VERSION ""

NS_ :

BS_:

BU_: WCM4 WCM3 WCM2 WCM VPM VLM VKM VICM VECM VDM VCU_RTOS_ETH VCU_ENTRY_ETH VCU_AGVM_ETH VCU UVM UPM TIM TEST_TOOL_1 TCP_ETH TCP TCM TCCM SRR_SRR_ETH SRR_SRR SRR_SLR_ETH SRR_SLR SRR_RR SRR_RF_ETH SRR_RF SRR_LR_CR SRR_LF_ETH SRR_LF SIB SDM SCL SBZA_R SBZA_L SBM SAM_RR SAM_RF SAM_LR SAM_LF SAM_BH SADS RadioLow_ETH RadioLow RSI_RTOS_ETH RSI RDCM PTM PLCM PFCM PDR_ETH PDR PCM PA ODS2 ODS NVM MTCM_R MTCM_L MSM_RR MSM_P MSM_LR MSM_D MSB2 MSB1 MRCM_R MRCM_L MFC LRR_RR_ETH LRR_LR_ETH LRR_CF_ETH LRR LRL_CF_ETH LIB_48V LIB1 IPC_INT IPC_GP IPC ICS_Info ICCM HVAC_FP_R HVAC_FP_F HUD_CAN HDLM FPI_RTOS_ETH FPI FOPM FCM_LC FCM EPSb EPS_1 EPSRAb EPSRAa EPS EOCM_HC_Superset EOCM_HCP2 EOCM ELM ECP_X1 ECP_S2 ECP_S ECP_MC ECP_H3 ECP_H2 ECP_H1 ECP_E ECM EBCM DMS DEFC DCM CSM_ETH CSM_AV CSM CGM_OTA_ETH CGM BSM_MH BSM_HEV BSM BCM ARS ARB APA AOS AMP ALC AHS AHL_AFL ADIMb ADIMa ACP2_MCU

BO_ 1485 PDU_5035: 8 CGM
 SG_ PAVehPathCrv : 7|12@0- (0.001,0) [-2.048|2.047] "" IPC,IPC_INT,VCU
 SG_ FourWhlDrvWrnIndReq : 9|4@0+ (1,0) [0|15] "" IPC,IPC_INT,VCU
 SG_ PAVisObjIndStatReq : 11|2@0+ (1,0) [0|3] "" IPC,IPC_INT,VCU
 SG_ XferCaseRngShfSpdLim : 21|8@0+ (1,0) [0|255] "km/h" IPC,IPC_INT,VCU
 SG_ SAP_SecAxl4WDAWDEstTrqAuth : 28|10@0+ (10,0) [0|10230] "Nm" CSM,CSM_AV,VCU
 SG_ SAP_SecAxl4WDAWDEstTrqAuth_Inv : 29|1@0+ (1,0) [0|1] "" CSM,CSM_AV,VCU
 SG_ EDADS_CrntFwdMsdGr : 34|4@0+ (1,0) [0|15] "" CSM,CSM_AV,IPC,IPC_INT,VCU
 SG_ EDADS_ShftIndSt : 41|2@0+ (1,0) [0|2] "" CSM,CSM_AV,IPC,IPC_INT,VCU
 SG_ EDADS_RcmndtFwdGr : 45|4@0+ (1,0) [0|15] "" CSM,CSM_AV,IPC,IPC_INT,VCU
 SG_ EDADS_EcoDrvShftIO : 46|1@0+ (1,0) [0|1] "" CSM,CSM_AV,IPC,IPC_INT,VCU
 SG_ PAIM_SnsrDstbdIndOn : 48|1@0+ (1,0) [0|1] "" CSM,CSM_AV,IPC,IPC_INT,VCU
 SG_ PAIM_SnsrClnIndOn : 49|1@0+ (1,0) [0|1] "" CSM,CSM_AV,IPC,IPC_INT,VCU
 SG_ PAIM_SnsrBlckdIndOn : 50|1@0+ (1,0) [0|1] "" CSM,CSM_AV,IPC,IPC_INT,VCU
 SG_ PAIM_RrOffIndOn : 51|1@0+ (1,0) [0|1] "" TCP,IPC,IPC_INT,VCU
 SG_ PAIM_OffIndOn : 52|1@0+ (1,0) [0|1] "" TCP,IPC,IPC_INT,VCU
 SG_ PAIM_FrtOffIndOn : 53|1@0+ (1,0) [0|1] "" IPC,IPC_INT,VCU
 SG_ PAIM_FaildIndOn : 54|1@0+ (1,0) [0|1] "" TCP,CSM,CSM_AV,IPC,IPC_INT,VCU
 SG_ PAIM_DsbldIndOn : 55|1@0+ (1,0) [0|1] "" CSM,CSM_AV,IPC,IPC_INT,VCU
 SG_ EngAirFiltLifeRmn : 62|7@0+ (1,0) [0|127] "%" TCP,CSM,CSM_AV,IPC,IPC_INT,VCU
 SG_ PAIM_TeenDrvrPAOffUnvIndOn : 63|1@0+ (1,0) [0|1] "" IPC,IPC_INT,VCU

BO_ 1486 PDU_5036: 8 CGM
 SG_ DrvEffInd : 7|8@0- (0.78125,0) [-100|99.2188] "%" CSM,CSM_AV,IPC,IPC_INT,VCU
 SG_ OATP_OtsAirTmpAuth : 15|8@0+ (0.5,-40) [-40|87.5] "Deg C" RadioLow,CSM,CSM_AV,VCU
 SG_ VwgVwprtReq : 18|5@0+ (1,0) [0|24] "" CSM,CSM_AV,VCU
 SG_ SAP_SecAxlOpMdAuth : 22|4@0+ (1,0) [0|9] "" TCP,CSM,CSM_AV,IPC,IPC_INT,VCU
 SG_ SAP_SecAxlOpMdAuth_Inv : 23|1@0+ (1,0) [0|1] "" CSM,CSM_AV,VCU
 SG_ EnrgMgtLdShdRq : 24|4@0+ (1,0) [0|4] "" TCP,CSM,CSM_AV,VCU,WCM,WCM2,WCM3,WCM4
 SG_ VwgVwprtSts : 29|5@0+ (1,0) [0|24] "" CSM,CSM_AV,VCU
 SG_ MemCmd : 32|4@0+ (1,0) [0|15] "" CSM,CSM_AV,IPC,IPC_INT,VCU
 SG_ FrntPsStbltRmIndReq : 36|4@0+ (1,0) [0|7] "" TCP,CSM,CSM_AV,IPC,IPC_INT,VCU
 SG_ TireLFLoTracIndOn : 40|1@0+ (1,0) [0|1] "" VKM,CSM,CSM_AV,IPC,IPC_INT,VCU
 SG_ MemIdfrIgnOnIndReq : 44|4@0+ (1,0) [0|8] "" IPC,IPC_INT,VCU
 SG_ AutMemRclCstCurSetVal : 49|3@0+ (1,0) [0|6] "" RadioLow,CSM,CSM_AV,VCU
 SG_ AdpLghtRspTypCstCurSetVal : 52|3@0+ (1,0) [0|7] "" RadioLow,CSM,CSM_AV,VCU
 SG_ TireRRLoTracIndOn : 53|1@0+ (1,0) [0|1] "" VKM,CSM,CSM_AV,IPC,IPC_INT,VCU
 SG_ TireRFLoTracIndOn : 54|1@0+ (1,0) [0|1] "" VKM,CSM,CSM_AV,IPC,IPC_INT,VCU
 SG_ TireLRLoTracIndOn : 55|1@0+ (1,0) [0|1] "" VKM,CSM,CSM_AV,IPC,IPC_INT,VCU
 SG_ AutMemRclCstStAvl : 56|1@0+ (1,0) [0|1] "" RadioLow,CSM,CSM_AV,VCU
 SG_ CTDStat : 59|3@0+ (1,0) [0|5] "" TCP,VKM,VCU
 SG_ BrkSysHillStrtAsstStat : 62|3@0+ (1,0) [0|7] "" CSM,CSM_AV,VCU

BO_ 1487 PDU_5037: 8 CGM
 SG_ CnvtblTpWndMtnReq : 1|3@0+ (1,0) [0|4] "" CSM,CSM_AV,VCU
 SG_ CnvtBkWndPstnSts : 4|3@0+ (1,0) [0|7] "" CSM,CSM_AV,VCU
 SG_ CTGI2P_CnvtTopStsAuth : 7|3@0+ (1,0) [0|5] "" AMP,RadioLow,VKM,CSM,CSM_AV,IPC,IPC_INT,VCU
 SG_ FrntPsStBltRmOccStat_Inv : 8|1@0+ (1,0) [0|1] "" RadioLow,TCP,CSM,CSM_AV,VCU
 SG_ EsyExtCstCurSetVal : 11|3@0+ (1,0) [0|7] "" RadioLow,CSM,CSM_AV,VCU
 SG_ CrgBedVwAutoLgtCstCurrSetVal : 14|3@0+ (1,0) [0|7] "" RadioLow,CSM,CSM_AV,VCU
 SG_ FrwdVhImAlrtIndRqst : 18|3@0+ (1,0) [0|7] "" RadioLow,TCP,CSM,CSM_AV,IPC,IPC_INT,VCU
 SG_ FrtRdHgtGPSCstCurrSetVal : 21|3@0+ (1,0) [0|7] "" RadioLow,CSM,CSM_AV,VCU
 SG_ FrntPsStBltRmOccStat : 23|2@0+ (1,0) [0|2] "" FPI,RSI,RadioLow,TCP,CSM,CSM_AV,VCU
 SG_ HybStatElecVehModeOvrrd : 25|3@0+ (1,0) [0|7] "" IPC,IPC_INT,VCU
 SG_ HSP_DrvAlrtTypCstCurrSetValAuth : 28|3@0+ (1,0) [0|2] "" RadioLow,TCP,CSM,CSM_AV,VCU
 SG_ GoNotfrCstCrStVal : 31|3@0+ (1,0) [0|7] "" RadioLow,CSM,CSM_AV,VCU
 SG_ LtRtHnTrCstCurSetVal : 32|3@0+ (1,0) [0|7] "" RadioLow,CSM,CSM_AV,VCU
 SG_ LnDtWrnCntrlFtrSt : 35|3@0+ (1,0) [0|4] "" TCP,CSM,CSM_AV,VCU
 SG_ JckKnfDtnCstCurrSetVal : 38|3@0+ (1,0) [0|7] "" RadioLow,CSM,CSM_AV,VCU
 SG_ LvlgSysEntEgrsMdCstCurrSetVal : 42|3@0+ (1,0) [0|7] "" RadioLow,CSM,CSM_AV,VCU
 SG_ LvlgSysAlgnMdCstCurrSetVal : 45|3@0+ (1,0) [0|7] "" RadioLow,CSM,CSM_AV,VCU
 SG_ PrkAsstONOFFCstCrStVal : 49|3@0+ (1,0) [0|7] "" RadioLow,CSM,CSM_AV,VCU
 SG_ NghtVsnSysStat : 52|3@0+ (1,0) [0|7] "" IPC,IPC_INT,VCU
 SG_ LvlgSysServMdCstCurrSetVal : 55|3@0+ (1,0) [0|7] "" RadioLow,CSM,CSM_AV,VCU
 SG_ AutoHldEnbld : 56|1@0+ (1,0) [0|1] "" IPC,IPC_INT,VCU
 SG_ PrkAsstTrHtchPsntCstCrStVal : 59|3@0+ (1,0) [0|7] "" RadioLow,CSM,CSM_AV,VCU
 SG_ PrkAsstStat : 62|3@0+ (1,0) [0|7] "" RadioLow,CSM,CSM_AV,VCU

BO_ 1488 PDU_5038: 8 CGM
 SG_ PrsnlMdStrCstmCurSetVal : 1|3@0+ (1,0) [0|7] "" RadioLow,TCP,CSM,CSM_AV,VCU
 SG_ PrsnlMdSpnCstmCurSetVal : 4|3@0+ (1,0) [0|7] "" RadioLow,TCP,CSM,CSM_AV,VCU
 SG_ PrsnlMdSndCstmCurSetVal : 7|3@0+ (1,0) [0|7] "" RadioLow,CSM,CSM_AV,VCU
 SG_ RideHghtSeltn3Name : 8|3@0+ (1,0) [0|7] "" IPC,IPC_INT,VCU
 SG_ RideHghtSeltn2Name : 11|3@0+ (1,0) [0|7] "" IPC,IPC_INT,VCU
 SG_ RideHghtSeltn1Name : 14|3@0+ (1,0) [0|7] "" IPC,IPC_INT,VCU
 SG_ RideHghtSeltn5Name : 18|3@0+ (1,0) [0|7] "" IPC,IPC_INT,VCU
 SG_ RideHghtSeltn4Name : 21|3@0+ (1,0) [0|7] "" IPC,IPC_INT,VCU
 SG_ RideHghtSeltn8Name : 25|3@0+ (1,0) [0|7] "" IPC,IPC_INT,VCU
 SG_ RideHghtSeltn7Name : 28|3@0+ (1,0) [0|7] "" IPC,IPC_INT,VCU
 SG_ RideHghtSeltn6Name : 31|3@0+ (1,0) [0|7] "" IPC,IPC_INT,VCU
 SG_ RrVwPrkAstSymCsCrStVal : 32|3@0+ (1,0) [0|7] "" RadioLow,CSM,CSM_AV,VCU
 SG_ RnngBrdManDplyCstCurrSetVal : 35|3@0+ (1,0) [0|7] "" RadioLow,CSM,CSM_AV,VCU
 SG_ RnngBrdAutoDplyCstCurrSetVal : 38|3@0+ (1,0) [0|6] "" RadioLow,CSM,CSM_AV,VCU
 SG_ StBltShfIntlkCstCurrSetVal : 42|3@0+ (1,0) [0|7] "" RadioLow,CSM,CSM_AV,VCU
 SG_ SrrndVwLghtCsCrStVal : 45|3@0+ (1,0) [0|7] "" RadioLow,CSM,CSM_AV,VCU
 SG_ TrlrMirVidGdlnsCstCurrSetVal : 49|3@0+ (1,0) [0|7] "" RadioLow,CSM,CSM_AV,VCU
 SG_ TnDrvStBltShfIntlkCstCurrSetVal : 52|3@0+ (1,0) [0|7] "" RadioLow,TCP,CSM,CSM_AV,VCU
 SG_ StBltTghtngCstCrStVal : 55|3@0+ (1,0) [0|7] "" RadioLow,CSM,CSM_AV,VCU
 SG_ BrkLtsAtv : 56|1@0+ (1,0) [0|1] "" TCP,CSM,CSM_AV,VCU
 SG_ APAExtPrkSftBtnRqst : 58|2@0+ (1,0) [0|3] "" RadioLow,CSM,CSM_AV,VCU
 SG_ APACrssFrntInSftBtnRqst : 60|2@0+ (1,0) [0|3] "" RadioLow,CSM,CSM_AV,VCU
 SG_ APACrssBckInSftBtnRqst : 62|2@0+ (1,0) [0|3] "" RadioLow,CSM,CSM_AV,VCU

BO_ 1489 PDU_5039: 8 CGM
 SG_ APASrchSftBtnRqst : 1|2@0+ (1,0) [0|3] "" RadioLow,CSM,CSM_AV,VCU
 SG_ APARghtSftBtnRqst : 3|2@0+ (1,0) [0|3] "" RadioLow,CSM,CSM_AV,IPC,IPC_INT,VCU
 SG_ APAPrllPrkSftBtnRqst : 5|2@0+ (1,0) [0|3] "" RadioLow,CSM,CSM_AV,VCU
 SG_ APALftSftBtnRqst : 7|2@0+ (1,0) [0|3] "" RadioLow,CSM,CSM_AV,IPC,IPC_INT,VCU
 SG_ EngCmptAjr : 8|1@0+ (1,0) [0|1] "" TCP,VKM,CSM,CSM_AV,IPC,IPC_INT,VCU
 SG_ EngCmptAjr_Inv : 9|1@0+ (1,0) [0|1] "" VKM,IPC,IPC_INT,VCU
 SG_ ElvtdIdlCstCrStVal : 11|2@0+ (1,0) [0|2] "" RadioLow,CSM,CSM_AV,IPC,IPC_INT,VCU
 SG_ DrvDrAjrStat : 12|1@0+ (1,0) [0|1] "" AMP,RadioLow,TCP,VKM,CSM,CSM_AV,IPC,IPC_INT,VCU
 SG_ DrvDrAjrStat_Inv : 13|1@0+ (1,0) [0|1] "" TCP,VKM,CSM,CSM_AV,IPC,IPC_INT,VCU
 SG_ CoDrvDrAjrStat : 14|1@0+ (1,0) [0|1] "" AMP,RadioLow,TCP,VKM,CSM,CSM_AV,IPC,IPC_INT,VCU
 SG_ CoDrvDrAjrStat_Inv : 15|1@0+ (1,0) [0|1] "" TCP,VKM,CSM,CSM_AV,VCU
 SG_ LftglsAjrStat : 16|1@0+ (1,0) [0|1] "" AMP,VKM,IPC,IPC_INT,VCU
 SG_ LftglsAjrStat_Inv : 17|1@0+ (1,0) [0|1] "" AMP,VKM,IPC,IPC_INT,VCU
 SG_ LRDrAjrStat : 18|1@0+ (1,0) [0|1] "" AMP,RadioLow,TCP,VKM,CSM,CSM_AV,IPC,IPC_INT,VCU
 SG_ LRDrAjrStat_Inv : 19|1@0+ (1,0) [0|1] "" TCP,VKM,CSM,CSM_AV,VCU
 SG_ InvsblTrlrOprtlSts : 21|2@0+ (1,0) [0|3] "" CSM,CSM_AV,VCU
 SG_ HSP_HptcStOprtlStsAuth : 23|2@0+ (1,0) [0|2] "" TCP,VCU
 SG_ SAP_SecAxl4WDAWDStatAuth : 25|2@0+ (1,0) [0|3] "" CSM,CSM_AV,VCU
 SG_ RRDrAjrStat : 26|1@0+ (1,0) [0|1] "" AMP,RadioLow,TCP,VKM,CSM,CSM_AV,IPC,IPC_INT,VCU
 SG_ RRDrAjrStat_Inv : 27|1@0+ (1,0) [0|1] "" TCP,VKM,CSM,CSM_AV,IPC,IPC_INT,VCU
 SG_ LogisticModeStatus : 29|2@0+ (1,0) [0|3] "" HVAC_FP_F,HVAC_FP_R,PDR,RadioLow,VKM,CSM,CSM_AV,VCU
 SG_ LnCntrEsclnSts : 31|2@0+ (1,0) [0|3] "" TCP
 SG_ CIBAutoBrkReqActv : 32|1@0+ (1,0) [0|1] "" TCP
 SG_ CIBAutoBrkRelIndOn : 33|1@0+ (1,0) [0|1] "" IPC,IPC_INT,VCU
 SG_ APAVMR_SloDnIndOn : 34|1@0+ (1,0) [0|1] "" IPC,IPC_INT,VCU
 SG_ APAVMR_NAvalIndOn : 35|1@0+ (1,0) [0|1] "" TCP,IPC,IPC_INT,VCU
 SG_ TrnSwAct : 37|2@0+ (1,0) [0|2] "" VKM,CSM,CSM_AV,IPC,IPC_INT,VCU
 SG_ TrlrTirePresProfXferSts : 39|2@0+ (1,0) [0|3] "" CSM,CSM_AV,VCU
 SG_ CkSoftTpIO : 40|1@0+ (1,0) [0|1] "" CSM,CSM_AV,IPC,IPC_INT,VCU
 SG_ CkRrPrkLmpIndOn : 41|1@0+ (1,0) [0|1] "" TCP,VKM,IPC,IPC_INT,VCU
 SG_ CkLoBmsIndOn : 42|1@0+ (1,0) [0|1] "" RadioLow,TCP,CSM,CSM_AV,IPC,IPC_INT,VCU
 SG_ CkFrtPrkLmpsIndOn : 43|1@0+ (1,0) [0|1] "" TCP,CSM,CSM_AV,IPC,IPC_INT,VCU
 SG_ CkFgLmpsIndOn : 44|1@0+ (1,0) [0|1] "" VKM,IPC,IPC_INT,VCU
 SG_ CkDyTmRnngLmpsIndOn : 45|1@0+ (1,0) [0|1] "" TCP,CSM,CSM_AV,IPC,IPC_INT,VCU
 SG_ CkCrnrLmpsIndOn : 46|1@0+ (1,0) [0|1] "" IPC,IPC_INT,VCU
 SG_ CkBrkLmpsIndOn : 47|1@0+ (1,0) [0|1] "" VKM,CSM,CSM_AV,IPC,IPC_INT,VCU
 SG_ DrMtzdStBltUnIndOn : 48|1@0+ (1,0) [0|1] "" CSM,CSM_AV,IPC,IPC_INT,VCU
 SG_ DrMtzdStBltFldIndOn : 49|1@0+ (1,0) [0|1] "" CSM,CSM_AV,IPC,IPC_INT,VCU
 SG_ DispSmrtTowVidOn : 50|1@0+ (1,0) [0|1] "" CSM,CSM_AV,VCU
 SG_ Deg360VidFtrPrsnt : 51|1@0+ (1,0) [0|1] "" CSM,CSM_AV,VCU
 SG_ DRLAct : 52|1@0+ (1,0) [0|1] "" TCP,VKM,CSM,CSM_AV,IPC,IPC_INT,VCU
 SG_ CrgBedVwAutoLgtCstSetAval : 53|1@0+ (1,0) [0|1] "" RadioLow,CSM,CSM_AV,VCU
 SG_ CnvtblTopTneuAjrStat : 54|1@0+ (1,0) [0|1] "" AMP,VKM
 SG_ ClsTrnkLidIO : 55|1@0+ (1,0) [0|1] "" CSM,CSM_AV,IPC,IPC_INT,VCU
 SG_ FrntPsStbltRmIndOn : 56|1@0+ (1,0) [0|1] "" TCP,IPC,IPC_INT,VCU
 SG_ FrntPsMtzdStBltUnIndOn : 57|1@0+ (1,0) [0|1] "" CSM,CSM_AV,IPC,IPC_INT,VCU
 SG_ FrntPsMtzdStBltFldIndOn : 58|1@0+ (1,0) [0|1] "" CSM,CSM_AV,IPC,IPC_INT,VCU
 SG_ EsyExtCstStAvl : 59|1@0+ (1,0) [0|1] "" RadioLow,CSM,CSM_AV,VCU
 SG_ ESCLTrntheStrWheelWhlStrtgIO : 60|1@0+ (1,0) [0|1] "" IPC,IPC_INT,VCU
 SG_ DsplyTrgVdOn : 61|1@0+ (1,0) [0|1] "" RadioLow,CSM,CSM_AV,VCU
 SG_ DspFrnt360CmrON : 62|1@0+ (1,0) [0|1] "" RadioLow,CSM,CSM_AV,VCU
 SG_ DrvStBltRmIndOn : 63|1@0+ (1,0) [0|1] "" TCP,IPC,IPC_INT,VCU

BO_ 1490 PDU_5040: 8 CGM
 SG_ JckKnfDtnCstSetAval : 0|1@0+ (1,0) [0|1] "" RadioLow,CSM,CSM_AV,VCU
 SG_ HiBmOtgIndOn : 1|1@0+ (1,0) [0|1] "" CSM,CSM_AV,IPC,IPC_INT,VCU
 SG_ HSP_HptcStPrsntAuth : 2|1@0+ (1,0) [0|1] "" TCP,CSM,CSM_AV,VCU
 SG_ GrdBrkgAct : 3|1@0+ (1,0) [0|1] "" CSM,CSM_AV,IPC,IPC_INT,VCU
 SG_ GoNotfrCstStAvl : 4|1@0+ (1,0) [0|1] "" RadioLow,CSM,CSM_AV,VCU
 SG_ FrwdVhHdwyAlrtIndOn : 5|1@0+ (1,0) [0|1] "" TCP,CSM,CSM_AV,IPC,IPC_INT,VCU
 SG_ FrtStrgeCmptAjr : 6|1@0+ (1,0) [0|1] "" TCP,VKM
 SG_ FrtRdHgtGPSCstSetAval : 7|1@0+ (1,0) [0|1] "" RadioLow,CSM,CSM_AV,VCU
 SG_ LvlgSysEntEgrsMdCstSetAval : 8|1@0+ (1,0) [0|1] "" RadioLow,CSM,CSM_AV,VCU
 SG_ LvlgSysAlgnMdCstSetSelable : 9|1@0+ (1,0) [0|1] "" RadioLow,CSM,CSM_AV,VCU
 SG_ LvlgSysAlgnMdCstSetAval : 10|1@0+ (1,0) [0|1] "" RadioLow,CSM,CSM_AV,VCU
 SG_ LtRtHnTrCstStAvl : 11|1@0+ (1,0) [0|1] "" RadioLow,CSM,CSM_AV,VCU
 SG_ LnCntrMisuseCond : 12|1@0+ (1,0) [0|1] "" TCP
 SG_ LnCntrDrvAwrIndOn : 13|1@0+ (1,0) [0|1] "" TCP
 SG_ LicLpOtIO : 14|1@0+ (1,0) [0|1] "" RadioLow,TCP,VKM,CSM,CSM_AV,IPC,IPC_INT,VCU
 SG_ LSCMBAutoBrkRlsIndOn : 15|1@0+ (1,0) [0|1] "" IPC,IPC_INT,VCU
 SG_ PrkAsstTrHtchPsntCstStAvl : 16|1@0+ (1,0) [0|1] "" RadioLow,CSM,CSM_AV,VCU
 SG_ PrkAsstONOFFCstStAvl : 17|1@0+ (1,0) [0|1] "" RadioLow,CSM,CSM_AV,VCU
 SG_ PedtrnProtSysDpl : 18|1@0+ (1,0) [0|1] "" IPC,IPC_INT,VCU
 SG_ NoSDCrdPrIndOn : 19|1@0+ (1,0) [0|1] "" RadioLow,CSM,CSM_AV,VCU
 SG_ MovblTpServRqrdIO : 20|1@0+ (1,0) [0|1] "" IPC,IPC_INT,VCU
 SG_ MovblTpNormzRqrdIO : 21|1@0+ (1,0) [0|1] "" IPC,IPC_INT,VCU
 SG_ LvlgSysServMdCstSetSelable : 22|1@0+ (1,0) [0|1] "" RadioLow,CSM,CSM_AV,VCU
 SG_ LvlgSysServMdCstSetAval : 23|1@0+ (1,0) [0|1] "" RadioLow,CSM,CSM_AV,VCU
 SG_ RnngBrdAutoDplyCstSetAval : 24|1@0+ (1,0) [0|1] "" RadioLow,CSM,CSM_AV,VCU
 SG_ RegVltgCtlEngyRcvryActv : 25|1@0+ (1,0) [0|1] "" IPC,IPC_INT,VCU
 SG_ RearPsStbltVisIndMd : 26|1@0+ (1,0) [0|1] "" CSM,CSM_AV,IPC,IPC_INT,VCU
 SG_ RIMUnIndOn : 27|1@0+ (1,0) [0|1] "" CSM,CSM_AV,IPC,IPC_INT,VCU
 SG_ RIMONIndOn : 28|1@0+ (1,0) [0|1] "" IPC,IPC_INT,VCU
 SG_ RIMOFFIndOn : 29|1@0+ (1,0) [0|1] "" CSM,CSM_AV,IPC,IPC_INT,VCU
 SG_ PrsnlMdStrCstmSetAv : 30|1@0+ (1,0) [0|1] "" RadioLow,TCP,CSM,CSM_AV,VCU
 SG_ PrkBrkSwAtv : 31|1@0+ (1,0) [0|1] "" RadioLow,TCP,VKM,CSM,CSM_AV,IPC,IPC_INT,VCU
 SG_ RvLpOtIO : 32|1@0+ (1,0) [0|1] "" RadioLow,TCP,VKM,CSM,CSM_AV,IPC,IPC_INT,VCU
 SG_ RstrntDplyIndOn : 33|1@0+ (1,0) [0|1] "" IPC,IPC_INT,VCU
 SG_ RrVwPrkAstSymCsStAvl : 34|1@0+ (1,0) [0|1] "" RadioLow,CSM,CSM_AV,VCU
 SG_ RrFgLpOtIO : 35|1@0+ (1,0) [0|1] "" TCP,VKM,CSM,CSM_AV,IPC,IPC_INT,VCU
 SG_ RrAxlTmpInhIO : 36|1@0+ (1,0) [0|1] "" CSM,CSM_AV,IPC,IPC_INT,VCU
 SG_ RrAxlMlfIO : 37|1@0+ (1,0) [0|1] "" CSM,CSM_AV,IPC,IPC_INT,VCU
 SG_ RnngBrdManDplyCstSetSelbl : 38|1@0+ (1,0) [0|1] "" RadioLow,CSM,CSM_AV,VCU
 SG_ RnngBrdManDplyCstSetAval : 39|1@0+ (1,0) [0|1] "" RadioLow,CSM,CSM_AV,VCU
 SG_ SftTpMchnOvhtIO : 42|1@0+ (1,0) [0|1] "" CSM,CSM_AV,IPC,IPC_INT,VCU
 SG_ SftTpLtcIO : 43|1@0+ (1,0) [0|1] "" CSM,CSM_AV,IPC,IPC_INT,VCU
 SG_ ServPedtrnFrndlyAlrtIndOn : 44|1@0+ (1,0) [0|1] "" IPC,IPC_INT,VCU
 SG_ SerRideSysIO : 45|1@0+ (1,0) [0|1] "" TCP,CSM,CSM_AV,IPC,IPC_INT,VCU
 SG_ SDCrdFllIndOn : 46|1@0+ (1,0) [0|1] "" RadioLow,CSM,CSM_AV,VCU
 SG_ SDCrdErrIndOn : 47|1@0+ (1,0) [0|1] "" RadioLow,CSM,CSM_AV,VCU
 SG_ TrlrMirVidEnblCstSetAval : 48|1@0+ (1,0) [0|1] "" RadioLow,CSM,CSM_AV,VCU
 SG_ TrlrBrkDtd : 49|1@0+ (1,0) [0|1] "" CSM,CSM_AV,IPC,IPC_INT,VCU
 SG_ TrgrdVidRcrdrFtrPrsnt : 50|1@0+ (1,0) [0|1] "" CSM,CSM_AV,VCU
 SG_ TnDrvStBltShfIntlkCstSetAval : 51|1@0+ (1,0) [0|1] "" RadioLow,CSM,CSM_AV,VCU
 SG_ TargaTopAjrStat : 52|1@0+ (1,0) [0|1] "" AMP,RadioLow,CSM,CSM_AV,VCU
 SG_ StBltTghtngCstStAv : 53|1@0+ (1,0) [0|1] "" RadioLow,CSM,CSM_AV,VCU
 SG_ StBltShfIntlkCstSetAval : 54|1@0+ (1,0) [0|1] "" RadioLow,CSM,CSM_AV,VCU
 SG_ SrrndVwLghtCsStAvl : 55|1@0+ (1,0) [0|1] "" RadioLow,CSM,CSM_AV,VCU
 SG_ FrtStrgeCmptAjr_Inv : 59|1@0+ (1,0) [0|1] "" TCP,VKM
 SG_ WprFrActFltdStat : 60|1@0+ (1,0) [0|1] "" TCP,CSM,CSM_AV,VCU
 SG_ TrnSigSwRtActv : 61|1@0+ (1,0) [0|1] "" TCP,CSM,CSM_AV,VCU
 SG_ TrnSigSwLtActv : 62|1@0+ (1,0) [0|1] "" TCP,CSM,CSM_AV,VCU
 SG_ TrlrMirVidGdlnsCstSetAval : 63|1@0+ (1,0) [0|1] "" RadioLow,CSM,CSM_AV,VCU

BO_ 1526 PDU_5041: 8 CGM
 SG_ TirePrsLF : 6|8@0+ (4,0) [0|1020] "kPaG" FPI,PDR,RSI,RadioLow,TCP,VKM,CSM,CSM_AV,IPC,IPC_INT,VCU
 SG_ TireLocatnWarnEn : 7|1@0+ (1,0) [0|1] "" RadioLow,CSM,CSM_AV,IPC,IPC_INT,VCU
 SG_ TirePrsLR : 13|8@0+ (4,0) [0|1020] "kPaG" FPI,PDR,RSI,RadioLow,TCP,VKM,CSM,CSM_AV,IPC,IPC_INT,VCU
 SG_ TirePrsLF_Inv : 14|1@0+ (1,0) [0|1] "" FPI,PDR,RSI,RadioLow,TCP,VKM,CSM,CSM_AV,IPC,IPC_INT,VCU
 SG_ TirePrsRF : 20|8@0+ (4,0) [0|1020] "kPaG" FPI,PDR,RSI,RadioLow,TCP,VKM,CSM,CSM_AV,IPC,IPC_INT,VCU
 SG_ TirePrsLR_Inv : 21|1@0+ (1,0) [0|1] "" FPI,PDR,RSI,RadioLow,TCP,VKM,CSM,CSM_AV,IPC,IPC_INT,VCU
 SG_ TirePrsRR : 27|8@0+ (4,0) [0|1020] "kPaG" FPI,PDR,RSI,RadioLow,TCP,VKM,CSM,CSM_AV,IPC,IPC_INT,VCU
 SG_ TirePrsRF_Inv : 28|1@0+ (1,0) [0|1] "" FPI,PDR,RSI,RadioLow,TCP,VKM,CSM,CSM_AV,IPC,IPC_INT,VCU
 SG_ TirePrsStatLF : 34|3@0+ (1,0) [0|5] "" AMP,FPI,PDR,RSI,RadioLow,TCP,VKM,CSM,CSM_AV,IPC,IPC_INT,VCU
 SG_ TirePrsRR_Inv : 35|1@0+ (1,0) [0|1] "" FPI,PDR,RSI,RadioLow,TCP,VKM,CSM,CSM_AV,IPC,IPC_INT,VCU
 SG_ TirePrsStatRF : 42|3@0+ (1,0) [0|5] "" AMP,FPI,PDR,RSI,RadioLow,TCP,VKM,CSM,CSM_AV,IPC,IPC_INT,VCU
 SG_ TirePrsStatLR_Inv : 43|1@0+ (1,0) [0|1] "" FPI,RSI,RadioLow,VKM,CSM,CSM_AV,IPC,IPC_INT,VCU
 SG_ TirePrsStatLR : 46|3@0+ (1,0) [0|5] "" AMP,FPI,PDR,RSI,RadioLow,TCP,VKM,CSM,CSM_AV,IPC,IPC_INT,VCU
 SG_ TirePrsStatLF_Inv : 47|1@0+ (1,0) [0|1] "" FPI,RSI,RadioLow,VKM,CSM,CSM_AV,IPC,IPC_INT,VCU
 SG_ RrBlwCmd : 50|10@0+ (0.09765,0) [0|99.8959] "%" HVAC_FP_R,VCU
 SG_ TirePrsStatRR_Inv : 51|1@0+ (1,0) [0|1] "" FPI,RSI,RadioLow,VKM,CSM,CSM_AV,IPC,IPC_INT,VCU
 SG_ TirePrsStatRR : 54|3@0+ (1,0) [0|5] "" AMP,FPI,PDR,RSI,RadioLow,TCP,VKM,CSM,CSM_AV,IPC,IPC_INT,VCU
 SG_ TirePrsStatRF_Inv : 55|1@0+ (1,0) [0|1] "" FPI,RSI,RadioLow,VKM,CSM,CSM_AV,IPC,IPC_INT,VCU
 SG_ ACCDsngIndOn : 56|1@0+ (1,0) [0|1] "" TCP,CSM,CSM_AV,IPC,IPC_INT,VCU

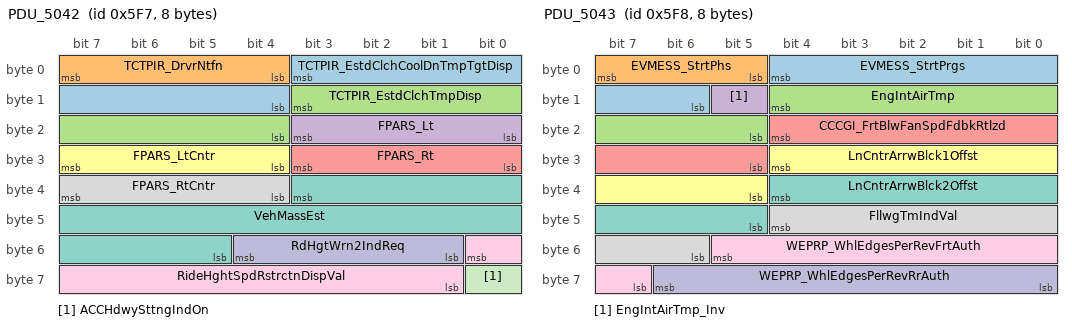
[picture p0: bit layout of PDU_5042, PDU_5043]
BO_ 1527 PDU_5042: 8 CGM
 SG_ TCTPIR_EstdClchCoolDnTmpTgtDisp : 3|8@0+ (0.392157,0) [0|100] "%" IPC,IPC_INT,VCU
 SG_ TCTPIR_DrvrNtfn : 7|4@0+ (1,0) [0|8] "" IPC,IPC_INT,VCU
 SG_ TCTPIR_EstdClchTmpDisp : 11|8@0+ (0.392157,0) [0|100] "%" IPC,IPC_INT,VCU
 SG_ FPARS_Lt : 19|4@0+ (1,0) [0|14] "" CSM,CSM_AV,IPC,IPC_INT,VCU
 SG_ FPARS_Rt : 27|4@0+ (1,0) [0|14] "" CSM,CSM_AV,IPC,IPC_INT,VCU
 SG_ FPARS_LtCntr : 31|4@0+ (1,0) [0|14] "" CSM,CSM_AV,IPC,IPC_INT,VCU
 SG_ VehMassEst : 35|15@0+ (1,0) [0|32767] "kg" CSM,CSM_AV,VCU
 SG_ FPARS_RtCntr : 39|4@0+ (1,0) [0|14] "" CSM,CSM_AV,IPC,IPC_INT,VCU
 SG_ RideHghtSpdRstrctnDispVal : 48|8@0+ (1,0) [0|255] "km/h" IPC,IPC_INT,VCU
 SG_ RdHgtWrn2IndReq : 52|4@0+ (1,0) [0|15] "" IPC,IPC_INT,VCU
 SG_ ACCHdwySttngIndOn : 56|1@0+ (1,0) [0|1] "" TCP

BO_ 1528 PDU_5043: 8 CGM
 SG_ EVMESS_StrtPrgs : 4|7@0+ (1,0) [0|127] "%" IPC,IPC_INT,VCU
 SG_ EVMESS_StrtPhs : 7|3@0+ (1,0) [0|5] "" IPC,IPC_INT,VCU
 SG_ EngIntAirTmp : 12|8@0+ (1,-40) [-40|215] "deg C" PDR,TCP,CSM,CSM_AV,VCU
 SG_ EngIntAirTmp_Inv : 13|1@0+ (1,0) [0|1] "" PDR,TCP,CSM,CSM_AV,VCU
 SG_ CCCGI_FrtBlwFanSpdFdbkRtlzd : 20|8@0+ (0.392157,0) [0|100] "%" CSM,CSM_AV,IPC,IPC_INT,VCU
 SG_ LnCntrArrwBlck1Offst : 28|8@0- (1,0) [-128|127] "" TCP
 SG_ LnCntrArrwBlck2Offst : 36|8@0- (1,0) [-128|127] "" TCP
 SG_ FllwgTmIndVal : 44|7@0+ (0.1,0) [0|12.7] "s" TCP,CSM,CSM_AV,IPC,IPC_INT,VCU
 SG_ WEPRP_WhlEdgesPerRevFrtAuth : 53|7@0+ (1,30) [30|157] "edges" TCP,CSM,CSM_AV,VCU
 SG_ WEPRP_WhlEdgesPerRevRrAuth : 62|7@0+ (1,30) [30|157] "edges" TCP,CSM,CSM_AV,VCU

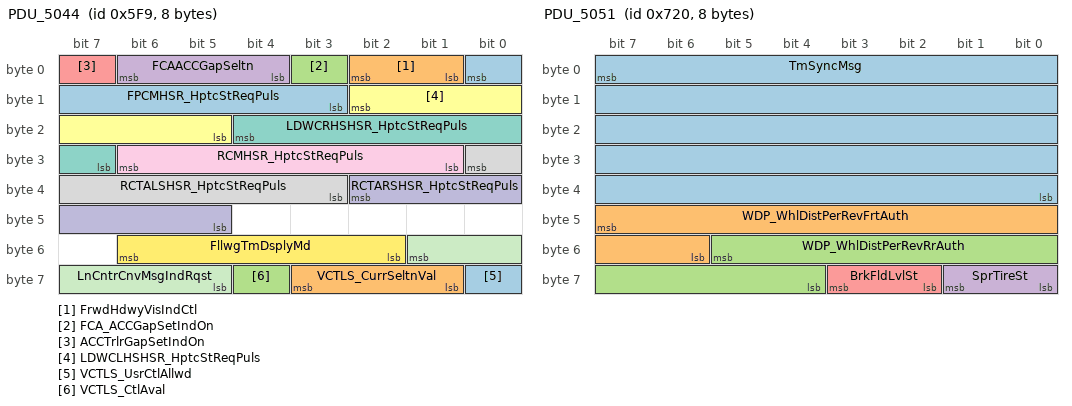
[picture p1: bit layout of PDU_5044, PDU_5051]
BO_ 1529 PDU_5044: 8 CGM
 SG_ FPCMHSR_HptcStReqPuls : 0|6@0+ (1,0) [0|63] "pulses" CSM,CSM_AV,VCU
 SG_ FrwdHdwyVisIndCtl : 2|2@0+ (1,0) [0|2] "" IPC,IPC_INT,VCU
 SG_ FCA_ACCGapSetIndOn : 3|1@0+ (1,0) [0|1] "" IPC,IPC_INT,VCU
 SG_ FCAACCGapSeltn : 6|3@0+ (1,0) [0|4] "" CSM,CSM_AV,IPC,IPC_INT,VCU
 SG_ ACCTrlrGapSetIndOn : 7|1@0+ (1,0) [0|1] "" IPC,IPC_INT,VCU
 SG_ LDWCLHSHSR_HptcStReqPuls : 10|6@0+ (1,0) [0|63] "pulses" CSM,CSM_AV,VCU
 SG_ LDWCRHSHSR_HptcStReqPuls : 20|6@0+ (1,0) [0|63] "pulses" CSM,CSM_AV,VCU
 SG_ RCTALSHSR_HptcStReqPuls : 24|6@0+ (1,0) [0|63] "pulses" CSM,CSM_AV,VCU
 SG_ RCMHSR_HptcStReqPuls : 30|6@0+ (1,0) [0|63] "pulses" CSM,CSM_AV,VCU
 SG_ RCTARSHSR_HptcStReqPuls : 34|6@0+ (1,0) [0|63] "pulses" CSM,CSM_AV,VCU
 SG_ LnCntrCnvMsgIndRqst : 49|5@0+ (1,0) [0|21] "" TCP,CSM,CSM_AV,VCU
 SG_ FllwgTmDsplyMd : 54|5@0+ (1,0) [0|4] "" CSM,CSM_AV,IPC,IPC_INT,VCU
 SG_ VCTLS_UsrCtlAllwd : 56|1@0+ (1,0) [0|1] "" VCU
 SG_ VCTLS_CurrSeltnVal : 59|3@0+ (1,0) [0|4] "" VCU
 SG_ VCTLS_CtlAval : 60|1@0+ (1,0) [0|1] "" VCU

BO_ 1530 PDU_5045: 8 CGM
 SG_ AirbgStsIndReq : 3|4@0+ (1,0) [0|7] "" CSM,CSM_AV,IPC,IPC_INT,VCU
 SG_ AdpAndCnvntlCruzCtlIndReq : 7|4@0+ (1,0) [0|9] "" CSM,CSM_AV,IPC,IPC_INT,VCU
 SG_ DrvStBltRmIndReq : 11|4@0+ (1,0) [0|7] "" CSM,CSM_AV,IPC,IPC_INT,VCU
 SG_ BSSIP_BrkAsstBrkBstStsAuth : 15|4@0+ (1,0) [0|9] "" TCP
 SG_ SGI2P_AirSpnsnRdHghtActlStsAuth : 19|4@0+ (1,0) [0|13] "" CSM,CSM_AV,VCU
 SG_ RdHgtStatIndReq : 23|4@0+ (1,0) [0|13] "" CSM,CSM_AV,IPC,IPC_INT,VCU
 SG_ AutoLnChgCstCurrSetVal : 24|3@0+ (1,0) [0|4] "" CSM,CSM_AV,VCU
 SG_ ArtcldRnngBrdSt : 27|3@0+ (1,0) [0|6] "" IPC,IPC_INT,VCU
 SG_ LAOA_LatAsstOffOptAval : 28|1@0+ (1,0) [0|1] "" IPC,IPC_INT,VCU
 SG_ LAOA_LatAsstLKAOptAval : 29|1@0+ (1,0) [0|1] "" IPC,IPC_INT,VCU
 SG_ LAOA_LatAsstLDWOptAval : 30|1@0+ (1,0) [0|1] "" IPC,IPC_INT,VCU
 SG_ LAOA_LatAsstHoLFOptAval : 31|1@0+ (1,0) [0|1] "" IPC,IPC_INT,VCU
 SG_ AxlLckUnavailIndReq : 34|3@0+ (1,0) [0|7] "" IPC,IPC_INT,VCU
 SG_ AutoTrnspHdActvnCstCurrSetVal : 37|3@0+ (1,0) [0|2] "" CSM,CSM_AV,VCU
 SG_ DslExhFldDiagWrnIdRq : 41|3@0+ (1,0) [0|7] "" IPC,IPC_INT,VCU
 SG_ DrvrSeltdSpdLmtrIndReq : 44|3@0+ (1,0) [0|4] "" IPC,IPC_INT,VCU
 SG_ BSSIP_LnchCtlModeStsAuth : 47|3@0+ (1,0) [0|7] "" IPC,IPC_INT,VCU
 SG_ FPLTLI_AuxPrkLmpLtCmd : 48|3@0+ (1,0) [0|4] "" CSM,CSM_AV,VCU
 SG_ FCAGpSet : 51|3@0+ (1,0) [0|5] "" TCP
 SG_ FPLTLI_PrkLmpLtCmd : 58|3@0+ (1,0) [0|4] "" CSM,CSM_AV,VCU
 SG_ FPLTLI_AuxPrkLmpRtCmd : 61|3@0+ (1,0) [0|4] "" CSM,CSM_AV,VCU

BO_ 1531 PDU_5046: 8 CGM
 SG_ LtAstStsIndRq : 1|3@0+ (1,0) [0|4] "" IPC,IPC_INT,VCU
 SG_ HybStatShtlModeOvrrd : 4|3@0+ (1,0) [0|7] "" IPC,IPC_INT,VCU
 SG_ FPLTLI_PrkLmpRtCmd : 7|3@0+ (1,0) [0|4] "" CSM,CSM_AV,VCU
 SG_ MemStorCmpltdIndReq : 8|3@0+ (1,0) [0|4] "" IPC,IPC_INT,VCU
 SG_ MemRclHldUntilCmpltIndReq : 11|3@0+ (1,0) [0|4] "" IPC,IPC_INT,VCU
 SG_ MemRclCmpltIndReq : 14|3@0+ (1,0) [0|4] "" IPC,IPC_INT,VCU
 SG_ NtVsnVidCntrstSts : 18|3@0+ (1,0) [0|7] "" IPC,IPC_INT,VCU
 SG_ NtVsnVidBrghtnsSts : 21|3@0+ (1,0) [0|7] "" IPC,IPC_INT,VCU
 SG_ RdHgtAtLocIndReq : 25|3@0+ (1,0) [0|5] "" IPC,IPC_INT,VCU
 SG_ RdHgtActvnIndReq : 28|3@0+ (1,0) [0|5] "" IPC,IPC_INT,VCU
 SG_ PARgn : 31|3@0+ (1,0) [0|1] "" IPC,IPC_INT,VCU
 SG_ SecAxlTransStatAchvd_Inv : 32|1@0+ (1,0) [0|1] "" AMP,VCU
 SG_ RdHgtWrn1IndReq : 35|3@0+ (1,0) [0|6] "" IPC,IPC_INT,VCU
 SG_ RdHgtMvmtIndReq : 38|3@0+ (1,0) [0|4] "" CSM,CSM_AV,IPC,IPC_INT,VCU
 SG_ TrnsSftMdSt : 42|3@0+ (1,0) [0|3] "" CSM,CSM_AV,IPC,IPC_INT,VCU
 SG_ TrlrMirVidEnblCstCurrSetVal : 45|3@0+ (1,0) [0|7] "" RadioLow,CSM,CSM_AV,VCU
 SG_ SecAxlTransStatAchvd : 47|2@0+ (1,0) [0|2] "" AMP,VCU
 SG_ WndPstnStsLR : 49|3@0+ (1,0) [0|7] "" AMP,RadioLow,TCP,VKM,VCU
 SG_ WndPstnStsLF : 52|3@0+ (1,0) [0|7] "" AMP,RadioLow,TCP,VKM,VCU
 SG_ VhSpdCntlSystmTyp : 55|3@0+ (1,0) [0|2] "" IPC,IPC_INT,VCU
 SG_ ACCRtSpdAdVsIndOn : 56|1@0+ (1,0) [0|1] "" TCP,IPC,IPC_INT,VCU
 SG_ WndPstnStsRR : 59|3@0+ (1,0) [0|7] "" AMP,RadioLow,TCP,VKM,VCU
 SG_ WndPstnStsRF : 62|3@0+ (1,0) [0|7] "" AMP,RadioLow,TCP,VKM,VCU

BO_ 1532 PDU_5047: 8 CGM
 SG_ WthrSnwModeDrvlineVisDispVal : 1|3@0+ (1,0) [0|7] "" RadioLow,CSM,CSM_AV,VCU
 SG_ WthrSnwModeBrkPedVisDispVal : 4|3@0+ (1,0) [0|7] "" RadioLow,CSM,CSM_AV,VCU
 SG_ WthrSnwModeActvAeroVisDispVal : 7|3@0+ (1,0) [0|7] "" RadioLow,CSM,CSM_AV,VCU
 SG_ WthrSnwModeRideHghtVisDispVal : 8|3@0+ (1,0) [0|7] "" RadioLow,CSM,CSM_AV,VCU
 SG_ WthrSnwModePwrtrnVisDispVal : 11|3@0+ (1,0) [0|7] "" RadioLow,CSM,CSM_AV,VCU
 SG_ WthrSnwModeESCVisDispVal : 14|3@0+ (1,0) [0|7] "" RadioLow,CSM,CSM_AV,VCU
 SG_ WthrSnwModeSpnsnVisDispVal : 18|3@0+ (1,0) [0|7] "" RadioLow,CSM,CSM_AV,VCU
 SG_ WthrSnwModeSndVisDispVal : 21|3@0+ (1,0) [0|7] "" RadioLow,CSM,CSM_AV,VCU
 SG_ CmdSndRwCtStbtVisInd : 25|2@0+ (1,0) [0|3] "" CSM,CSM_AV,IPC,IPC_INT,VCU
 SG_ CltTpTrvAchv : 26|1@0+ (1,0) [0|1] "" CSM,CSM_AV,VCU
 SG_ CltTpTrvAchv_Inv : 27|1@0+ (1,0) [0|1] "" CSM,CSM_AV,VCU
 SG_ AdvdFrtLgtSysIndReq : 29|2@0+ (1,0) [0|3] "" CSM,CSM_AV,IPC,IPC_INT,VCU
 SG_ ACCHdwySttng : 31|2@0+ (1,0) [0|2] "" TCP,CSM,CSM_AV,IPC,IPC_INT,VCU
 SG_ CmdThrdRwLtStbtVisInd : 33|2@0+ (1,0) [0|3] "" CSM,CSM_AV,IPC,IPC_INT,VCU
 SG_ CmdThrdRwCtStbtVisInd : 35|2@0+ (1,0) [0|3] "" CSM,CSM_AV,IPC,IPC_INT,VCU
 SG_ CmdSndRwRtStbtVisInd : 37|2@0+ (1,0) [0|3] "" CSM,CSM_AV,IPC,IPC_INT,VCU
 SG_ CmdSndRwLtStbtVisInd : 39|2@0+ (1,0) [0|3] "" CSM,CSM_AV,IPC,IPC_INT,VCU
 SG_ ElecShftrLckdHldBrkToOvrrdIndOn : 45|1@0+ (1,0) [0|1] "" IPC,IPC_INT,VCU
 SG_ CmdThrdRwRtStbtVisInd : 47|2@0+ (1,0) [0|3] "" CSM,CSM_AV,IPC,IPC_INT,VCU
 SG_ ElecAxlUnvIndReq : 49|2@0+ (1,0) [0|2] "" IPC,IPC_INT,VCU
 SG_ ElecAxlBstGageIndReq : 51|2@0+ (1,0) [0|2] "" IPC,IPC_INT,VCU
 SG_ DslEmnsOBDMrkt : 53|2@0+ (1,0) [0|2] "" IPC,IPC_INT,VCU
 SG_ LnCntrSpchPrmtReq : 57|2@0+ (1,0) [0|2] "" TCP,CSM,CSM_AV,VCU
 SG_ GlrFrHiBmSts : 59|2@0+ (1,0) [0|2] "" CSM,CSM_AV,VCU
 SG_ EngCmptHotWrnIndReq : 61|2@0+ (1,0) [0|3] "" IPC,IPC_INT,VCU
 SG_ ElecShftPrTwoGrsSelIndRq : 63|2@0+ (1,0) [0|3] "" IPC,IPC_INT,VCU

BO_ 1533 PDU_5048: 8 CGM
 SG_ ROSP_FrntPsRestOcpStatAuth : 1|2@0+ (1,0) [0|3] "" CSM,CSM_AV,VCU
 SG_ PdWrnIndRqst : 3|2@0+ (1,0) [0|3] "" CSM,CSM_AV,IPC,IPC_INT,VCU
 SG_ PPVehRadioMutReq : 5|2@0+ (1,0) [0|2] "" RadioLow,CSM,CSM_AV,VCU
 SG_ NtVsnFncSts : 7|2@0+ (1,0) [0|3] "" IPC,IPC_INT,VCU
 SG_ ACCSysSlctdMdDspIndOn : 8|1@0+ (1,0) [0|1] "" TCP,IPC,IPC_INT,VCU
 SG_ ACCShftToPrkBfrExIndOn : 9|1@0+ (1,0) [0|1] "" TCP,IPC,IPC_INT,VCU
 SG_ WhlSlpSt : 11|2@0+ (1,0) [0|3] "" CSM,CSM_AV,VCU
 SG_ VehMassEstSts : 13|2@0+ (1,0) [0|2] "" CSM,CSM_AV,VCU
 SG_ TrlrArtclnAngCalSts : 15|2@0+ (1,0) [0|3] "" CSM,CSM_AV,VCU
 SG_ AutoLnChgCstAvlFlg3 : 16|1@0+ (1,0) [0|1] "" CSM,CSM_AV,VCU
 SG_ AutoLnChgCstAvlFlg2 : 17|1@0+ (1,0) [0|1] "" CSM,CSM_AV,VCU
 SG_ AutoLnChgCstAvlFlg1 : 18|1@0+ (1,0) [0|1] "" CSM,CSM_AV,VCU
 SG_ AutoBmSlctAllwd : 19|1@0+ (1,0) [0|1] "" CSM,CSM_AV,VCU
 SG_ AirCndOffIO : 20|1@0+ (1,0) [0|1] "" TCP,CSM,CSM_AV,IPC,IPC_INT,VCU
 SG_ AdptCrsCntrlEngd : 21|1@0+ (1,0) [0|1] "" TCP,CSM,CSM_AV,IPC,IPC_INT,VCU
 SG_ ACCompCmnd : 22|1@0+ (1,0) [0|1] "" TCP,CSM,CSM_AV,VCU
 SG_ ACCTmpUnvIndOn : 23|1@0+ (1,0) [0|1] "" TCP,CSM,CSM_AV,IPC,IPC_INT,VCU
 SG_ AutoTrnspHdActvnCstAvlFlg3 : 24|1@0+ (1,0) [0|1] "" CSM,CSM_AV,VCU
 SG_ AutoTrnspHdActvnCstAvlFlg2 : 25|1@0+ (1,0) [0|1] "" CSM,CSM_AV,VCU
 SG_ AutoTrnspHdActvnCstAvlFlg1 : 26|1@0+ (1,0) [0|1] "" CSM,CSM_AV,VCU
 SG_ AutoLnChgCstSetAval : 27|1@0+ (1,0) [0|1] "" CSM,CSM_AV,VCU
 SG_ AutoLnChgCstAvlFlg7 : 28|1@0+ (1,0) [0|1] "" CSM,CSM_AV,VCU
 SG_ AutoLnChgCstAvlFlg6 : 29|1@0+ (1,0) [0|1] "" CSM,CSM_AV,VCU
 SG_ AutoLnChgCstAvlFlg5 : 30|1@0+ (1,0) [0|1] "" CSM,CSM_AV,VCU
 SG_ AutoLnChgCstAvlFlg4 : 31|1@0+ (1,0) [0|1] "" CSM,CSM_AV,VCU
 SG_ DCCnvStblznErrIndOn : 32|1@0+ (1,0) [0|1] "" IPC,IPC_INT,VCU
 SG_ CustmStbCtlRdctReqIndOn : 33|1@0+ (1,0) [0|1] "" IPC,IPC_INT,VCU
 SG_ AxlLcksServIO : 34|1@0+ (1,0) [0|1] "" IPC,IPC_INT,VCU
 SG_ AutoTrnspHdActvnCstSetAval : 35|1@0+ (1,0) [0|1] "" CSM,CSM_AV,VCU
 SG_ AutoTrnspHdActvnCstAvlFlg7 : 36|1@0+ (1,0) [0|1] "" CSM,CSM_AV,VCU
 SG_ AutoTrnspHdActvnCstAvlFlg6 : 37|1@0+ (1,0) [0|1] "" CSM,CSM_AV,VCU
 SG_ AutoTrnspHdActvnCstAvlFlg5 : 38|1@0+ (1,0) [0|1] "" CSM,CSM_AV,VCU
 SG_ AutoTrnspHdActvnCstAvlFlg4 : 39|1@0+ (1,0) [0|1] "" CSM,CSM_AV,VCU
 SG_ DM8Denied : 40|1@0+ (1,0) [0|1] "" IPC,IPC_INT,VCU
 SG_ DM7Denied : 41|1@0+ (1,0) [0|1] "" IPC,IPC_INT,VCU
 SG_ DM6Denied : 42|1@0+ (1,0) [0|1] "" IPC,IPC_INT,VCU
 SG_ DM5Denied : 43|1@0+ (1,0) [0|1] "" IPC,IPC_INT,VCU
 SG_ DM4Denied : 44|1@0+ (1,0) [0|1] "" IPC,IPC_INT,VCU
 SG_ DM3Denied : 45|1@0+ (1,0) [0|1] "" IPC,IPC_INT,VCU
 SG_ DM2Denied : 46|1@0+ (1,0) [0|1] "" IPC,IPC_INT,VCU
 SG_ DM1Denied : 47|1@0+ (1,0) [0|1] "" IPC,IPC_INT,VCU
 SG_ ElecShfPriTransCtlrMalfIndOn : 48|1@0+ (1,0) [0|1] "" IPC,IPC_INT,VCU
 SG_ ElecShfPriShfToDrvTryAgnIndOn : 49|1@0+ (1,0) [0|1] "" IPC,IPC_INT,VCU
 SG_ ElecShfPriRdcSpdForReqdShfIndOn : 50|1@0+ (1,0) [0|1] "" IPC,IPC_INT,VCU
 SG_ ElecShfLckdBcklPsngrStBltIndOn : 51|1@0+ (1,0) [0|1] "" IPC,IPC_INT,VCU
 SG_ ElecShfLckdBcklDrvrStBltIndOn : 52|1@0+ (1,0) [0|1] "" IPC,IPC_INT,VCU
 SG_ DrSlctdSpdLmtrEnbld : 54|1@0+ (1,0) [0|1] "" TCP,CSM,CSM_AV,IPC,IPC_INT,VCU
 SG_ DrSlctdSpdLmtrActv : 55|1@0+ (1,0) [0|1] "" TCP,CSM,CSM_AV,IPC,IPC_INT,VCU
 SG_ ElecShftPrDrDoorStIndIO : 56|1@0+ (1,0) [0|1] "" IPC,IPC_INT,VCU
 SG_ ElecShftPrAtPrkIO : 57|1@0+ (1,0) [0|1] "" IPC,IPC_INT,VCU
 SG_ ElecShfUnlckdBrkToShfIndOn : 59|1@0+ (1,0) [0|1] "" IPC,IPC_INT,VCU
 SG_ ElecShfPriTrnVehOffForPrkIndOn : 63|1@0+ (1,0) [0|1] "" IPC,IPC_INT,VCU

BO_ 1276 PDU_5049: 8 CGM
 SG_ ElecShftPrTrnMlfIO : 0|1@0+ (1,0) [0|1] "" IPC,IPC_INT,VCU
 SG_ ElecShftPrRngInvRqIO : 1|1@0+ (1,0) [0|1] "" IPC,IPC_INT,VCU
 SG_ ElecShftPrPrkInvRqIO : 2|1@0+ (1,0) [0|1] "" IPC,IPC_INT,VCU
 SG_ ElecShftPrLtdPrfMdIO : 3|1@0+ (1,0) [0|1] "" IPC,IPC_INT,VCU
 SG_ ElecShftPrHldShftLevEngRngIO : 4|1@0+ (1,0) [0|1] "" IPC,IPC_INT,VCU
 SG_ ElecShftPrDrPrkIntShftAtmpIO : 5|1@0+ (1,0) [0|1] "" IPC,IPC_INT,VCU
 SG_ ElecShftPrDrIntShftAtmpIO : 6|1@0+ (1,0) [0|1] "" IPC,IPC_INT,VCU
 SG_ ElecShftPrDrExitIO : 7|1@0+ (1,0) [0|1] "" IPC,IPC_INT,VCU
 SG_ FrwdCllsnSysRdIndOn : 8|1@0+ (1,0) [0|1] "" TCP,CSM,CSM_AV,IPC,IPC_INT,VCU
 SG_ FrwdCllsnSysOffIndOn : 9|1@0+ (1,0) [0|1] "" TCP,CSM,CSM_AV,IPC,IPC_INT,VCU
 SG_ FrwdCllsnAlrtOffIndOn : 10|1@0+ (1,0) [0|1] "" TCP,CSM,CSM_AV,IPC,IPC_INT,VCU
 SG_ FrtPedtrnBrkgWrnIndOn : 11|1@0+ (1,0) [0|1] "" IPC,IPC_INT,VCU
 SG_ FrntAxlLckIO : 12|1@0+ (1,0) [0|1] "" CSM,CSM_AV,IPC,IPC_INT,VCU
 SG_ FrFgLmpIO : 13|1@0+ (1,0) [0|1] "" TCP,VKM,CSM,CSM_AV,IPC,IPC_INT,VCU
 SG_ EngNEmsnsRltMlfnAct : 14|1@0+ (1,0) [0|1] "" CSM,CSM_AV,IPC,IPC_INT,VCU
 SG_ EngCstFlCtOffAct : 15|1@0+ (1,0) [0|1] "" CSM,CSM_AV,IPC,IPC_INT,VCU
 SG_ LnCntrArrwBlck4Act : 16|1@0+ (1,0) [0|1] "" TCP
 SG_ LnCntrArrwBlck3Act : 17|1@0+ (1,0) [0|1] "" TCP
 SG_ LnCntrArrwBlck2Act : 18|1@0+ (1,0) [0|1] "" TCP
 SG_ LnCntrArrwBlck1Act : 19|1@0+ (1,0) [0|1] "" TCP
 SG_ HzrdReqActv : 20|1@0+ (1,0) [0|1] "" TCP
 SG_ GenFld : 21|1@0+ (1,0) [0|1] "" TCP,CSM,CSM_AV,IPC,IPC_INT,VCU
 SG_ FrwdClsnSysIndOn : 22|1@0+ (1,0) [0|1] "" CSM,CSM_AV,IPC,IPC_INT,VCU
 SG_ FrwdCllsnSysUnIndOn : 23|1@0+ (1,0) [0|1] "" TCP,CSM,CSM_AV,IPC,IPC_INT,VCU
 SG_ LvlgSysEntEgrsMdCstAvlFlg3 : 24|1@0+ (1,0) [0|1] "" RadioLow,CSM,CSM_AV,VCU
 SG_ LvlgSysEntEgrsMdCstAvlFlg2 : 25|1@0+ (1,0) [0|1] "" RadioLow,CSM,CSM_AV,VCU
 SG_ LvlgSysEntEgrsMdCstAvlFlg1 : 26|1@0+ (1,0) [0|1] "" RadioLow,CSM,CSM_AV,VCU
 SG_ LvlgSysAlgnMdCstAvlFlg7 : 27|1@0+ (1,0) [0|1] "" RadioLow,CSM,CSM_AV,VCU
 SG_ LvlgSysAlgnMdCstAvlFlg6 : 28|1@0+ (1,0) [0|1] "" RadioLow,CSM,CSM_AV,VCU
 SG_ LnKpAsstUnAvIndOn : 29|1@0+ (1,0) [0|1] "" TCP,CSM,CSM_AV,IPC,IPC_INT,VCU
 SG_ LnDprtrWrngUnAvIndOn : 30|1@0+ (1,0) [0|1] "" TCP,CSM,CSM_AV,IPC,IPC_INT,VCU
 SG_ LnCntrArrwBlck5Act : 31|1@0+ (1,0) [0|1] "" TCP
 SG_ LvlgSysServMdCstAvlFlg4 : 32|1@0+ (1,0) [0|1] "" RadioLow,CSM,CSM_AV,VCU
 SG_ LvlgSysServMdCstAvlFlg3 : 33|1@0+ (1,0) [0|1] "" RadioLow,CSM,CSM_AV,VCU
 SG_ LvlgSysServMdCstAvlFlg2 : 34|1@0+ (1,0) [0|1] "" RadioLow,CSM,CSM_AV,VCU
 SG_ LvlgSysServMdCstAvlFlg1 : 35|1@0+ (1,0) [0|1] "" RadioLow,CSM,CSM_AV,VCU
 SG_ LvlgSysEntEgrsMdCstAvlFlg7 : 36|1@0+ (1,0) [0|1] "" RadioLow,CSM,CSM_AV,VCU
 SG_ LvlgSysEntEgrsMdCstAvlFlg6 : 37|1@0+ (1,0) [0|1] "" RadioLow,CSM,CSM_AV,VCU
 SG_ LvlgSysEntEgrsMdCstAvlFlg5 : 38|1@0+ (1,0) [0|1] "" RadioLow,CSM,CSM_AV,VCU
 SG_ LvlgSysEntEgrsMdCstAvlFlg4 : 39|1@0+ (1,0) [0|1] "" RadioLow,CSM,CSM_AV,VCU
 SG_ PrkAsstActIndCmnd : 40|1@0+ (1,0) [0|1] "" CSM,CSM_AV,VCU
 SG_ NoKeyDtdElecShfDndIndOn : 41|1@0+ (1,0) [0|1] "" IPC,IPC_INT,VCU
 SG_ MemStorTmdOutIndOn : 42|1@0+ (1,0) [0|1] "" IPC,IPC_INT,VCU
 SG_ MemStorPrssSetFrstIndOn : 43|1@0+ (1,0) [0|1] "" IPC,IPC_INT,VCU
 SG_ MemSeeAutoRclSetsIndOn : 44|1@0+ (1,0) [0|1] "" IPC,IPC_INT,VCU
 SG_ LvlgSysServMdCstAvlFlg7 : 45|1@0+ (1,0) [0|1] "" RadioLow,CSM,CSM_AV,VCU
 SG_ LvlgSysServMdCstAvlFlg6 : 46|1@0+ (1,0) [0|1] "" RadioLow,CSM,CSM_AV,VCU
 SG_ LvlgSysServMdCstAvlFlg5 : 47|1@0+ (1,0) [0|1] "" RadioLow,CSM,CSM_AV,VCU
 SG_ SftTpFlrIO : 48|1@0+ (1,0) [0|1] "" IPC,IPC_INT,VCU
 SG_ RrVirtBmpAutoBrkRelIndOn : 49|1@0+ (1,0) [0|1] "" IPC,IPC_INT,VCU
 SG_ RrFgLmpIO : 51|1@0+ (1,0) [0|1] "" TCP,VKM,CSM,CSM_AV,IPC,IPC_INT,VCU
 SG_ RrAxlLckIO : 52|1@0+ (1,0) [0|1] "" CSM,CSM_AV,IPC,IPC_INT,VCU
 SG_ RmtRflshDispActvnReq : 53|1@0+ (1,0) [0|1] "" RadioLow,CSM,CSM_AV,VCU
 SG_ RmtRflshCmpgnAval : 54|1@0+ (1,0) [0|1] "" RadioLow,CSM,CSM_AV,VCU
 SG_ ROSP_FrtPsRestOcpFltIndAuth : 55|1@0+ (1,0) [0|1] "" RadioLow,CSM,CSM_AV,VCU
 SG_ StNtLtchdIO : 56|1@0+ (1,0) [0|1] "" IPC,IPC_INT,VCU
 SG_ SrvPedtrnProtSysIO : 57|1@0+ (1,0) [0|1] "" TCP,CSM,CSM_AV,IPC,IPC_INT,VCU
 SG_ SrvFrwdCllsnSysIndOn : 58|1@0+ (1,0) [0|1] "" TCP,CSM,CSM_AV,IPC,IPC_INT,VCU
 SG_ SrvDvrAsstSystVslMsgRqstOn : 59|1@0+ (1,0) [0|1] "" TCP,IPC,IPC_INT,VCU
 SG_ SftTpVltLwIO : 60|1@0+ (1,0) [0|1] "" IPC,IPC_INT,VCU
 SG_ SftTpVehOvSpdIO : 61|1@0+ (1,0) [0|1] "" CSM,CSM_AV,IPC,IPC_INT,VCU
 SG_ SftTpTmpLwIO : 62|1@0+ (1,0) [0|1] "" CSM,CSM_AV,IPC,IPC_INT,VCU

BO_ 1534 PDU_5050: 6 CGM
 SG_ TrlrFgLtFld : 0|1@0+ (1,0) [0|1] "" RadioLow,CSM,CSM_AV,IPC,IPC_INT,VCU
 SG_ TrlrDisconndIndOn : 1|1@0+ (1,0) [0|1] "" CSM,CSM_AV,VCU
 SG_ TrlrBrkLtFld : 2|1@0+ (1,0) [0|1] "" RadioLow,CSM,CSM_AV,IPC,IPC_INT,VCU
 SG_ TrlLfTrInLtFld : 3|1@0+ (1,0) [0|1] "" RadioLow,CSM,CSM_AV,IPC,IPC_INT,VCU
 SG_ TnDrvRIMOFFUnvIndOn : 4|1@0+ (1,0) [0|1] "" TCP,IPC,IPC_INT,VCU
 SG_ TnDrvGapAdjUnvIndOn : 5|1@0+ (1,0) [0|1] "" IPC,IPC_INT,VCU
 SG_ TeenDrvrLnDprtrWrnOffUnvIndOn : 6|1@0+ (1,0) [0|1] "" IPC,IPC_INT,VCU
 SG_ StlthModeActv : 7|1@0+ (1,0) [0|1] "" IPC,IPC_INT,VCU
 SG_ TrnsEmsRltMlfAtv : 8|1@0+ (1,0) [0|1] "" CSM,CSM_AV,VCU
 SG_ TrnLmpRrRtOtgIndOn : 9|1@0+ (1,0) [0|1] "" TCP,VKM,CSM,CSM_AV,IPC,IPC_INT,VCU
 SG_ TrnLmpRrLtOtgIndOn : 10|1@0+ (1,0) [0|1] "" TCP,VKM,CSM,CSM_AV,IPC,IPC_INT,VCU
 SG_ TrnLmpFrtRtOtgIndOn : 11|1@0+ (1,0) [0|1] "" RadioLow,TCP,VKM,CSM,CSM_AV,IPC,IPC_INT,VCU
 SG_ TrnLmpFrtLtOtgIndOn : 12|1@0+ (1,0) [0|1] "" RadioLow,TCP,VKM,CSM,CSM_AV,IPC,IPC_INT,VCU
 SG_ TrlrTlLtFld : 13|1@0+ (1,0) [0|1] "" RadioLow,CSM,CSM_AV,IPC,IPC_INT,VCU
 SG_ TrlrRvrsLmpOtgIndOn : 14|1@0+ (1,0) [0|1] "" RadioLow,CSM,CSM_AV,IPC,IPC_INT,VCU
 SG_ TrlrRtTrInLtFld : 15|1@0+ (1,0) [0|1] "" RadioLow,CSM,CSM_AV,IPC,IPC_INT,VCU
 SG_ SnrfActlPstn : 16|4@0+ (1,0) [0|13] "" VCU
 SG_ TrnsThrmlMngmntSt : 18|2@0+ (1,0) [0|2] "" TCP,CSM,CSM_AV,IPC,IPC_INT,VCU
 SG_ VltSwAtvIO : 19|1@0+ (1,0) [0|1] "" TCP,CSM,CSM_AV,IPC,IPC_INT,VCU
 SG_ UIDInStatusSD : 20|1@0+ (1,0) [0|1] "" RadioLow,TCP,CSM,CSM_AV,VCU
 SG_ TrnstStrgLogisticsMdActivation : 21|1@0+ (1,0) [0|1] "" FPI,RSI,RadioLow,CSM,CSM_AV,VCU
 SG_ TrnsOilChngIO : 22|1@0+ (1,0) [0|1] "" TCP,VKM,IPC,IPC_INT,VCU
 SG_ TrnsNEmsRltMlfActv : 23|1@0+ (1,0) [0|1] "" TCP,CSM,CSM_AV,IPC,IPC_INT,VCU
 SG_ ADASMsgDispLocNonActvInd : 25|3@0+ (1,0) [0|3] "" IPC,IPC_INT,VCU
 SG_ ADASMsgDispLocLtdPerfStatInd : 28|3@0+ (1,0) [0|3] "" IPC,IPC_INT,VCU
 SG_ ArflBsdOnOccpRrPsCstCurrSetVal : 32|3@0+ (1,0) [0|2] "" VCU
 SG_ ArflBsdOnOccpFrtPsCstCurrSetVal : 35|3@0+ (1,0) [0|2] "" VCU
 SG_ ADASTrmLvlInd : 38|3@0+ (1,0) [0|2] "" IPC,IPC_INT,VCU
 SG_ LnCntrWrn2IndReq : 45|6@0+ (1,0) [0|25] "" VCU

BO_ 1824 PDU_5051: 8 CGM
 SG_ TmSyncMsg : 7|40@0+ (100,0) [0|1.09951e+014] "ms" AMP,FPI,HVAC_FP_F,HVAC_FP_R,ICS_Info,PDR,MFC,PLCM,RSI,RadioLow,TCP,VKM,CSM,CSM_AV,IPC,IPC_INT,VCU,WCM,WCM2,WCM3,WCM4
 SG_ WDP_WhlDistPerRevFrtAuth : 47|10@0+ (3,800) [800|3869] "mm" PDR,TCP,CSM,CSM_AV,VCU
 SG_ WDP_WhlDistPerRevRrAuth : 53|10@0+ (3,800) [800|3869] "mm" PDR,TCP,CSM,CSM_AV,VCU
 SG_ SprTireSt : 57|2@0+ (1,0) [0|2] "" CSM,CSM_AV,VCU
 SG_ BrkFldLvlSt : 59|2@0+ (1,0) [0|2] "" TCP,CSM,CSM_AV,VCU

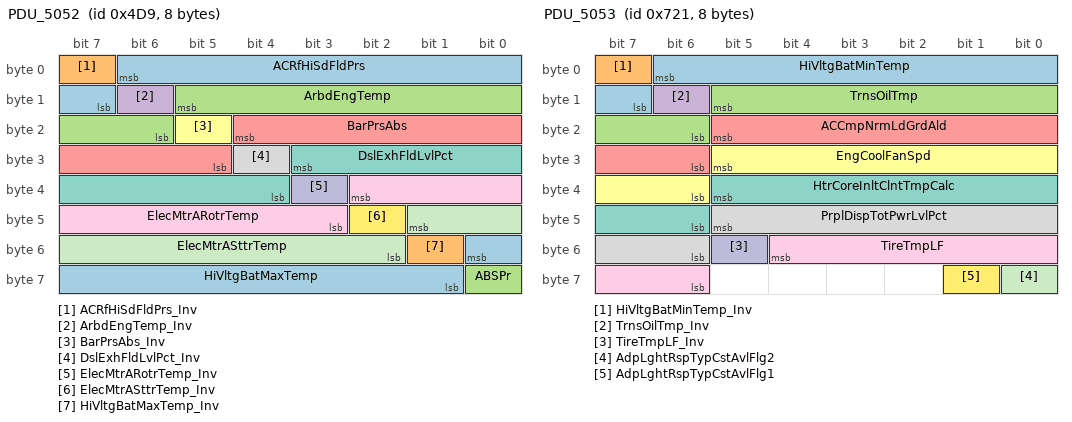
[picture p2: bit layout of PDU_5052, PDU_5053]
BO_ 1241 PDU_5052: 8 CGM
 SG_ ACRfHiSdFldPrs : 6|8@0+ (14,0) [0|3570] "kPaG" TCP,CSM,CSM_AV,VCU
 SG_ ACRfHiSdFldPrs_Inv : 7|1@0+ (1,0) [0|1] "" TCP,CSM,CSM_AV,VCU
 SG_ ArbdEngTemp : 13|8@0+ (1,-40) [-40|215] "deg C" PDR,CSM,CSM_AV,IPC,IPC_INT,VCU
 SG_ ArbdEngTemp_Inv : 14|1@0+ (1,0) [0|1] "" PDR,CSM,CSM_AV,IPC,IPC_INT,VCU
 SG_ BarPrsAbs : 20|8@0+ (0.5,0) [0|127.5] "kPa" CSM,CSM_AV,VCU
 SG_ BarPrsAbs_Inv : 21|1@0+ (1,0) [0|1] "" CSM,CSM_AV,VCU
 SG_ DslExhFldLvlPct : 27|8@0+ (0.392157,0) [0|100] "%" CSM,CSM_AV,IPC,IPC_INT,VCU
 SG_ DslExhFldLvlPct_Inv : 28|1@0+ (1,0) [0|1] "" CSM,CSM_AV,IPC,IPC_INT,VCU
 SG_ ElecMtrARotrTemp : 34|8@0+ (1,-40) [-40|215] "deg C" PDR,CSM,CSM_AV,VCU
 SG_ ElecMtrARotrTemp_Inv : 35|1@0+ (1,0) [0|1] "" PDR,CSM,CSM_AV,VCU
 SG_ ElecMtrASttrTemp : 41|8@0+ (1,-40) [-40|215] "deg C" PDR,CSM,CSM_AV,VCU
 SG_ ElecMtrASttrTemp_Inv : 42|1@0+ (1,0) [0|1] "" PDR,CSM,CSM_AV,VCU
 SG_ HiVltgBatMaxTemp : 48|8@0+ (0.5,-40) [-40|87.5] "Deg C" PDR,VCU
 SG_ HiVltgBatMaxTemp_Inv : 49|1@0+ (1,0) [0|1] "" PDR,VCU
 SG_ ABSPr : 56|1@0+ (1,0) [0|1] "" TCP

BO_ 1825 PDU_5053: 8 CGM
 SG_ HiVltgBatMinTemp : 6|8@0+ (0.5,-40) [-40|87.5] "Deg C" PDR,TCP,VCU
 SG_ HiVltgBatMinTemp_Inv : 7|1@0+ (1,0) [0|1] "" PDR,VCU
 SG_ TrnsOilTmp : 13|8@0+ (1,-40) [-40|215] "deg C" PDR,TCP,CSM,CSM_AV,IPC,IPC_INT,VCU
 SG_ TrnsOilTmp_Inv : 14|1@0+ (1,0) [0|1] "" PDR,CSM,CSM_AV,IPC,IPC_INT,VCU
 SG_ ACCmpNrmLdGrdAld : 21|8@0+ (0.1,0) [0|25.5] "dm3/m/s" CSM,CSM_AV,VCU
 SG_ EngCoolFanSpd : 29|8@0+ (0.392157,0) [0|100] "%" CSM,CSM_AV,VCU
 SG_ HtrCoreInltClntTmpCalc : 37|8@0+ (1,-40) [-40|215] "deg C" TCP,CSM,CSM_AV,VCU
 SG_ PrplDispTotPwrLvlPct : 45|8@0- (1,0) [-128|127] "%" PDR,CSM,CSM_AV,IPC,IPC_INT,VCU
 SG_ TireTmpLF : 52|7@0+ (1,-20) [-20|107] "deg C" PDR,CSM,CSM_AV,VCU
 SG_ TireTmpLF_Inv : 53|1@0+ (1,0) [0|1] "" PDR,CSM,CSM_AV,VCU
 SG_ AdpLghtRspTypCstAvlFlg2 : 56|1@0+ (1,0) [0|1] "" RadioLow,CSM,CSM_AV,VCU
 SG_ AdpLghtRspTypCstAvlFlg1 : 57|1@0+ (1,0) [0|1] "" RadioLow,CSM,CSM_AV,VCU

BO_ 1240 PDU_5054: 8 CGM
 SG_ TireTmpLR : 6|7@0+ (1,-20) [-20|107] "deg C" PDR,CSM,CSM_AV,VCU
 SG_ TireTmpLR_Inv : 7|1@0+ (1,0) [0|1] "" PDR,CSM,CSM_AV,VCU
 SG_ TireTmpRF : 14|7@0+ (1,-20) [-20|107] "deg C" PDR,CSM,CSM_AV,VCU
 SG_ TireTmpRF_Inv : 15|1@0+ (1,0) [0|1] "" PDR,CSM,CSM_AV,VCU
 SG_ TireTmpRR : 22|7@0+ (1,-20) [-20|107] "deg C" PDR,CSM,CSM_AV,VCU
 SG_ TireTmpRR_Inv : 23|1@0+ (1,0) [0|1] "" PDR,CSM,CSM_AV,VCU
 SG_ FrtRdHgtGPSCstAvlbltyFlg7 : 32|1@0+ (1,0) [0|1] "" RadioLow,CSM,CSM_AV,VCU
 SG_ FrtRdHgtGPSCstAvlbltyFlg6 : 33|1@0+ (1,0) [0|1] "" RadioLow,CSM,CSM_AV,VCU
 SG_ FrtRdHgtGPSCstAvlbltyFlg5 : 34|1@0+ (1,0) [0|1] "" RadioLow,CSM,CSM_AV,VCU
 SG_ FrtRdHgtGPSCstAvlbltyFlg4 : 35|1@0+ (1,0) [0|1] "" RadioLow,CSM,CSM_AV,VCU
 SG_ FrtRdHgtGPSCstAvlbltyFlg3 : 36|1@0+ (1,0) [0|1] "" RadioLow,CSM,CSM_AV,VCU
 SG_ FrtRdHgtGPSCstAvlbltyFlg2 : 37|1@0+ (1,0) [0|1] "" RadioLow,CSM,CSM_AV,VCU
 SG_ FrtRdHgtGPSCstAvlbltyFlg1 : 38|1@0+ (1,0) [0|1] "" RadioLow,CSM,CSM_AV,VCU
 SG_ AdpLghtRspTypCstAvlFlg3 : 39|1@0+ (1,0) [0|1] "" RadioLow,CSM,CSM_AV,VCU
 SG_ LvlgSysAlgnMdCstAvlFlg1 : 40|1@0+ (1,0) [0|1] "" RadioLow,CSM,CSM_AV,VCU
 SG_ LtRtHnTrCstAvlFlg7 : 41|1@0+ (1,0) [0|1] "" RadioLow,CSM,CSM_AV,VCU
 SG_ LtRtHnTrCstAvlFlg6 : 42|1@0+ (1,0) [0|1] "" RadioLow,CSM,CSM_AV,VCU
 SG_ LtRtHnTrCstAvlFlg5 : 43|1@0+ (1,0) [0|1] "" RadioLow,CSM,CSM_AV,VCU
 SG_ LtRtHnTrCstAvlFlg4 : 44|1@0+ (1,0) [0|1] "" RadioLow,CSM,CSM_AV,VCU
 SG_ LtRtHnTrCstAvlFlg3 : 45|1@0+ (1,0) [0|1] "" RadioLow,CSM,CSM_AV,VCU
 SG_ LtRtHnTrCstAvlFlg2 : 46|1@0+ (1,0) [0|1] "" RadioLow,CSM,CSM_AV,VCU
 SG_ LtRtHnTrCstAvlFlg1 : 47|1@0+ (1,0) [0|1] "" RadioLow,CSM,CSM_AV,VCU
 SG_ PrkAsstONOFFCstAvlFlg3 : 48|1@0+ (1,0) [0|1] "" RadioLow,CSM,CSM_AV,VCU
 SG_ PrkAsstONOFFCstAvlFlg2 : 49|1@0+ (1,0) [0|1] "" RadioLow,CSM,CSM_AV,VCU
 SG_ PrkAsstONOFFCstAvlFlg1 : 50|1@0+ (1,0) [0|1] "" RadioLow,CSM,CSM_AV,VCU
 SG_ PTHiElecLdReqd : 51|1@0+ (1,0) [0|1] "" CSM,CSM_AV,VCU
 SG_ LvlgSysAlgnMdCstAvlFlg5 : 52|1@0+ (1,0) [0|1] "" RadioLow,CSM,CSM_AV,VCU
 SG_ LvlgSysAlgnMdCstAvlFlg4 : 53|1@0+ (1,0) [0|1] "" RadioLow,CSM,CSM_AV,VCU
 SG_ LvlgSysAlgnMdCstAvlFlg3 : 54|1@0+ (1,0) [0|1] "" RadioLow,CSM,CSM_AV,VCU
 SG_ LvlgSysAlgnMdCstAvlFlg2 : 55|1@0+ (1,0) [0|1] "" RadioLow,CSM,CSM_AV,VCU
 SG_ PrkAsstTrHtchPsntCstAvlFlg4 : 56|1@0+ (1,0) [0|1] "" RadioLow,CSM,CSM_AV,VCU
 SG_ PrkAsstTrHtchPsntCstAvlFlg3 : 57|1@0+ (1,0) [0|1] "" RadioLow,CSM,CSM_AV,VCU
 SG_ PrkAsstTrHtchPsntCstAvlFlg2 : 58|1@0+ (1,0) [0|1] "" RadioLow,CSM,CSM_AV,VCU
 SG_ PrkAsstTrHtchPsntCstAvlFlg1 : 59|1@0+ (1,0) [0|1] "" RadioLow,CSM,CSM_AV,VCU
 SG_ PrkAsstONOFFCstAvlFlg7 : 60|1@0+ (1,0) [0|1] "" RadioLow,CSM,CSM_AV,VCU
 SG_ PrkAsstONOFFCstAvlFlg6 : 61|1@0+ (1,0) [0|1] "" RadioLow,CSM,CSM_AV,VCU
 SG_ PrkAsstONOFFCstAvlFlg5 : 62|1@0+ (1,0) [0|1] "" RadioLow,CSM,CSM_AV,VCU
 SG_ PrkAsstONOFFCstAvlFlg4 : 63|1@0+ (1,0) [0|1] "" RadioLow,CSM,CSM_AV,VCU

BO_ 1826 PDU_5055: 8 CGM
 SG_ RnngBrdAutoDplyCstAvlFlg5 : 0|1@0+ (1,0) [0|1] "" RadioLow,CSM,CSM_AV,VCU
 SG_ RnngBrdAutoDplyCstAvlFlg4 : 1|1@0+ (1,0) [0|1] "" RadioLow,CSM,CSM_AV,VCU
 SG_ RnngBrdAutoDplyCstAvlFlg3 : 2|1@0+ (1,0) [0|1] "" RadioLow,CSM,CSM_AV,VCU
 SG_ RnngBrdAutoDplyCstAvlFlg2 : 3|1@0+ (1,0) [0|1] "" RadioLow,CSM,CSM_AV,VCU
 SG_ RnngBrdAutoDplyCstAvlFlg1 : 4|1@0+ (1,0) [0|1] "" RadioLow,CSM,CSM_AV,VCU
 SG_ PrkAsstTrHtchPsntCstAvlFlg7 : 5|1@0+ (1,0) [0|1] "" RadioLow,CSM,CSM_AV,VCU
 SG_ PrkAsstTrHtchPsntCstAvlFlg6 : 6|1@0+ (1,0) [0|1] "" RadioLow,CSM,CSM_AV,VCU
 SG_ PrkAsstTrHtchPsntCstAvlFlg5 : 7|1@0+ (1,0) [0|1] "" RadioLow,CSM,CSM_AV,VCU
 SG_ RnngBrdManDplyCstAvlFlg6 : 8|1@0+ (1,0) [0|1] "" RadioLow,CSM,CSM_AV,VCU
 SG_ RnngBrdManDplyCstAvlFlg5 : 9|1@0+ (1,0) [0|1] "" RadioLow,CSM,CSM_AV,VCU
 SG_ RnngBrdManDplyCstAvlFlg4 : 10|1@0+ (1,0) [0|1] "" RadioLow,CSM,CSM_AV,VCU
 SG_ RnngBrdManDplyCstAvlFlg3 : 11|1@0+ (1,0) [0|1] "" RadioLow,CSM,CSM_AV,VCU
 SG_ RnngBrdManDplyCstAvlFlg2 : 12|1@0+ (1,0) [0|1] "" RadioLow,CSM,CSM_AV,VCU
 SG_ RnngBrdManDplyCstAvlFlg1 : 13|1@0+ (1,0) [0|1] "" RadioLow,CSM,CSM_AV,VCU
 SG_ RnngBrdAutoDplyCstAvlFlg7 : 14|1@0+ (1,0) [0|1] "" RadioLow,CSM,CSM_AV,VCU
 SG_ RnngBrdAutoDplyCstAvlFlg6 : 15|1@0+ (1,0) [0|1] "" RadioLow,CSM,CSM_AV,VCU
 SG_ RrVwPrkAstSymCsAvlFlg7 : 16|1@0+ (1,0) [0|1] "" RadioLow,CSM,CSM_AV,VCU
 SG_ RrVwPrkAstSymCsAvlFlg6 : 17|1@0+ (1,0) [0|1] "" RadioLow,CSM,CSM_AV,VCU
 SG_ RrVwPrkAstSymCsAvlFlg5 : 18|1@0+ (1,0) [0|1] "" RadioLow,CSM,CSM_AV,VCU
 SG_ RrVwPrkAstSymCsAvlFlg4 : 19|1@0+ (1,0) [0|1] "" RadioLow,CSM,CSM_AV,VCU
 SG_ RrVwPrkAstSymCsAvlFlg3 : 20|1@0+ (1,0) [0|1] "" RadioLow,CSM,CSM_AV,VCU
 SG_ RrVwPrkAstSymCsAvlFlg2 : 21|1@0+ (1,0) [0|1] "" RadioLow,CSM,CSM_AV,VCU
 SG_ RrVwPrkAstSymCsAvlFlg1 : 22|1@0+ (1,0) [0|1] "" RadioLow,CSM,CSM_AV,VCU
 SG_ RnngBrdManDplyCstAvlFlg7 : 23|1@0+ (1,0) [0|1] "" RadioLow,CSM,CSM_AV,VCU
 SG_ StBltTghtngCstAvlFlg1 : 24|1@0+ (1,0) [0|1] "" RadioLow,CSM,CSM_AV,VCU
 SG_ SrrndVwLghtCsAvlFlg7 : 25|1@0+ (1,0) [0|1] "" RadioLow,CSM,CSM_AV,VCU
 SG_ SrrndVwLghtCsAvlFlg6 : 26|1@0+ (1,0) [0|1] "" RadioLow,CSM,CSM_AV,VCU
 SG_ SrrndVwLghtCsAvlFlg5 : 27|1@0+ (1,0) [0|1] "" RadioLow,CSM,CSM_AV,VCU
 SG_ SrrndVwLghtCsAvlFlg4 : 28|1@0+ (1,0) [0|1] "" RadioLow,CSM,CSM_AV,VCU
 SG_ SrrndVwLghtCsAvlFlg3 : 29|1@0+ (1,0) [0|1] "" RadioLow,CSM,CSM_AV,VCU
 SG_ SrrndVwLghtCsAvlFlg2 : 30|1@0+ (1,0) [0|1] "" RadioLow,CSM,CSM_AV,VCU
 SG_ SrrndVwLghtCsAvlFlg1 : 31|1@0+ (1,0) [0|1] "" RadioLow,CSM,CSM_AV,VCU
 SG_ TnDrvStBltShfIntlkCstAvlFlg2 : 32|1@0+ (1,0) [0|1] "" RadioLow,CSM,CSM_AV,VCU
 SG_ TnDrvStBltShfIntlkCstAvlFlg1 : 33|1@0+ (1,0) [0|1] "" RadioLow,CSM,CSM_AV,VCU
 SG_ StBltTghtngCstAvlFlg7 : 34|1@0+ (1,0) [0|1] "" RadioLow,CSM,CSM_AV,VCU
 SG_ StBltTghtngCstAvlFlg6 : 35|1@0+ (1,0) [0|1] "" RadioLow,CSM,CSM_AV,VCU
 SG_ StBltTghtngCstAvlFlg5 : 36|1@0+ (1,0) [0|1] "" RadioLow,CSM,CSM_AV,VCU
 SG_ StBltTghtngCstAvlFlg4 : 37|1@0+ (1,0) [0|1] "" RadioLow,CSM,CSM_AV,VCU
 SG_ StBltTghtngCstAvlFlg3 : 38|1@0+ (1,0) [0|1] "" RadioLow,CSM,CSM_AV,VCU
 SG_ StBltTghtngCstAvlFlg2 : 39|1@0+ (1,0) [0|1] "" RadioLow,CSM,CSM_AV,VCU
 SG_ TrlrMirVidEnblCstAvlFlg3 : 40|1@0+ (1,0) [0|1] "" RadioLow,CSM,CSM_AV,VCU
 SG_ TrlrMirVidEnblCstAvlFlg2 : 41|1@0+ (1,0) [0|1] "" RadioLow,CSM,CSM_AV,VCU
 SG_ TrlrMirVidEnblCstAvlFlg1 : 42|1@0+ (1,0) [0|1] "" RadioLow,CSM,CSM_AV,VCU
 SG_ TnDrvStBltShfIntlkCstAvlFlg7 : 43|1@0+ (1,0) [0|1] "" RadioLow,CSM,CSM_AV,VCU
 SG_ TnDrvStBltShfIntlkCstAvlFlg6 : 44|1@0+ (1,0) [0|1] "" RadioLow,CSM,CSM_AV,VCU
 SG_ TnDrvStBltShfIntlkCstAvlFlg5 : 45|1@0+ (1,0) [0|1] "" RadioLow,CSM,CSM_AV,VCU
 SG_ TnDrvStBltShfIntlkCstAvlFlg4 : 46|1@0+ (1,0) [0|1] "" RadioLow,CSM,CSM_AV,VCU
 SG_ TnDrvStBltShfIntlkCstAvlFlg3 : 47|1@0+ (1,0) [0|1] "" RadioLow,CSM,CSM_AV,VCU
 SG_ TrlrMirVidGdlnsCstAvlFlg4 : 48|1@0+ (1,0) [0|1] "" RadioLow,CSM,CSM_AV,VCU
 SG_ TrlrMirVidGdlnsCstAvlFlg3 : 49|1@0+ (1,0) [0|1] "" RadioLow,CSM,CSM_AV,VCU
 SG_ TrlrMirVidGdlnsCstAvlFlg2 : 50|1@0+ (1,0) [0|1] "" RadioLow,CSM,CSM_AV,VCU
 SG_ TrlrMirVidGdlnsCstAvlFlg1 : 51|1@0+ (1,0) [0|1] "" RadioLow,CSM,CSM_AV,VCU
 SG_ TrlrMirVidEnblCstAvlFlg7 : 52|1@0+ (1,0) [0|1] "" RadioLow,CSM,CSM_AV,VCU
 SG_ TrlrMirVidEnblCstAvlFlg6 : 53|1@0+ (1,0) [0|1] "" RadioLow,CSM,CSM_AV,VCU
 SG_ TrlrMirVidEnblCstAvlFlg5 : 54|1@0+ (1,0) [0|1] "" RadioLow,CSM,CSM_AV,VCU
 SG_ TrlrMirVidEnblCstAvlFlg4 : 55|1@0+ (1,0) [0|1] "" RadioLow,CSM,CSM_AV,VCU
 SG_ CrshEvntEnbld : 58|1@0+ (1,0) [0|1] "" TCP
 SG_ TmngBltChgIndOn : 59|1@0+ (1,0) [0|1] "" IPC,IPC_INT,VCU
 SG_ TrnsOlTmpSnsPrs : 60|1@0+ (1,0) [0|1] "" TCP,CSM,CSM_AV,VCU
 SG_ TrlrMirVidGdlnsCstAvlFlg7 : 61|1@0+ (1,0) [0|1] "" RadioLow,CSM,CSM_AV,VCU
 SG_ TrlrMirVidGdlnsCstAvlFlg6 : 62|1@0+ (1,0) [0|1] "" RadioLow,CSM,CSM_AV,VCU
 SG_ TrlrMirVidGdlnsCstAvlFlg5 : 63|1@0+ (1,0) [0|1] "" RadioLow,CSM,CSM_AV,VCU

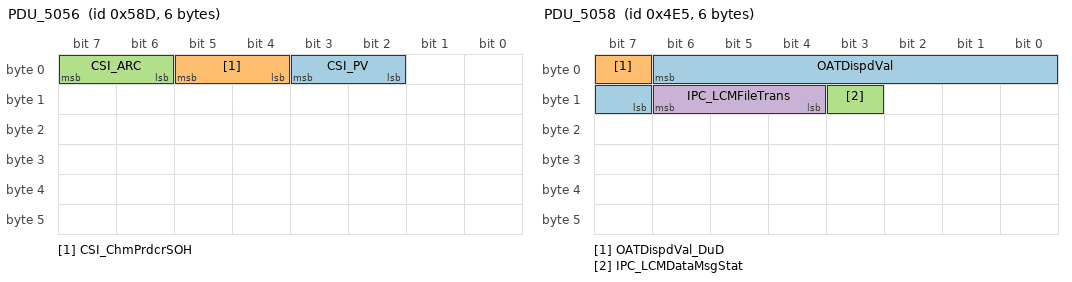
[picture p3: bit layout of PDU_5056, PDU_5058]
BO_ 1421 PDU_5056: 6 RadioLow
 SG_ CSI_PV : 3|2@0+ (1,0) [0|3] "" IPC,IPC_INT
 SG_ CSI_ChmPrdcrSOH : 5|2@0+ (1,0) [0|2] "" CGM,IPC,IPC_INT
 SG_ CSI_ARC : 7|2@0+ (1,0) [0|3] "" IPC,IPC_INT

BO_ 1514 PDU_5057: 6 RadioLow
 SG_ ClstrDspAnmReq : 7|3@0+ (1,0) [0|4] "" IPC,IPC_INT

BO_ 1253 PDU_5058: 6 RadioLow
 SG_ OATDispdVal : 6|8@0+ (1,-40) [-40|215] "" IPC,IPC_INT
 SG_ OATDispdVal_DuD : 7|1@0+ (1,0) [0|1] "" IPC,IPC_INT
 SG_ IPC_LCMDataMsgStat : 11|1@0+ (1,0) [0|1] "" IPC,IPC_INT
 SG_ IPC_LCMFileTrans : 14|3@0+ (1,0) [0|4] "" IPC,IPC_INT

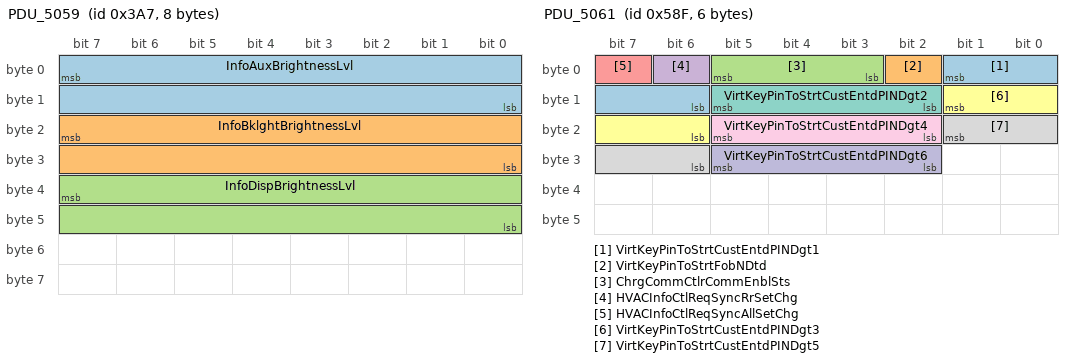
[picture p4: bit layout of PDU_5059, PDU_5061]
BO_ 935 PDU_5059: 8 RadioLow
 SG_ InfoAuxBrightnessLvl : 7|16@0+ (0.001526,0) [0|100.006] "%" ICS_Info,MFC
 SG_ InfoBklghtBrightnessLvl : 23|16@0+ (0.001526,0) [0|100.006] "%" ICS_Info,MFC
 SG_ InfoDispBrightnessLvl : 39|16@0+ (0.001526,0) [0|100.006] "%" FPI,ICS_Info,MFC,RSI

BO_ 1422 PDU_5060: 8 RadioLow
 SG_ HVACICRTLR_LtLvlActv : 0|1@0+ (1,0) [0|1] "" CGM
 SG_ HVACICRTLR_LtLvl : 7|7@0+ (1,-16) [-16|111] "" CGM
 SG_ HVACICRTLR_RtLvlActv : 8|1@0+ (1,0) [0|1] "" CGM
 SG_ HVACICRTLR_RtLvl : 15|7@0+ (1,-16) [-16|111] "" CGM
 SG_ ChmPrdcrStat : 23|12@0+ (1,0) [0|4095] "msec" AMP,IPC,IPC_INT
 SG_ HVACICRADSR_LtSet : 27|4@0+ (1,0) [0|8] "" CGM
 SG_ HVACICRTLCR_RtLvlChg : 32|3@0- (1,0) [-4|3] "" CGM
 SG_ HVACICRTLCR_LtLvlChg : 35|3@0- (1,0) [-4|3] "" CGM
 SG_ HVACICRADSR_RtSet : 39|4@0+ (1,0) [0|8] "" CGM
 SG_ HVACICRBLR_Lvl : 40|4@0+ (1,0) [0|15] "" CGM
 SG_ HVACInfoCtlReqBlwLvlChgRr : 45|5@0- (1,0) [-16|15] "" CGM
 SG_ HVACInfoCtlReqRrDfgSet : 48|2@0+ (1,0) [0|2] "" CGM
 SG_ HVACInfoCtlReqSyncSet : 51|3@0+ (1,0) [0|6] "" CGM
 SG_ HVACICRBLR_LvlActv : 52|1@0+ (1,0) [0|1] "" CGM
 SG_ HVACInfoCtlReqRrPwrSetChg : 56|1@0+ (1,0) [0|1] "" CGM
 SG_ HVACInfoCtlReqRrLckSetChg : 57|1@0+ (1,0) [0|1] "" CGM
 SG_ HVACInfoCtlReqRrDfgSetChg : 58|1@0+ (1,0) [0|1] "" CGM
 SG_ HVACInfoCtlReqRrAutoSetChg : 59|1@0+ (1,0) [0|1] "" CGM
 SG_ HVACInfoCtlReqBlwSpdRdct : 60|1@0+ (1,0) [0|1] "" CGM
 SG_ HVACICRADSCR_RtChgNext : 61|1@0+ (1,0) [0|1] "" CGM
 SG_ HVACICRADSCR_LtChgNext : 62|1@0+ (1,0) [0|1] "" CGM

BO_ 1423 PDU_5061: 6 RadioLow
 SG_ VirtKeyPinToStrtCustEntdPINDgt1 : 1|4@0+ (1,0) [0|15] "" VKM
 SG_ VirtKeyPinToStrtFobNDtd : 2|1@0+ (1,0) [0|1] "" VKM
 SG_ ChrgCommCtlrCommEnblSts : 5|3@0+ (1,0) [0|5] "" PLCM
 SG_ HVACInfoCtlReqSyncRrSetChg : 6|1@0+ (1,0) [0|1] "" CGM
 SG_ HVACInfoCtlReqSyncAllSetChg : 7|1@0+ (1,0) [0|1] "" CGM
 SG_ VirtKeyPinToStrtCustEntdPINDgt3 : 9|4@0+ (1,0) [0|15] "" VKM
 SG_ VirtKeyPinToStrtCustEntdPINDgt2 : 13|4@0+ (1,0) [0|15] "" VKM
 SG_ VirtKeyPinToStrtCustEntdPINDgt5 : 17|4@0+ (1,0) [0|15] "" VKM
 SG_ VirtKeyPinToStrtCustEntdPINDgt4 : 21|4@0+ (1,0) [0|15] "" VKM
 SG_ VirtKeyPinToStrtCustEntdPINDgt6 : 29|4@0+ (1,0) [0|15] "" VKM

BA_DEF_ SG_  "SignalType" STRING ;
BA_DEF_ SG_  "SignalLongName" STRING ;
BA_DEF_ BO_  "GenMsgCycleTime" INT 0 10000;
BA_DEF_ BO_  "GenMsgSendType" ENUM "cyclicX","spontanX","cyclicIfActiveX","spontanWithDelay","cyclicAndSpontanX","cyclicAndSpontanWithDelay","spontanWithRepetition","cyclicIfActiveAndSpontanWD";
BA_DEF_DEF_  "SignalType" "";
BA_DEF_DEF_  "SignalLongName" "";
BA_DEF_DEF_  "GenMsgCycleTime" 0;
BA_DEF_DEF_  "GenMsgSendType" "cyclicX";
BA_ "GenMsgCycleTime" BO_ 1485 1000;
BA_ "GenMsgCycleTime" BO_ 1486 1000;
BA_ "GenMsgCycleTime" BO_ 1487 1000;
BA_ "GenMsgCycleTime" BO_ 1488 1000;
BA_ "GenMsgCycleTime" BO_ 1489 1000;
BA_ "GenMsgCycleTime" BO_ 1490 1000;
BA_ "GenMsgCycleTime" BO_ 1526 1000;
BA_ "GenMsgCycleTime" BO_ 1527 1000;
BA_ "GenMsgCycleTime" BO_ 1528 1000;
BA_ "GenMsgCycleTime" BO_ 1529 1000;
BA_ "GenMsgCycleTime" BO_ 1530 1000;
BA_ "GenMsgCycleTime" BO_ 1531 1000;
BA_ "GenMsgCycleTime" BO_ 1532 1000;
BA_ "GenMsgCycleTime" BO_ 1533 1000;
BA_ "GenMsgCycleTime" BO_ 1276 1000;
BA_ "GenMsgCycleTime" BO_ 1534 1000;
BA_ "GenMsgCycleTime" BO_ 1824 1000;
BA_ "GenMsgCycleTime" BO_ 1241 1000;
BA_ "GenMsgCycleTime" BO_ 1825 1000;
BA_ "GenMsgCycleTime" BO_ 1240 1000;
BA_ "GenMsgCycleTime" BO_ 1826 1000;
BA_ "GenMsgCycleTime" BO_ 1421 1000;
BA_ "GenMsgCycleTime" BO_ 1514 1000;
BA_ "GenMsgCycleTime" BO_ 1253 1000;
BA_ "GenMsgCycleTime" BO_ 935 250;
BA_ "GenMsgCycleTime" BO_ 1422 1000;
BA_ "GenMsgCycleTime" BO_ 1423 1000;
BA_ "SignalLongName" SG_ 1485 PAVehPathCrv "Park Assist HMI Information : Park Assist Vehicle Path Curvature";
BA_ "SignalType" SG_ 1485 FourWhlDrvWrnIndReq "ENM";
BA_ "SignalLongName" SG_ 1485 FourWhlDrvWrnIndReq "Four Wheel Drive Mode Information : Four Wheel Drive Warning Indication Request";
BA_ "SignalType" SG_ 1485 PAVisObjIndStatReq "ENM";
BA_ "SignalLongName" SG_ 1485 PAVisObjIndStatReq "Park Assist HMI Information : Park Assist Visual Object Indication State Request";
BA_ "SignalLongName" SG_ 1485 XferCaseRngShfSpdLim "Four Wheel Drive Mode Information : Transfer Case Range Shift Speed Limit";
BA_ "SignalLongName" SG_ 1485 SAP_SecAxl4WDAWDEstTrqAuth "Secondary Axle Protected : Secondary Axle 4WD AWD Estimated Torque Authenticated";
BA_ "SignalType" SG_ 1485 SAP_SecAxl4WDAWDEstTrqAuth_Inv "ENM";
BA_ "SignalLongName" SG_ 1485 SAP_SecAxl4WDAWDEstTrqAuth_Inv "Secondary Axle Protected : Secondary Axle 4WD AWD Estimated Torque Authenticated Invalid";
BA_ "SignalType" SG_ 1485 EDADS_CrntFwdMsdGr "ENM";
BA_ "SignalLongName" SG_ 1485 EDADS_CrntFwdMsdGr "ECO Drive Assist Display State : Current Forward Measured Gear";
BA_ "SignalType" SG_ 1485 EDADS_ShftIndSt "ENM";
BA_ "SignalLongName" SG_ 1485 EDADS_ShftIndSt "ECO Drive Assist Display State : Shift Indication State";
BA_ "SignalType" SG_ 1485 EDADS_RcmndtFwdGr "ENM";
BA_ "SignalLongName" SG_ 1485 EDADS_RcmndtFwdGr "ECO Drive Assist Display State : Recommended Forward Gear";
BA_ "SignalType" SG_ 1485 EDADS_EcoDrvShftIO "ENM";
BA_ "SignalLongName" SG_ 1485 EDADS_EcoDrvShftIO "ECO Drive Assist Display State : ECO Drive Assist Shift Indication On";
BA_ "SignalType" SG_ 1485 PAIM_SnsrDstbdIndOn "ENM";
BA_ "SignalLongName" SG_ 1485 PAIM_SnsrDstbdIndOn "Park Assist Indication Messages : Sensor Disturbed Indication On";
BA_ "SignalType" SG_ 1485 PAIM_SnsrClnIndOn "ENM";
BA_ "SignalLongName" SG_ 1485 PAIM_SnsrClnIndOn "Park Assist Indication Messages : Sensor Clean Indication On";
BA_ "SignalType" SG_ 1485 PAIM_SnsrBlckdIndOn "ENM";
BA_ "SignalLongName" SG_ 1485 PAIM_SnsrBlckdIndOn "Park Assist Indication Messages : Sensor Blocked Indication On";
BA_ "SignalType" SG_ 1485 PAIM_RrOffIndOn "ENM";
BA_ "SignalLongName" SG_ 1485 PAIM_RrOffIndOn "Park Assist Indication Messages : Rear Off Indication On";
BA_ "SignalType" SG_ 1485 PAIM_OffIndOn "ENM";
BA_ "SignalLongName" SG_ 1485 PAIM_OffIndOn "Park Assist Indication Messages : Off Indication On";
BA_ "SignalType" SG_ 1485 PAIM_FrtOffIndOn "ENM";
BA_ "SignalLongName" SG_ 1485 PAIM_FrtOffIndOn "Park Assist Indication Messages : Front Off Indication On";
BA_ "SignalType" SG_ 1485 PAIM_FaildIndOn "ENM";
BA_ "SignalLongName" SG_ 1485 PAIM_FaildIndOn "Park Assist Indication Messages : Failed Indication O";
BA_ "SignalType" SG_ 1485 PAIM_DsbldIndOn "ENM";
BA_ "SignalLongName" SG_ 1485 PAIM_DsbldIndOn "Park Assist Indication Messages : Disabled Indication On";
BA_ "SignalLongName" SG_ 1485 EngAirFiltLifeRmn "Engine Air Filter Life Remaining";
BA_ "SignalType" SG_ 1485 PAIM_TeenDrvrPAOffUnvIndOn "ENM";
BA_ "SignalLongName" SG_ 1485 PAIM_TeenDrvrPAOffUnvIndOn "Park Assist Indication Messages : Teen Driver Off Unavailable Indication On";
BA_ "SignalLongName" SG_ 1486 DrvEffInd "Drive Efficiency Indication";
BA_ "SignalLongName" SG_ 1486 OATP_OtsAirTmpAuth "Serial Data 25 Protected : Outside Air Temperature Authenticated";
BA_ "SignalType" SG_ 1486 VwgVwprtReq "ENM";
BA_ "SignalLongName" SG_ 1486 VwgVwprtReq "Viewing Viewport Request";
BA_ "SignalType" SG_ 1486 SAP_SecAxlOpMdAuth "ENM";
BA_ "SignalLongName" SG_ 1486 SAP_SecAxlOpMdAuth "Secondary Axle Protected : Secondary Axle Operational Mode Authenticated";
BA_ "SignalType" SG_ 1486 SAP_SecAxlOpMdAuth_Inv "ENM";
BA_ "SignalLongName" SG_ 1486 SAP_SecAxlOpMdAuth_Inv "Secondary Axle Protected : Secondary Axle Operational Mode Authenticated Invalid";
BA_ "SignalType" SG_ 1486 EnrgMgtLdShdRq "ENM";
BA_ "SignalLongName" SG_ 1486 EnrgMgtLdShdRq "Energy Management Load Shedding Request";
BA_ "SignalType" SG_ 1486 VwgVwprtSts "ENM";
BA_ "SignalLongName" SG_ 1486 VwgVwprtSts "Viewing Viewport Status";
BA_ "SignalType" SG_ 1486 MemCmd "ENM";
BA_ "SignalLongName" SG_ 1486 MemCmd "Memory Command";
BA_ "SignalType" SG_ 1486 FrntPsStbltRmIndReq "ENM";
BA_ "SignalLongName" SG_ 1486 FrntPsStbltRmIndReq "Front Passenger Seat Belt Reminder Indication Request";
BA_ "SignalType" SG_ 1486 TireLFLoTracIndOn "ENM";
BA_ "SignalLongName" SG_ 1486 TireLFLoTracIndOn "Tire Low Traction Information : Tire Left Front Low Traction Indication On";
BA_ "SignalType" SG_ 1486 MemIdfrIgnOnIndReq "ENM";
BA_ "SignalLongName" SG_ 1486 MemIdfrIgnOnIndReq "Memory Identifier Ignition On Indication Request";
BA_ "SignalType" SG_ 1486 AutMemRclCstCurSetVal "ENM";
BA_ "SignalLongName" SG_ 1486 AutMemRclCstCurSetVal "AutoMemoryRecallCustomizationCurrentSettingValue";
BA_ "SignalType" SG_ 1486 AdpLghtRspTypCstCurSetVal "ENM";
BA_ "SignalLongName" SG_ 1486 AdpLghtRspTypCstCurSetVal "Adaptive Lighting Response Type Customization Current Setting Value";
BA_ "SignalType" SG_ 1486 TireRRLoTracIndOn "ENM";
BA_ "SignalLongName" SG_ 1486 TireRRLoTracIndOn "Tire Low Traction Information : Tire Right Rear Low Traction Indication On";
BA_ "SignalType" SG_ 1486 TireRFLoTracIndOn "ENM";
BA_ "SignalLongName" SG_ 1486 TireRFLoTracIndOn "Tire Low Traction Information : Tire Right Front Low Traction Indication On";
BA_ "SignalType" SG_ 1486 TireLRLoTracIndOn "ENM";
BA_ "SignalLongName" SG_ 1486 TireLRLoTracIndOn "Tire Low Traction Information : Tire Left Rear Low Traction Indication On";
BA_ "SignalType" SG_ 1486 AutMemRclCstStAvl "ENM";
BA_ "SignalLongName" SG_ 1486 AutMemRclCstStAvl "AutoMemoryRecallCustomizationSettingAvailable";
BA_ "SignalType" SG_ 1486 CTDStat "ENM";
BA_ "SignalLongName" SG_ 1486 CTDStat "Content Theft Deterrent State";
BA_ "SignalType" SG_ 1486 BrkSysHillStrtAsstStat "ENM";
BA_ "SignalLongName" SG_ 1486 BrkSysHillStrtAsstStat "Brake System Hill Start Assist Status";
BA_ "SignalType" SG_ 1487 CnvtblTpWndMtnReq "ENM";
BA_ "SignalLongName" SG_ 1487 CnvtblTpWndMtnReq "Convertible Top Window Motion Request";
BA_ "SignalType" SG_ 1487 CnvtBkWndPstnSts "ENM";
BA_ "SignalLongName" SG_ 1487 CnvtBkWndPstnSts "Convertible Back Window Position Status";
BA_ "SignalType" SG_ 1487 CTGI2P_CnvtTopStsAuth "ENM";
BA_ "SignalLongName" SG_ 1487 CTGI2P_CnvtTopStsAuth "Convertible Top General Information 2 Protected : Convertible Top Status Authenticated";
BA_ "SignalType" SG_ 1487 FrntPsStBltRmOccStat_Inv "ENM";
BA_ "SignalLongName" SG_ 1487 FrntPsStBltRmOccStat_Inv "Front Passenger Seat Belt Reminder Occupancy Status Invalid";
BA_ "SignalType" SG_ 1487 EsyExtCstCurSetVal "ENM";
BA_ "SignalLongName" SG_ 1487 EsyExtCstCurSetVal "EasyExitCustomizationCurrentSettingValue";
BA_ "SignalType" SG_ 1487 CrgBedVwAutoLgtCstCurrSetVal "ENM";
BA_ "SignalLongName" SG_ 1487 CrgBedVwAutoLgtCstCurrSetVal "Cargo Bed View Auto Lighting CustomizationCurrent Setting Value";
BA_ "SignalType" SG_ 1487 FrwdVhImAlrtIndRqst "ENM";
BA_ "SignalLongName" SG_ 1487 FrwdVhImAlrtIndRqst "Forward Vehicle Imminent Alert Indication Request";
BA_ "SignalType" SG_ 1487 FrtRdHgtGPSCstCurrSetVal "ENM";
BA_ "SignalLongName" SG_ 1487 FrtRdHgtGPSCstCurrSetVal "Front Ride Height GPS Customization Current Setting Value";
BA_ "SignalType" SG_ 1487 FrntPsStBltRmOccStat "ENM";
BA_ "SignalLongName" SG_ 1487 FrntPsStBltRmOccStat "Front Passenger Seat Belt Reminder Occupancy Status";
BA_ "SignalType" SG_ 1487 HybStatElecVehModeOvrrd "ENM";
BA_ "SignalLongName" SG_ 1487 HybStatElecVehModeOvrrd "Hybrid State Electric Vehicle Mode Override";
BA_ "SignalType" SG_ 1487 HSP_DrvAlrtTypCstCurrSetValAuth "ENM";
BA_ "SignalLongName" SG_ 1487 HSP_DrvAlrtTypCstCurrSetValAuth "Haptic Seat Protected : Driver Alert Type Customization Current Setting Value Authenticated";
BA_ "SignalType" SG_ 1487 GoNotfrCstCrStVal "ENM";
BA_ "SignalLongName" SG_ 1487 GoNotfrCstCrStVal "Go Notifier Customization Current Setting Value";
BA_ "SignalType" SG_ 1487 LtRtHnTrCstCurSetVal "ENM";
BA_ "SignalLongName" SG_ 1487 LtRtHnTrCstCurSetVal "Left Right Hand Traffic Customization Current Setting Value";
BA_ "SignalType" SG_ 1487 LnDtWrnCntrlFtrSt "ENM";
BA_ "SignalLongName" SG_ 1487 LnDtWrnCntrlFtrSt "Lane Detection Warning and Control Feature State";
BA_ "SignalType" SG_ 1487 JckKnfDtnCstCurrSetVal "ENM";
BA_ "SignalLongName" SG_ 1487 JckKnfDtnCstCurrSetVal "Jack Knife Detection Customization Current Setting Value";
BA_ "SignalType" SG_ 1487 LvlgSysEntEgrsMdCstCurrSetVal "ENM";
BA_ "SignalLongName" SG_ 1487 LvlgSysEntEgrsMdCstCurrSetVal "Leveling System Entry Egress Mode Customization Current Setting Value";
BA_ "SignalType" SG_ 1487 LvlgSysAlgnMdCstCurrSetVal "ENM";
BA_ "SignalLongName" SG_ 1487 LvlgSysAlgnMdCstCurrSetVal "Leveling System Alignment Mode Customization Current Setting Value";
BA_ "SignalType" SG_ 1487 PrkAsstONOFFCstCrStVal "ENM";
BA_ "SignalLongName" SG_ 1487 PrkAsstONOFFCstCrStVal "Park Assist On Off Customization Current Setting Value";
BA_ "SignalType" SG_ 1487 NghtVsnSysStat "ENM";
BA_ "SignalLongName" SG_ 1487 NghtVsnSysStat "Night Vision System Status";
BA_ "SignalType" SG_ 1487 LvlgSysServMdCstCurrSetVal "ENM";
BA_ "SignalLongName" SG_ 1487 LvlgSysServMdCstCurrSetVal "Leveling System Service Mode Customization Current Setting Value";
BA_ "SignalType" SG_ 1487 AutoHldEnbld "ENM";
BA_ "SignalLongName" SG_ 1487 AutoHldEnbld "Auto Hold Enabled";
BA_ "SignalType" SG_ 1487 PrkAsstTrHtchPsntCstCrStVal "ENM";
BA_ "SignalLongName" SG_ 1487 PrkAsstTrHtchPsntCstCrStVal "Park Assist Trailer Hitch Present Customization Current Setting Value";
BA_ "SignalType" SG_ 1487 PrkAsstStat "ENM";
BA_ "SignalLongName" SG_ 1487 PrkAsstStat "Park Assist Status";
BA_ "SignalType" SG_ 1488 PrsnlMdStrCstmCurSetVal "ENM";
BA_ "SignalLongName" SG_ 1488 PrsnlMdStrCstmCurSetVal "Personal Mode Steering Customization Current Setting Value";
BA_ "SignalType" SG_ 1488 PrsnlMdSpnCstmCurSetVal "ENM";
BA_ "SignalLongName" SG_ 1488 PrsnlMdSpnCstmCurSetVal "Personal Mode Suspension Customization Current Setting Value";
BA_ "SignalType" SG_ 1488 PrsnlMdSndCstmCurSetVal "ENM";
BA_ "SignalLongName" SG_ 1488 PrsnlMdSndCstmCurSetVal "Personal Mode Sound Customization Current Setting Value";
BA_ "SignalType" SG_ 1488 RideHghtSeltn3Name "ENM";
BA_ "SignalLongName" SG_ 1488 RideHghtSeltn3Name "Ride Height Selection 3 Name";
BA_ "SignalType" SG_ 1488 RideHghtSeltn2Name "ENM";
BA_ "SignalLongName" SG_ 1488 RideHghtSeltn2Name "Ride Height Selection 2 Name";
BA_ "SignalType" SG_ 1488 RideHghtSeltn1Name "ENM";
BA_ "SignalLongName" SG_ 1488 RideHghtSeltn1Name "Ride Height Selection 1 Name";
BA_ "SignalType" SG_ 1488 RideHghtSeltn5Name "ENM";
BA_ "SignalLongName" SG_ 1488 RideHghtSeltn5Name "Ride Height Selection 5 Name";
BA_ "SignalType" SG_ 1488 RideHghtSeltn4Name "ENM";
BA_ "SignalLongName" SG_ 1488 RideHghtSeltn4Name "Ride Height Selection 4 Name";
BA_ "SignalType" SG_ 1488 RideHghtSeltn8Name "ENM";
BA_ "SignalLongName" SG_ 1488 RideHghtSeltn8Name "Ride Height Selection 8 Name";
BA_ "SignalType" SG_ 1488 RideHghtSeltn7Name "ENM";
BA_ "SignalLongName" SG_ 1488 RideHghtSeltn7Name "Ride Height Selection 7 Name";
BA_ "SignalType" SG_ 1488 RideHghtSeltn6Name "ENM";
BA_ "SignalLongName" SG_ 1488 RideHghtSeltn6Name "Ride Height Selection 6 Name";
BA_ "SignalType" SG_ 1488 RrVwPrkAstSymCsCrStVal "ENM";
BA_ "SignalLongName" SG_ 1488 RrVwPrkAstSymCsCrStVal "Rear View Park Assist Symbol Customization Current Setting Value";
BA_ "SignalType" SG_ 1488 RnngBrdManDplyCstCurrSetVal "ENM";
BA_ "SignalLongName" SG_ 1488 RnngBrdManDplyCstCurrSetVal "Running Boards Manual Deployment Customization Current Setting Value";
BA_ "SignalType" SG_ 1488 RnngBrdAutoDplyCstCurrSetVal "ENM";
BA_ "SignalLongName" SG_ 1488 RnngBrdAutoDplyCstCurrSetVal "Running Boards Automatic Deployment Customization Current Setting Value";
BA_ "SignalType" SG_ 1488 StBltShfIntlkCstCurrSetVal "ENM";
BA_ "SignalLongName" SG_ 1488 StBltShfIntlkCstCurrSetVal "Seat Belt Shift Interlock Customization Current Setting Value";
BA_ "SignalType" SG_ 1488 SrrndVwLghtCsCrStVal "ENM";
BA_ "SignalLongName" SG_ 1488 SrrndVwLghtCsCrStVal "Surround View Lighting Customization Current Setting Value";
BA_ "SignalType" SG_ 1488 TrlrMirVidGdlnsCstCurrSetVal "ENM";
BA_ "SignalLongName" SG_ 1488 TrlrMirVidGdlnsCstCurrSetVal "Trailering Mirror Video Guidelines Customization Current Setting Value";
BA_ "SignalType" SG_ 1488 TnDrvStBltShfIntlkCstCurrSetVal "ENM";
BA_ "SignalLongName" SG_ 1488 TnDrvStBltShfIntlkCstCurrSetVal "Teen Driver Seat Belt Shift Interlock Customization Current Setting Value";
BA_ "SignalType" SG_ 1488 StBltTghtngCstCrStVal "ENM";
BA_ "SignalLongName" SG_ 1488 StBltTghtngCstCrStVal "Seat Belt Tightening Customization Current Setting Value";
BA_ "SignalType" SG_ 1488 BrkLtsAtv "ENM";
BA_ "SignalLongName" SG_ 1488 BrkLtsAtv "Brake Lights Active";
BA_ "SignalType" SG_ 1488 APAExtPrkSftBtnRqst "ENM";
BA_ "SignalLongName" SG_ 1488 APAExtPrkSftBtnRqst "Advanced Park Assist Exit Park Soft Button Request";
BA_ "SignalType" SG_ 1488 APACrssFrntInSftBtnRqst "ENM";
BA_ "SignalLongName" SG_ 1488 APACrssFrntInSftBtnRqst "Advanced Park Assist Cross Front-In Soft Button Reques";
BA_ "SignalType" SG_ 1488 APACrssBckInSftBtnRqst "ENM";
BA_ "SignalLongName" SG_ 1488 APACrssBckInSftBtnRqst "Advanced Park Assist Cross Back-In Soft Button Request";
BA_ "SignalType" SG_ 1489 APASrchSftBtnRqst "ENM";
BA_ "SignalLongName" SG_ 1489 APASrchSftBtnRqst "Advanced Park Assist Searching Soft Button Request";
BA_ "SignalType" SG_ 1489 APARghtSftBtnRqst "ENM";
BA_ "SignalLongName" SG_ 1489 APARghtSftBtnRqst "Advanced Park Assist Right Soft Button Request";
BA_ "SignalType" SG_ 1489 APAPrllPrkSftBtnRqst "ENM";
BA_ "SignalLongName" SG_ 1489 APAPrllPrkSftBtnRqst "Advanced Park Assist Parallel Parking Soft Button Request";
BA_ "SignalType" SG_ 1489 APALftSftBtnRqst "ENM";
BA_ "SignalLongName" SG_ 1489 APALftSftBtnRqst "Advanced Park Assist Left Soft Button Request";
BA_ "SignalType" SG_ 1489 EngCmptAjr "ENM";
BA_ "SignalLongName" SG_ 1489 EngCmptAjr "Engine Compartment Ajar";
BA_ "SignalType" SG_ 1489 EngCmptAjr_Inv "ENM";
BA_ "SignalLongName" SG_ 1489 EngCmptAjr_Inv "Engine Compartment Ajar Invalid";
BA_ "SignalType" SG_ 1489 ElvtdIdlCstCrStVal "ENM";
BA_ "SignalLongName" SG_ 1489 ElvtdIdlCstCrStVal "Elevated Idle Customization Current Setting Value";
BA_ "SignalType" SG_ 1489 DrvDrAjrStat "ENM";
BA_ "SignalLongName" SG_ 1489 DrvDrAjrStat "Driver Door Ajar Status";
BA_ "SignalType" SG_ 1489 DrvDrAjrStat_Inv "ENM";
BA_ "SignalLongName" SG_ 1489 DrvDrAjrStat_Inv "Driver Door Ajar Status Invalid";
BA_ "SignalType" SG_ 1489 CoDrvDrAjrStat "ENM";
BA_ "SignalLongName" SG_ 1489 CoDrvDrAjrStat "Co-Driver Door Ajar Status";
BA_ "SignalType" SG_ 1489 CoDrvDrAjrStat_Inv "ENM";
BA_ "SignalLongName" SG_ 1489 CoDrvDrAjrStat_Inv "Co-Driver Door Ajar Status Invalid";
BA_ "SignalType" SG_ 1489 LftglsAjrStat "ENM";
BA_ "SignalLongName" SG_ 1489 LftglsAjrStat "Liftglass Ajar Status";
BA_ "SignalType" SG_ 1489 LftglsAjrStat_Inv "ENM";
BA_ "SignalLongName" SG_ 1489 LftglsAjrStat_Inv "Liftglass Ajar Status Invalid";
BA_ "SignalType" SG_ 1489 LRDrAjrStat "ENM";
BA_ "SignalLongName" SG_ 1489 LRDrAjrStat "Left Rear Door Ajar Status";
BA_ "SignalType" SG_ 1489 LRDrAjrStat_Inv "ENM";
BA_ "SignalLongName" SG_ 1489 LRDrAjrStat_Inv "Left Rear Door Ajar Status Invalid";
BA_ "SignalType" SG_ 1489 InvsblTrlrOprtlSts "ENM";
BA_ "SignalLongName" SG_ 1489 InvsblTrlrOprtlSts "Invisible Trailer Operational Status";
BA_ "SignalType" SG_ 1489 HSP_HptcStOprtlStsAuth "ENM";
BA_ "SignalLongName" SG_ 1489 HSP_HptcStOprtlStsAuth "Haptic Seat Protected : Haptic Seat Operational Status Authenticated";
BA_ "SignalType" SG_ 1489 SAP_SecAxl4WDAWDStatAuth "ENM";
BA_ "SignalLongName" SG_ 1489 SAP_SecAxl4WDAWDStatAuth "Secondary Axle Protected : Secondary Axle 4WD AWD Status Authenticated";
BA_ "SignalType" SG_ 1489 RRDrAjrStat "ENM";
BA_ "SignalLongName" SG_ 1489 RRDrAjrStat "Right Rear Door Ajar Status";
BA_ "SignalType" SG_ 1489 RRDrAjrStat_Inv "ENM";
BA_ "SignalLongName" SG_ 1489 RRDrAjrStat_Inv "Right Rear Door Ajar Status Invalid";
BA_ "SignalType" SG_ 1489 LogisticModeStatus "ENM";
BA_ "SignalLongName" SG_ 1489 LogisticModeStatus "Logistic Mode Status";
BA_ "SignalType" SG_ 1489 LnCntrEsclnSts "ENM";
BA_ "SignalLongName" SG_ 1489 LnCntrEsclnSts "Lane Centering Escalation Status";
BA_ "SignalType" SG_ 1489 CIBAutoBrkReqActv "ENM";
BA_ "SignalLongName" SG_ 1489 CIBAutoBrkReqActv "Collision Imminent Braking Autonomous Brake Request Active";
BA_ "SignalType" SG_ 1489 CIBAutoBrkRelIndOn "ENM";
BA_ "SignalLongName" SG_ 1489 CIBAutoBrkRelIndOn "Collision Imminent Braking Autonomous Brake Release Indication On";
BA_ "SignalType" SG_ 1489 APAVMR_SloDnIndOn "ENM";
BA_ "SignalLongName" SG_ 1489 APAVMR_SloDnIndOn "Advanced Park Assist Visual Message Requests : Advanced Park Assist Slow Down Indication On";
BA_ "SignalType" SG_ 1489 APAVMR_NAvalIndOn "ENM";
BA_ "SignalLongName" SG_ 1489 APAVMR_NAvalIndOn "Advanced Park Assist Visual Message Requests : Advanced Park Assist Not Available Indication On";
BA_ "SignalType" SG_ 1489 TrnSwAct "ENM";
BA_ "SignalLongName" SG_ 1489 TrnSwAct "Turn Switch Activation";
BA_ "SignalType" SG_ 1489 TrlrTirePresProfXferSts "ENM";
BA_ "SignalLongName" SG_ 1489 TrlrTirePresProfXferSts "Trailer Tire Pressure Profile Transfer Status";
BA_ "SignalType" SG_ 1489 CkSoftTpIO "ENM";
BA_ "SignalLongName" SG_ 1489 CkSoftTpIO "Check Soft Top Indication On";
BA_ "SignalType" SG_ 1489 CkRrPrkLmpIndOn "ENM";
BA_ "SignalLongName" SG_ 1489 CkRrPrkLmpIndOn "Check Rear Park Lamp Indication On";
BA_ "SignalType" SG_ 1489 CkLoBmsIndOn "ENM";
BA_ "SignalLongName" SG_ 1489 CkLoBmsIndOn "Check Low Beams Indication On";
BA_ "SignalType" SG_ 1489 CkFrtPrkLmpsIndOn "ENM";
BA_ "SignalLongName" SG_ 1489 CkFrtPrkLmpsIndOn "Check Front Park Lamps Indication On";
BA_ "SignalType" SG_ 1489 CkFgLmpsIndOn "ENM";
BA_ "SignalLongName" SG_ 1489 CkFgLmpsIndOn "Check Fog Lamps Indication On";
BA_ "SignalType" SG_ 1489 CkDyTmRnngLmpsIndOn "ENM";
BA_ "SignalLongName" SG_ 1489 CkDyTmRnngLmpsIndOn "Check Daytime Running Lamps Indication On";
BA_ "SignalType" SG_ 1489 CkCrnrLmpsIndOn "ENM";
BA_ "SignalLongName" SG_ 1489 CkCrnrLmpsIndOn "Check Cornering Lamps Indication On";
BA_ "SignalType" SG_ 1489 CkBrkLmpsIndOn "ENM";
BA_ "SignalLongName" SG_ 1489 CkBrkLmpsIndOn "Check Brake Lamps Indication On";
BA_ "SignalType" SG_ 1489 DrMtzdStBltUnIndOn "ENM";
BA_ "SignalLongName" SG_ 1489 DrMtzdStBltUnIndOn "Driver Motorized Seat Belt Unavailable Indication On";
BA_ "SignalType" SG_ 1489 DrMtzdStBltFldIndOn "ENM";
BA_ "SignalLongName" SG_ 1489 DrMtzdStBltFldIndOn "Driver Motorized Seat Belt Failed Indication On";
BA_ "SignalType" SG_ 1489 DispSmrtTowVidOn "ENM";
BA_ "SignalLongName" SG_ 1489 DispSmrtTowVidOn "Display Smart Tow Video On";
BA_ "SignalType" SG_ 1489 Deg360VidFtrPrsnt "ENM";
BA_ "SignalLongName" SG_ 1489 Deg360VidFtrPrsnt "Degree 360 Video Feature Present";
BA_ "SignalType" SG_ 1489 DRLAct "ENM";
BA_ "SignalLongName" SG_ 1489 DRLAct "DRL Active";
BA_ "SignalType" SG_ 1489 CrgBedVwAutoLgtCstSetAval "ENM";
BA_ "SignalLongName" SG_ 1489 CrgBedVwAutoLgtCstSetAval "Cargo Bed View Auto Lighting Customization Setting Available";
BA_ "SignalType" SG_ 1489 CnvtblTopTneuAjrStat "ENM";
BA_ "SignalLongName" SG_ 1489 CnvtblTopTneuAjrStat "Convertible Top Tonneau Ajar Status";
BA_ "SignalType" SG_ 1489 ClsTrnkLidIO "ENM";
BA_ "SignalLongName" SG_ 1489 ClsTrnkLidIO "Close Trunk Lid Indication On";
BA_ "SignalType" SG_ 1489 FrntPsStbltRmIndOn "ENM";
BA_ "SignalLongName" SG_ 1489 FrntPsStbltRmIndOn "Front Passenger Seat Belt Reminder Indication On";
BA_ "SignalType" SG_ 1489 FrntPsMtzdStBltUnIndOn "ENM";
BA_ "SignalLongName" SG_ 1489 FrntPsMtzdStBltUnIndOn "Front Passenger Motorized Seat Belt Unavailable Indication On";
BA_ "SignalType" SG_ 1489 FrntPsMtzdStBltFldIndOn "ENM";
BA_ "SignalLongName" SG_ 1489 FrntPsMtzdStBltFldIndOn "Front Passenger Motorized Seat Belt Failed Indication On";
BA_ "SignalType" SG_ 1489 EsyExtCstStAvl "ENM";
BA_ "SignalLongName" SG_ 1489 EsyExtCstStAvl "EasyExitCustomizationSettingAvailable";
BA_ "SignalType" SG_ 1489 ESCLTrntheStrWheelWhlStrtgIO "ENM";
BA_ "SignalLongName" SG_ 1489 ESCLTrntheStrWheelWhlStrtgIO "Electric Steering Column Lock Turn the Steering Wheel While Starting Indication On";
BA_ "SignalType" SG_ 1489 DsplyTrgVdOn "ENM";
BA_ "SignalLongName" SG_ 1489 DsplyTrgVdOn "Display Triggered Video On";
BA_ "SignalType" SG_ 1489 DspFrnt360CmrON "ENM";
BA_ "SignalLongName" SG_ 1489 DspFrnt360CmrON "Display Front 360 Camera ON";
BA_ "SignalType" SG_ 1489 DrvStBltRmIndOn "ENM";
BA_ "SignalLongName" SG_ 1489 DrvStBltRmIndOn "Driver Seat Belt Reminder Indication On";
BA_ "SignalType" SG_ 1490 JckKnfDtnCstSetAval "ENM";
BA_ "SignalLongName" SG_ 1490 JckKnfDtnCstSetAval "Jack Knife Detection Customization Setting Available";
BA_ "SignalType" SG_ 1490 HiBmOtgIndOn "ENM";
BA_ "SignalLongName" SG_ 1490 HiBmOtgIndOn "High Beam Outage Indication On";
BA_ "SignalType" SG_ 1490 HSP_HptcStPrsntAuth "ENM";
BA_ "SignalLongName" SG_ 1490 HSP_HptcStPrsntAuth "Haptic Seat Protected : Haptic Seat Present Authenticated";
BA_ "SignalType" SG_ 1490 GrdBrkgAct "ENM";
BA_ "SignalLongName" SG_ 1490 GrdBrkgAct "Grade Braking Active";
BA_ "SignalType" SG_ 1490 GoNotfrCstStAvl "ENM";
BA_ "SignalLongName" SG_ 1490 GoNotfrCstStAvl "Go Notifier Customization Setting Available";
BA_ "SignalType" SG_ 1490 FrwdVhHdwyAlrtIndOn "ENM";
BA_ "SignalLongName" SG_ 1490 FrwdVhHdwyAlrtIndOn "Forward Vehicle Headway Alert Indication On";
BA_ "SignalType" SG_ 1490 FrtStrgeCmptAjr "ENM";
BA_ "SignalLongName" SG_ 1490 FrtStrgeCmptAjr "Front Storage Compartment Ajar";
BA_ "SignalType" SG_ 1490 FrtRdHgtGPSCstSetAval "ENM";
BA_ "SignalLongName" SG_ 1490 FrtRdHgtGPSCstSetAval "Front Ride Height GPS Customization Setting Available";
BA_ "SignalType" SG_ 1490 LvlgSysEntEgrsMdCstSetAval "ENM";
BA_ "SignalLongName" SG_ 1490 LvlgSysEntEgrsMdCstSetAval "Leveling System Entry Egress Mode Customization Setting Available";
BA_ "SignalType" SG_ 1490 LvlgSysAlgnMdCstSetSelable "ENM";
BA_ "SignalLongName" SG_ 1490 LvlgSysAlgnMdCstSetSelable "Leveling System Alignment Mode Customization Setting Selectable";
BA_ "SignalType" SG_ 1490 LvlgSysAlgnMdCstSetAval "ENM";
BA_ "SignalLongName" SG_ 1490 LvlgSysAlgnMdCstSetAval "Leveling System Alignment Mode Customization Setting Available";
BA_ "SignalType" SG_ 1490 LtRtHnTrCstStAvl "ENM";
BA_ "SignalLongName" SG_ 1490 LtRtHnTrCstStAvl "Left Right Hand Traffic Customization Setting Available";
BA_ "SignalType" SG_ 1490 LnCntrMisuseCond "ENM";
BA_ "SignalLongName" SG_ 1490 LnCntrMisuseCond "Lane Centering Misuse Condition";
BA_ "SignalType" SG_ 1490 LnCntrDrvAwrIndOn "ENM";
BA_ "SignalLongName" SG_ 1490 LnCntrDrvAwrIndOn "Lane Centering Driver Awareness Indication On";
BA_ "SignalType" SG_ 1490 LicLpOtIO "ENM";
BA_ "SignalLongName" SG_ 1490 LicLpOtIO "License Lamp Outage Indication On";
BA_ "SignalType" SG_ 1490 LSCMBAutoBrkRlsIndOn "ENM";
BA_ "SignalLongName" SG_ 1490 LSCMBAutoBrkRlsIndOn "LSCMB Autonomous Brake Release Indication On";
BA_ "SignalType" SG_ 1490 PrkAsstTrHtchPsntCstStAvl "ENM";
BA_ "SignalLongName" SG_ 1490 PrkAsstTrHtchPsntCstStAvl "Park Assist Trailer Hitch Present Customization Setting Available";
BA_ "SignalType" SG_ 1490 PrkAsstONOFFCstStAvl "ENM";
BA_ "SignalLongName" SG_ 1490 PrkAsstONOFFCstStAvl "Park Assist On Off Customization Setting Available";
BA_ "SignalType" SG_ 1490 PedtrnProtSysDpl "ENM";
BA_ "SignalLongName" SG_ 1490 PedtrnProtSysDpl "Pedestrian Protection System Deployed";
BA_ "SignalType" SG_ 1490 NoSDCrdPrIndOn "ENM";
BA_ "SignalLongName" SG_ 1490 NoSDCrdPrIndOn "No SD Card Present Indication On";
BA_ "SignalType" SG_ 1490 MovblTpServRqrdIO "ENM";
BA_ "SignalLongName" SG_ 1490 MovblTpServRqrdIO "Moveable Top Service Required Indication On";
BA_ "SignalType" SG_ 1490 MovblTpNormzRqrdIO "ENM";
BA_ "SignalLongName" SG_ 1490 MovblTpNormzRqrdIO "Moveable Top Normalization Required Indication On";
BA_ "SignalType" SG_ 1490 LvlgSysServMdCstSetSelable "ENM";
BA_ "SignalLongName" SG_ 1490 LvlgSysServMdCstSetSelable "Leveling System Service Mode Customization Setting Selectable";
BA_ "SignalType" SG_ 1490 LvlgSysServMdCstSetAval "ENM";
BA_ "SignalLongName" SG_ 1490 LvlgSysServMdCstSetAval "Leveling System Service Mode Customization Setting Available";
BA_ "SignalType" SG_ 1490 RnngBrdAutoDplyCstSetAval "ENM";
BA_ "SignalLongName" SG_ 1490 RnngBrdAutoDplyCstSetAval "Running Boards Automatic Deployment Customization Setting Available";
BA_ "SignalType" SG_ 1490 RegVltgCtlEngyRcvryActv "ENM";
BA_ "SignalLongName" SG_ 1490 RegVltgCtlEngyRcvryActv "Regulated Voltage Control Energy Recovery Active";
BA_ "SignalType" SG_ 1490 RearPsStbltVisIndMd "ENM";
BA_ "SignalLongName" SG_ 1490 RearPsStbltVisIndMd "Rear Passenger Seatbelt Reminder Visual Indication Mode";
BA_ "SignalType" SG_ 1490 RIMUnIndOn "ENM";
BA_ "SignalLongName" SG_ 1490 RIMUnIndOn "Rearward Impact Mitigation Unavailable Indication On";
BA_ "SignalType" SG_ 1490 RIMONIndOn "ENM";
BA_ "SignalLongName" SG_ 1490 RIMONIndOn "Rearward Impact Mitigation ON Indication On";
BA_ "SignalType" SG_ 1490 RIMOFFIndOn "ENM";
BA_ "SignalLongName" SG_ 1490 RIMOFFIndOn "Rearward Impact Mitigation OFF Indication On";
BA_ "SignalType" SG_ 1490 PrsnlMdStrCstmSetAv "ENM";
BA_ "SignalLongName" SG_ 1490 PrsnlMdStrCstmSetAv "Personal Mode Steering Customization Setting Available";
BA_ "SignalType" SG_ 1490 PrkBrkSwAtv "ENM";
BA_ "SignalLongName" SG_ 1490 PrkBrkSwAtv "Park Brake Switch Active";
BA_ "SignalType" SG_ 1490 RvLpOtIO "ENM";
BA_ "SignalLongName" SG_ 1490 RvLpOtIO "Reverse Lamp Outage Indication On";
BA_ "SignalType" SG_ 1490 RstrntDplyIndOn "ENM";
BA_ "SignalLongName" SG_ 1490 RstrntDplyIndOn "Restraint Deployment Indication On";
BA_ "SignalType" SG_ 1490 RrVwPrkAstSymCsStAvl "ENM";
BA_ "SignalLongName" SG_ 1490 RrVwPrkAstSymCsStAvl "Rear View Park Assist Symbol Customization Setting Available";
BA_ "SignalType" SG_ 1490 RrFgLpOtIO "ENM";
BA_ "SignalLongName" SG_ 1490 RrFgLpOtIO "Rear Fog Lamp Outage Indication On";
BA_ "SignalType" SG_ 1490 RrAxlTmpInhIO "ENM";
BA_ "SignalLongName" SG_ 1490 RrAxlTmpInhIO "Rear Axle Temporary Inhibit Indication On";
BA_ "SignalType" SG_ 1490 RrAxlMlfIO "ENM";
BA_ "SignalLongName" SG_ 1490 RrAxlMlfIO "Rear Axle Malfunction Indication On";
BA_ "SignalType" SG_ 1490 RnngBrdManDplyCstSetSelbl "ENM";
BA_ "SignalLongName" SG_ 1490 RnngBrdManDplyCstSetSelbl "Running Boards Manual Deployment Customization Setting Selectable";
BA_ "SignalType" SG_ 1490 RnngBrdManDplyCstSetAval "ENM";
BA_ "SignalLongName" SG_ 1490 RnngBrdManDplyCstSetAval "Running Boards Manual Deployment Customization Setting Available";
BA_ "SignalType" SG_ 1490 SftTpMchnOvhtIO "ENM";
BA_ "SignalLongName" SG_ 1490 SftTpMchnOvhtIO "Soft Top Mechanism Overheated Indication On";
BA_ "SignalType" SG_ 1490 SftTpLtcIO "ENM";
BA_ "SignalLongName" SG_ 1490 SftTpLtcIO "Soft Top Latch Indication On";
BA_ "SignalType" SG_ 1490 ServPedtrnFrndlyAlrtIndOn "ENM";
BA_ "SignalLongName" SG_ 1490 ServPedtrnFrndlyAlrtIndOn "Service Pedestrian Friendly Alert Indication On";
BA_ "SignalType" SG_ 1490 SerRideSysIO "ENM";
BA_ "SignalLongName" SG_ 1490 SerRideSysIO "Service Ride System Indication On";
BA_ "SignalType" SG_ 1490 SDCrdFllIndOn "ENM";
BA_ "SignalLongName" SG_ 1490 SDCrdFllIndOn "SD Card Full Indication On";
BA_ "SignalType" SG_ 1490 SDCrdErrIndOn "ENM";
BA_ "SignalLongName" SG_ 1490 SDCrdErrIndOn "SD Card Error Indication On";
BA_ "SignalType" SG_ 1490 TrlrMirVidEnblCstSetAval "ENM";
BA_ "SignalLongName" SG_ 1490 TrlrMirVidEnblCstSetAval "Trailering Mirror Video Enable Customization Setting Available";
BA_ "SignalType" SG_ 1490 TrlrBrkDtd "ENM";
BA_ "SignalLongName" SG_ 1490 TrlrBrkDtd "Trailer Brakes Detected";
BA_ "SignalType" SG_ 1490 TrgrdVidRcrdrFtrPrsnt "ENM";
BA_ "SignalLongName" SG_ 1490 TrgrdVidRcrdrFtrPrsnt "Triggered Video Recorder Feature Present";
BA_ "SignalType" SG_ 1490 TnDrvStBltShfIntlkCstSetAval "ENM";
BA_ "SignalLongName" SG_ 1490 TnDrvStBltShfIntlkCstSetAval "Teen Driver Seat Belt Shift Interlock Customization Setting Available";
BA_ "SignalType" SG_ 1490 TargaTopAjrStat "ENM";
BA_ "SignalLongName" SG_ 1490 TargaTopAjrStat "Targa Top Ajar Status";
BA_ "SignalType" SG_ 1490 StBltTghtngCstStAv "ENM";
BA_ "SignalLongName" SG_ 1490 StBltTghtngCstStAv "Seat Belt Tightening Customization Setting Available";
BA_ "SignalType" SG_ 1490 StBltShfIntlkCstSetAval "ENM";
BA_ "SignalLongName" SG_ 1490 StBltShfIntlkCstSetAval "Seat Belt Shift Interlock Customization Setting Available";
BA_ "SignalType" SG_ 1490 SrrndVwLghtCsStAvl "ENM";
BA_ "SignalLongName" SG_ 1490 SrrndVwLghtCsStAvl "Surround View Lighting Customization Setting Available";
BA_ "SignalType" SG_ 1490 FrtStrgeCmptAjr_Inv "ENM";
BA_ "SignalLongName" SG_ 1490 FrtStrgeCmptAjr_Inv "Front Storage Compartment Ajar Invalid";
BA_ "SignalType" SG_ 1490 WprFrActFltdStat "ENM";
BA_ "SignalLongName" SG_ 1490 WprFrActFltdStat "Wiper Front Active Filtered Status";
BA_ "SignalType" SG_ 1490 TrnSigSwRtActv "ENM";
BA_ "SignalLongName" SG_ 1490 TrnSigSwRtActv "Turn Signal Switch Right Active";
BA_ "SignalType" SG_ 1490 TrnSigSwLtActv "ENM";
BA_ "SignalLongName" SG_ 1490 TrnSigSwLtActv "Turn Signal Switch Left Active";
BA_ "SignalType" SG_ 1490 TrlrMirVidGdlnsCstSetAval "ENM";
BA_ "SignalLongName" SG_ 1490 TrlrMirVidGdlnsCstSetAval "Trailering Mirror Video Guidelines Customization Setting Available";
BA_ "SignalLongName" SG_ 1526 TirePrsLF "Tire Pressure Information : Tire Pressure Left Front";
BA_ "SignalType" SG_ 1526 TireLocatnWarnEn "ENM";
BA_ "SignalLongName" SG_ 1526 TireLocatnWarnEn "Tire Pressure Information : TPMS Tire Location Warnings Enabled";
BA_ "SignalLongName" SG_ 1526 TirePrsLR "Tire Pressure Information : Tire Pressure Left Rear";
BA_ "SignalType" SG_ 1526 TirePrsLF_Inv "ENM";
BA_ "SignalLongName" SG_ 1526 TirePrsLF_Inv "Tire Pressure Information : Tire Pressure Left Front Invalid";
BA_ "SignalLongName" SG_ 1526 TirePrsRF "Tire Pressure Information : Tire Pressure Right Front";
BA_ "SignalType" SG_ 1526 TirePrsLR_Inv "ENM";
BA_ "SignalLongName" SG_ 1526 TirePrsLR_Inv "Tire Pressure Information : Tire Pressure Left Rear Invalid";
BA_ "SignalLongName" SG_ 1526 TirePrsRR "Tire Pressure Information : Tire Pressure Right Rear";
BA_ "SignalType" SG_ 1526 TirePrsRF_Inv "ENM";
BA_ "SignalLongName" SG_ 1526 TirePrsRF_Inv "Tire Pressure Information : Tire Pressure Right Front Invalid";
BA_ "SignalType" SG_ 1526 TirePrsStatLF "ENM";
BA_ "SignalLongName" SG_ 1526 TirePrsStatLF "Tire Pressure Information : TPMS Status (LF)";
BA_ "SignalType" SG_ 1526 TirePrsRR_Inv "ENM";
BA_ "SignalLongName" SG_ 1526 TirePrsRR_Inv "Tire Pressure Information : Tire Pressure Right Rear Invalid";
BA_ "SignalType" SG_ 1526 TirePrsStatRF "ENM";
BA_ "SignalLongName" SG_ 1526 TirePrsStatRF "Tire Pressure Information : TPMS Status (RF)";
BA_ "SignalType" SG_ 1526 TirePrsStatLR_Inv "ENM";
BA_ "SignalLongName" SG_ 1526 TirePrsStatLR_Inv "Tire Pressure Information : TPMS Status (LR) Invalid";
BA_ "SignalType" SG_ 1526 TirePrsStatLR "ENM";
BA_ "SignalLongName" SG_ 1526 TirePrsStatLR "Tire Pressure Information : TPMS Status (LR)";
BA_ "SignalType" SG_ 1526 TirePrsStatLF_Inv "ENM";
BA_ "SignalLongName" SG_ 1526 TirePrsStatLF_Inv "Tire Pressure Information : TPMS Status (LF) Invalid";
BA_ "SignalLongName" SG_ 1526 RrBlwCmd "Rear Blower Command";
BA_ "SignalType" SG_ 1526 TirePrsStatRR_Inv "ENM";
BA_ "SignalLongName" SG_ 1526 TirePrsStatRR_Inv "Tire Pressure Information : TPMS Status (RR) Invalid";
BA_ "SignalType" SG_ 1526 TirePrsStatRR "ENM";
BA_ "SignalLongName" SG_ 1526 TirePrsStatRR "Tire Pressure Information : TPMS Status (RR)";
BA_ "SignalType" SG_ 1526 TirePrsStatRF_Inv "ENM";
BA_ "SignalLongName" SG_ 1526 TirePrsStatRF_Inv "Tire Pressure Information : TPMS Status (RF) Invalid";
BA_ "SignalType" SG_ 1526 ACCDsngIndOn "ENM";
BA_ "SignalLongName" SG_ 1526 ACCDsngIndOn "Adaptive Cruise Control Disengaging Indication On";
BA_ "SignalLongName" SG_ 1527 TCTPIR_EstdClchCoolDnTmpTgtDisp "Transmission Clutch Thermal Protection Indication Request : Estimated Clutch Cool Down Temperature Target Display";
BA_ "SignalType" SG_ 1527 TCTPIR_DrvrNtfn "ENM";
BA_ "SignalLongName" SG_ 1527 TCTPIR_DrvrNtfn "Transmission Clutch Thermal Protection Indication Request : Driver Notification";
BA_ "SignalLongName" SG_ 1527 TCTPIR_EstdClchTmpDisp "Transmission Clutch Thermal Protection Indication Request : Estimated Clutch Temperature Display";
BA_ "SignalType" SG_ 1527 FPARS_Lt "ENM";
BA_ "SignalLongName" SG_ 1527 FPARS_Lt "Front Park Assist Region Status : Left Region";
BA_ "SignalType" SG_ 1527 FPARS_Rt "ENM";
BA_ "SignalLongName" SG_ 1527 FPARS_Rt "Front Park Assist Region Status : Right Region";
BA_ "SignalType" SG_ 1527 FPARS_LtCntr "ENM";
BA_ "SignalLongName" SG_ 1527 FPARS_LtCntr "Front Park Assist Region Status : Left Center Region";
BA_ "SignalLongName" SG_ 1527 VehMassEst "Vehicle Mass Estimate";
BA_ "SignalType" SG_ 1527 FPARS_RtCntr "ENM";
BA_ "SignalLongName" SG_ 1527 FPARS_RtCntr "Front Park Assist Region Status : Right Center Region";
BA_ "SignalLongName" SG_ 1527 RideHghtSpdRstrctnDispVal "Ride Height Information : Ride Height Speed Restriction Display Value";
BA_ "SignalType" SG_ 1527 RdHgtWrn2IndReq "ENM";
BA_ "SignalLongName" SG_ 1527 RdHgtWrn2IndReq "Ride Height Information : Ride Height Warning 2 Indication Request";
BA_ "SignalType" SG_ 1527 ACCHdwySttngIndOn "ENM";
BA_ "SignalLongName" SG_ 1527 ACCHdwySttngIndOn "Adaptive Cruise Control Headway Setting Indication On";
BA_ "SignalLongName" SG_ 1528 EVMESS_StrtPrgs "Electric Vehicle Mode Engine Start Status : Start Progress";
BA_ "SignalType" SG_ 1528 EVMESS_StrtPhs "ENM";
BA_ "SignalLongName" SG_ 1528 EVMESS_StrtPhs "Electric Vehicle Mode Engine Start Status : Start Phase";
BA_ "SignalLongName" SG_ 1528 EngIntAirTmp "Serial Data 119 : Engine Intake Air Temperature";
BA_ "SignalType" SG_ 1528 EngIntAirTmp_Inv "ENM";
BA_ "SignalLongName" SG_ 1528 EngIntAirTmp_Inv "Serial Data 119 : Engine Intake Air Temperature Invalid";
BA_ "SignalLongName" SG_ 1528 CCCGI_FrtBlwFanSpdFdbkRtlzd "Serial Data 8 : Climate Control Cabin Front Blower Fan Speed Feedback Rationalized";
BA_ "SignalLongName" SG_ 1528 LnCntrArrwBlck1Offst "Lane Centering Arrow Block 1 Offset";
BA_ "SignalLongName" SG_ 1528 LnCntrArrwBlck2Offst "Lane Centering Arrow Block 2 Offset";
BA_ "SignalLongName" SG_ 1528 FllwgTmIndVal "Following Time Indicator Value";
BA_ "SignalLongName" SG_ 1528 WEPRP_WhlEdgesPerRevFrtAuth "Serial Data 17 Protected : Wheel Edges Per Revolution Front Authenticated";
BA_ "SignalLongName" SG_ 1528 WEPRP_WhlEdgesPerRevRrAuth "Serial Data 17 Protected : Wheel Edges Per Revolution Rear Authenticated";
BA_ "SignalLongName" SG_ 1529 FPCMHSR_HptcStReqPuls "Front Pedestrian Collision Mitigation Haptic Seat Request : Haptic Seat Request Pulses";
BA_ "SignalType" SG_ 1529 FrwdHdwyVisIndCtl "ENM";
BA_ "SignalLongName" SG_ 1529 FrwdHdwyVisIndCtl "Adaptive Cruise Control Information 2 : Forward Headway Visual Indicator Control";
BA_ "SignalType" SG_ 1529 FCA_ACCGapSetIndOn "ENM";
BA_ "SignalLongName" SG_ 1529 FCA_ACCGapSetIndOn "Adaptive Cruise Control Information 2 : Forward Collision Alert Adaptive Cruise Control Gap Setting Indication On";
BA_ "SignalType" SG_ 1529 FCAACCGapSeltn "ENM";
BA_ "SignalLongName" SG_ 1529 FCAACCGapSeltn "Adaptive Cruise Control Information 2 : Forward Collision Alert - Adaptive Cruise Control Gap Selection";
BA_ "SignalType" SG_ 1529 ACCTrlrGapSetIndOn "ENM";
BA_ "SignalLongName" SG_ 1529 ACCTrlrGapSetIndOn "Adaptive Cruise Control Information 2 : Adaptive Cruise Control Trailer Gap Setting Indication On";
BA_ "SignalLongName" SG_ 1529 LDWCLHSHSR_HptcStReqPuls "Lane Detection Warning and Control Left Hand Side Haptic Seat Request : Haptic Seat Request Pulses";
BA_ "SignalLongName" SG_ 1529 LDWCRHSHSR_HptcStReqPuls "Lane Detection Warning and Control Right Hand Side Haptic Seat Request : Haptic Seat Request Pulses";
BA_ "SignalLongName" SG_ 1529 RCTALSHSR_HptcStReqPuls "Rear Cross Traffic Alert Left Side Haptic Seat Request : Haptic Seat Request Pulses";
BA_ "SignalLongName" SG_ 1529 RCMHSR_HptcStReqPuls "Rear Collision Mitigation Haptic Seat Request : Haptic Seat Request Pulses";
BA_ "SignalLongName" SG_ 1529 RCTARSHSR_HptcStReqPuls "Rear Cross Traffic Alert Right Side Haptic Seat Request : Rear Cross Traffic Alert Right Side Haptic Seat Request Pulses";
BA_ "SignalType" SG_ 1529 LnCntrCnvMsgIndRqst "ENM";
BA_ "SignalLongName" SG_ 1529 LnCntrCnvMsgIndRqst "Lane Centering Convenience Message Indication Request";
BA_ "SignalType" SG_ 1529 FllwgTmDsplyMd "ENM";
BA_ "SignalLongName" SG_ 1529 FllwgTmDsplyMd "Following Time Display Mode";
BA_ "SignalType" SG_ 1529 VCTLS_UsrCtlAllwd "ENM";
BA_ "SignalLongName" SG_ 1529 VCTLS_UsrCtlAllwd "Virtual Control Task Lamp Status : User Control Allowed";
BA_ "SignalType" SG_ 1529 VCTLS_CurrSeltnVal "ENM";
BA_ "SignalLongName" SG_ 1529 VCTLS_CurrSeltnVal "Virtual Control Task Lamp Status : Current Selection Value";
BA_ "SignalType" SG_ 1529 VCTLS_CtlAval "ENM";
BA_ "SignalLongName" SG_ 1529 VCTLS_CtlAval "Virtual Control Task Lamp Status : Control Available";
BA_ "SignalType" SG_ 1530 AirbgStsIndReq "ENM";
BA_ "SignalLongName" SG_ 1530 AirbgStsIndReq "Airbag Status Indication Request";
BA_ "SignalType" SG_ 1530 AdpAndCnvntlCruzCtlIndReq "ENM";
BA_ "SignalLongName" SG_ 1530 AdpAndCnvntlCruzCtlIndReq "Adaptive and Conventional Cruise Control Indication Request";
BA_ "SignalType" SG_ 1530 DrvStBltRmIndReq "ENM";
BA_ "SignalLongName" SG_ 1530 DrvStBltRmIndReq "Driver Seat Belt Reminder Indication Request";
BA_ "SignalType" SG_ 1530 BSSIP_BrkAsstBrkBstStsAuth "ENM";
BA_ "SignalLongName" SG_ 1530 BSSIP_BrkAsstBrkBstStsAuth "Serial Data 17 Protected : Brake Assist Brake Boost Status Authenticated";
BA_ "SignalType" SG_ 1530 SGI2P_AirSpnsnRdHghtActlStsAuth "ENM";
BA_ "SignalLongName" SG_ 1530 SGI2P_AirSpnsnRdHghtActlStsAuth "Suspension General Information 2 Protected : Air Suspension Ride Height Actual Status Authenticated";
BA_ "SignalType" SG_ 1530 RdHgtStatIndReq "ENM";
BA_ "SignalLongName" SG_ 1530 RdHgtStatIndReq "Ride Height State Indication Request";
BA_ "SignalType" SG_ 1530 AutoLnChgCstCurrSetVal "ENM";
BA_ "SignalLongName" SG_ 1530 AutoLnChgCstCurrSetVal "Automatic Lane Change Customization Current Setting Value";
BA_ "SignalType" SG_ 1530 ArtcldRnngBrdSt "ENM";
BA_ "SignalLongName" SG_ 1530 ArtcldRnngBrdSt "Articulated Running Board State";
BA_ "SignalType" SG_ 1530 LAOA_LatAsstOffOptAval "ENM";
BA_ "SignalLongName" SG_ 1530 LAOA_LatAsstOffOptAval "Lateral Assist Options Available : Off";
BA_ "SignalType" SG_ 1530 LAOA_LatAsstLKAOptAval "ENM";
BA_ "SignalLongName" SG_ 1530 LAOA_LatAsstLKAOptAval "Lateral Assist Options Available : LKA";
BA_ "SignalType" SG_ 1530 LAOA_LatAsstLDWOptAval "ENM";
BA_ "SignalLongName" SG_ 1530 LAOA_LatAsstLDWOptAval "Lateral Assist Options Available : LDW";
BA_ "SignalType" SG_ 1530 LAOA_LatAsstHoLFOptAval "ENM";
BA_ "SignalLongName" SG_ 1530 LAOA_LatAsstHoLFOptAval "Lateral Assist Options Available : HoLF";
BA_ "SignalType" SG_ 1530 AxlLckUnavailIndReq "ENM";
BA_ "SignalLongName" SG_ 1530 AxlLckUnavailIndReq "Axle Locks Unavailable Indication Request";
BA_ "SignalType" SG_ 1530 AutoTrnspHdActvnCstCurrSetVal "ENM";
BA_ "SignalLongName" SG_ 1530 AutoTrnspHdActvnCstCurrSetVal "Automatic Transparent Hood Activation Customization Current Setting Value";
BA_ "SignalType" SG_ 1530 DslExhFldDiagWrnIdRq "ENM";
BA_ "SignalLongName" SG_ 1530 DslExhFldDiagWrnIdRq "Diesel Exhaust Fluid System Diagnostic Warning Indication Request";
BA_ "SignalType" SG_ 1530 DrvrSeltdSpdLmtrIndReq "ENM";
BA_ "SignalLongName" SG_ 1530 DrvrSeltdSpdLmtrIndReq "Driver Selected Speed Limiter Indication Request";
BA_ "SignalType" SG_ 1530 BSSIP_LnchCtlModeStsAuth "ENM";
BA_ "SignalLongName" SG_ 1530 BSSIP_LnchCtlModeStsAuth "Serial Data 17 Protected : Launch Control Mode Status Authenticated";
BA_ "SignalType" SG_ 1530 FPLTLI_AuxPrkLmpLtCmd "ENM";
BA_ "SignalLongName" SG_ 1530 FPLTLI_AuxPrkLmpLtCmd "Front Park Lamps and Tail Lamps Information : Aux Park Lamp Left Command";
BA_ "SignalType" SG_ 1530 FCAGpSet "ENM";
BA_ "SignalLongName" SG_ 1530 FCAGpSet "Forward Collision Alert Gap Setting";
BA_ "SignalType" SG_ 1530 FPLTLI_PrkLmpLtCmd "ENM";
BA_ "SignalLongName" SG_ 1530 FPLTLI_PrkLmpLtCmd "Front Park Lamps and Tail Lamps Information : Park Lamp Left Command";
BA_ "SignalType" SG_ 1530 FPLTLI_AuxPrkLmpRtCmd "ENM";
BA_ "SignalLongName" SG_ 1530 FPLTLI_AuxPrkLmpRtCmd "Front Park Lamps and Tail Lamps Information : Aux Park Lamp Right Command";
BA_ "SignalType" SG_ 1531 LtAstStsIndRq "ENM";
BA_ "SignalLongName" SG_ 1531 LtAstStsIndRq "Lateral Assist Status Indication Request";
BA_ "SignalType" SG_ 1531 HybStatShtlModeOvrrd "ENM";
BA_ "SignalLongName" SG_ 1531 HybStatShtlModeOvrrd "Hybrid State Shuttle Mode Override";
BA_ "SignalType" SG_ 1531 FPLTLI_PrkLmpRtCmd "ENM";
BA_ "SignalLongName" SG_ 1531 FPLTLI_PrkLmpRtCmd "Front Park Lamps and Tail Lamps Information : Park Lamp Right Command";
BA_ "SignalType" SG_ 1531 MemStorCmpltdIndReq "ENM";
BA_ "SignalLongName" SG_ 1531 MemStorCmpltdIndReq "Memory Store Completed Indication Request";
BA_ "SignalType" SG_ 1531 MemRclHldUntilCmpltIndReq "ENM";
BA_ "SignalLongName" SG_ 1531 MemRclHldUntilCmpltIndReq "Memory Recall Hold Until Complete Indication Request";
BA_ "SignalType" SG_ 1531 MemRclCmpltIndReq "ENM";
BA_ "SignalLongName" SG_ 1531 MemRclCmpltIndReq "Memory Recall Complete Indication Request";
BA_ "SignalType" SG_ 1531 NtVsnVidCntrstSts "ENM";
BA_ "SignalLongName" SG_ 1531 NtVsnVidCntrstSts "Night Vision Video Contrast Status";
BA_ "SignalType" SG_ 1531 NtVsnVidBrghtnsSts "ENM";
BA_ "SignalLongName" SG_ 1531 NtVsnVidBrghtnsSts "Night Vision Video Brightness Status";
BA_ "SignalType" SG_ 1531 RdHgtAtLocIndReq "ENM";
BA_ "SignalLongName" SG_ 1531 RdHgtAtLocIndReq "Ride Height Auto Location Indication Request";
BA_ "SignalType" SG_ 1531 RdHgtActvnIndReq "ENM";
BA_ "SignalLongName" SG_ 1531 RdHgtActvnIndReq "Ride Height Activation Indication Request";
BA_ "SignalType" SG_ 1531 PARgn "ENM";
BA_ "SignalLongName" SG_ 1531 PARgn "Park Assist Region";
BA_ "SignalType" SG_ 1531 SecAxlTransStatAchvd_Inv "ENM";
BA_ "SignalLongName" SG_ 1531 SecAxlTransStatAchvd_Inv "Secondary Axle Transmission State Achieved Invalid";
BA_ "SignalType" SG_ 1531 RdHgtWrn1IndReq "ENM";
BA_ "SignalLongName" SG_ 1531 RdHgtWrn1IndReq "Ride Height Warning 1 Indication Request";
BA_ "SignalType" SG_ 1531 RdHgtMvmtIndReq "ENM";
BA_ "SignalLongName" SG_ 1531 RdHgtMvmtIndReq "Ride Height Movement Indication Request";
BA_ "SignalType" SG_ 1531 TrnsSftMdSt "ENM";
BA_ "SignalLongName" SG_ 1531 TrnsSftMdSt "Transmission Shift Mode State";
BA_ "SignalType" SG_ 1531 TrlrMirVidEnblCstCurrSetVal "ENM";
BA_ "SignalLongName" SG_ 1531 TrlrMirVidEnblCstCurrSetVal "Trailering Mirror Video Enable CustomizationCurrent Setting Value";
BA_ "SignalType" SG_ 1531 SecAxlTransStatAchvd "ENM";
BA_ "SignalLongName" SG_ 1531 SecAxlTransStatAchvd "Secondary Axle Transmission State Achieved";
BA_ "SignalType" SG_ 1531 WndPstnStsLR "ENM";
BA_ "SignalLongName" SG_ 1531 WndPstnStsLR "Window Position Status Left Rear";
BA_ "SignalType" SG_ 1531 WndPstnStsLF "ENM";
BA_ "SignalLongName" SG_ 1531 WndPstnStsLF "Window Position Status Left Front";
BA_ "SignalType" SG_ 1531 VhSpdCntlSystmTyp "ENM";
BA_ "SignalLongName" SG_ 1531 VhSpdCntlSystmTyp "Vehicle Speed Control System Type";
BA_ "SignalType" SG_ 1531 ACCRtSpdAdVsIndOn "ENM";
BA_ "SignalLongName" SG_ 1531 ACCRtSpdAdVsIndOn "Adaptive Cruise Control Route Speed Adaptation Visual Indication On";
BA_ "SignalType" SG_ 1531 WndPstnStsRR "ENM";
BA_ "SignalLongName" SG_ 1531 WndPstnStsRR "Window Position Status Right Rear";
BA_ "SignalType" SG_ 1531 WndPstnStsRF "ENM";
BA_ "SignalLongName" SG_ 1531 WndPstnStsRF "Window Position Status Right Front";
BA_ "SignalType" SG_ 1532 WthrSnwModeDrvlineVisDispVal "ENM";
BA_ "SignalLongName" SG_ 1532 WthrSnwModeDrvlineVisDispVal "Weather Snow Mode Driveline Visualization Display Value";
BA_ "SignalType" SG_ 1532 WthrSnwModeBrkPedVisDispVal "ENM";
BA_ "SignalLongName" SG_ 1532 WthrSnwModeBrkPedVisDispVal "Weather Snow Mode Brake Pedal Visualization Display Value";
BA_ "SignalType" SG_ 1532 WthrSnwModeActvAeroVisDispVal "ENM";
BA_ "SignalLongName" SG_ 1532 WthrSnwModeActvAeroVisDispVal "Weather Snow Mode Active Aerodynamics Visualization Display Value";
BA_ "SignalType" SG_ 1532 WthrSnwModeRideHghtVisDispVal "ENM";
BA_ "SignalLongName" SG_ 1532 WthrSnwModeRideHghtVisDispVal "Weather Snow Mode Ride Height Visualization Display Value";
BA_ "SignalType" SG_ 1532 WthrSnwModePwrtrnVisDispVal "ENM";
BA_ "SignalLongName" SG_ 1532 WthrSnwModePwrtrnVisDispVal "Weather Snow Mode Powertrain Visualization Display Value";
BA_ "SignalType" SG_ 1532 WthrSnwModeESCVisDispVal "ENM";
BA_ "SignalLongName" SG_ 1532 WthrSnwModeESCVisDispVal "Weather Snow Mode ESC Visualization Display Value";
BA_ "SignalType" SG_ 1532 WthrSnwModeSpnsnVisDispVal "ENM";
BA_ "SignalLongName" SG_ 1532 WthrSnwModeSpnsnVisDispVal "Weather Snow Mode Suspension Visualization Display Value";
BA_ "SignalType" SG_ 1532 WthrSnwModeSndVisDispVal "ENM";
BA_ "SignalLongName" SG_ 1532 WthrSnwModeSndVisDispVal "Weather Snow Mode Sound Visualization Display Value";
BA_ "SignalType" SG_ 1532 CmdSndRwCtStbtVisInd "ENM";
BA_ "SignalLongName" SG_ 1532 CmdSndRwCtStbtVisInd "Command Rear Passenger Second Row Center Seat Belt Visual Indication";
BA_ "SignalType" SG_ 1532 CltTpTrvAchv "ENM";
BA_ "SignalLongName" SG_ 1532 CltTpTrvAchv "Clutch Top of Travel Achieved";
BA_ "SignalType" SG_ 1532 CltTpTrvAchv_Inv "ENM";
BA_ "SignalLongName" SG_ 1532 CltTpTrvAchv_Inv "Clutch Top of Travel Achieved Invalid";
BA_ "SignalType" SG_ 1532 AdvdFrtLgtSysIndReq "ENM";
BA_ "SignalLongName" SG_ 1532 AdvdFrtLgtSysIndReq "Advanced Front Lighting System Indication Request";
BA_ "SignalType" SG_ 1532 ACCHdwySttng "ENM";
BA_ "SignalLongName" SG_ 1532 ACCHdwySttng "Adaptive Cruise Control Headway Setting";
BA_ "SignalType" SG_ 1532 CmdThrdRwLtStbtVisInd "ENM";
BA_ "SignalLongName" SG_ 1532 CmdThrdRwLtStbtVisInd "Command Rear Passenger Thrd Row Left Seat Belt Visual Indication";
BA_ "SignalType" SG_ 1532 CmdThrdRwCtStbtVisInd "ENM";
BA_ "SignalLongName" SG_ 1532 CmdThrdRwCtStbtVisInd "Command Rear Passenger Third Row Center Seat Belt Visual Indication";
BA_ "SignalType" SG_ 1532 CmdSndRwRtStbtVisInd "ENM";
BA_ "SignalLongName" SG_ 1532 CmdSndRwRtStbtVisInd "Command Rear Passenger Second Row Right Seat Belt Visual Indication";
BA_ "SignalType" SG_ 1532 CmdSndRwLtStbtVisInd "ENM";
BA_ "SignalLongName" SG_ 1532 CmdSndRwLtStbtVisInd "Command Rear Passenger Second Row Left Seat Belt Visual Indication";
BA_ "SignalType" SG_ 1532 ElecShftrLckdHldBrkToOvrrdIndOn "ENM";
BA_ "SignalLongName" SG_ 1532 ElecShftrLckdHldBrkToOvrrdIndOn "Electronic Shifter Locked Hold Brake To Override Indication On";
BA_ "SignalType" SG_ 1532 CmdThrdRwRtStbtVisInd "ENM";
BA_ "SignalLongName" SG_ 1532 CmdThrdRwRtStbtVisInd "Command Rear Passenger Third Row Right Seat Belt Visual Indication";
BA_ "SignalType" SG_ 1532 ElecAxlUnvIndReq "ENM";
BA_ "SignalLongName" SG_ 1532 ElecAxlUnvIndReq "Electric Axle Unavailable Indication Request";
BA_ "SignalType" SG_ 1532 ElecAxlBstGageIndReq "ENM";
BA_ "SignalLongName" SG_ 1532 ElecAxlBstGageIndReq "Electric Axle Boost Gage Indication Request";
BA_ "SignalType" SG_ 1532 DslEmnsOBDMrkt "ENM";
BA_ "SignalLongName" SG_ 1532 DslEmnsOBDMrkt "Diesel Emissions OBD Market";
BA_ "SignalType" SG_ 1532 LnCntrSpchPrmtReq "ENM";
BA_ "SignalLongName" SG_ 1532 LnCntrSpchPrmtReq "Lane Centering Speech Prompt Request";
BA_ "SignalType" SG_ 1532 GlrFrHiBmSts "ENM";
BA_ "SignalLongName" SG_ 1532 GlrFrHiBmSts "Glare Free High Beam Status";
BA_ "SignalType" SG_ 1532 EngCmptHotWrnIndReq "ENM";
BA_ "SignalLongName" SG_ 1532 EngCmptHotWrnIndReq "Engine Compartment Hot Warning Indication Request";
BA_ "SignalType" SG_ 1532 ElecShftPrTwoGrsSelIndRq "ENM";
BA_ "SignalLongName" SG_ 1532 ElecShftPrTwoGrsSelIndRq "Electronic Shift Primary Two Gears Selected Indication Request";
BA_ "SignalType" SG_ 1533 ROSP_FrntPsRestOcpStatAuth "ENM";
BA_ "SignalLongName" SG_ 1533 ROSP_FrntPsRestOcpStatAuth "Restraint Occupancy Status Protected : Front Passenger Restraint Occupancy Status Authenticated";
BA_ "SignalType" SG_ 1533 PdWrnIndRqst "ENM";
BA_ "SignalLongName" SG_ 1533 PdWrnIndRqst "Pedestrian Warning Indication Request";
BA_ "SignalType" SG_ 1533 PPVehRadioMutReq "ENM";
BA_ "SignalLongName" SG_ 1533 PPVehRadioMutReq "Police Pursuit Vehicle Radio Mute Request";
BA_ "SignalType" SG_ 1533 NtVsnFncSts "ENM";
BA_ "SignalLongName" SG_ 1533 NtVsnFncSts "Night Vision Function Status";
BA_ "SignalType" SG_ 1533 ACCSysSlctdMdDspIndOn "ENM";
BA_ "SignalLongName" SG_ 1533 ACCSysSlctdMdDspIndOn "Adaptive Cruise Control System Selected Mode Display Indication On";
BA_ "SignalType" SG_ 1533 ACCShftToPrkBfrExIndOn "ENM";
BA_ "SignalLongName" SG_ 1533 ACCShftToPrkBfrExIndOn "Adaptive Cruise Control Shift To Park Before Exiting Vehicle Indication On";
BA_ "SignalType" SG_ 1533 WhlSlpSt "ENM";
BA_ "SignalLongName" SG_ 1533 WhlSlpSt "Wheel Slip Status";
BA_ "SignalType" SG_ 1533 VehMassEstSts "ENM";
BA_ "SignalLongName" SG_ 1533 VehMassEstSts "Vehicle Mass Estimate Status";
BA_ "SignalType" SG_ 1533 TrlrArtclnAngCalSts "ENM";
BA_ "SignalLongName" SG_ 1533 TrlrArtclnAngCalSts "Trailer Articulation Angle Calibration Status";
BA_ "SignalType" SG_ 1533 AutoLnChgCstAvlFlg3 "ENM";
BA_ "SignalLongName" SG_ 1533 AutoLnChgCstAvlFlg3 "Automatic Lane Change Customization Availability Flag 3";
BA_ "SignalType" SG_ 1533 AutoLnChgCstAvlFlg2 "ENM";
BA_ "SignalLongName" SG_ 1533 AutoLnChgCstAvlFlg2 "Automatic Lane Change Customization Availability Flag 2";
BA_ "SignalType" SG_ 1533 AutoLnChgCstAvlFlg1 "ENM";
BA_ "SignalLongName" SG_ 1533 AutoLnChgCstAvlFlg1 "Automatic Lane Change Customization Availability Flag 1";
BA_ "SignalType" SG_ 1533 AutoBmSlctAllwd "ENM";
BA_ "SignalLongName" SG_ 1533 AutoBmSlctAllwd "Automatic Beam Select Allowed";
BA_ "SignalType" SG_ 1533 AirCndOffIO "ENM";
BA_ "SignalLongName" SG_ 1533 AirCndOffIO "Air Conditioning Off Indication On";
BA_ "SignalType" SG_ 1533 AdptCrsCntrlEngd "ENM";
BA_ "SignalLongName" SG_ 1533 AdptCrsCntrlEngd "Adaptive Cruise Control Engaged";
BA_ "SignalType" SG_ 1533 ACCompCmnd "ENM";
BA_ "SignalLongName" SG_ 1533 ACCompCmnd "Serial Data 110 : Air Conditioning Compressor Command";
BA_ "SignalType" SG_ 1533 ACCTmpUnvIndOn "ENM";
BA_ "SignalLongName" SG_ 1533 ACCTmpUnvIndOn "Adaptive Cruise Control Temporary Unavailable Indication On";
BA_ "SignalType" SG_ 1533 AutoTrnspHdActvnCstAvlFlg3 "ENM";
BA_ "SignalLongName" SG_ 1533 AutoTrnspHdActvnCstAvlFlg3 "Automatic Transparent Hood Activation Customization Availability Flag3";
BA_ "SignalType" SG_ 1533 AutoTrnspHdActvnCstAvlFlg2 "ENM";
BA_ "SignalLongName" SG_ 1533 AutoTrnspHdActvnCstAvlFlg2 "Automatic Transparent Hood Activation Customization Availability Flag2";
BA_ "SignalType" SG_ 1533 AutoTrnspHdActvnCstAvlFlg1 "ENM";
BA_ "SignalLongName" SG_ 1533 AutoTrnspHdActvnCstAvlFlg1 "Automatic Transparent Hood Activation Customization Availability Flag1";
BA_ "SignalType" SG_ 1533 AutoLnChgCstSetAval "ENM";
BA_ "SignalLongName" SG_ 1533 AutoLnChgCstSetAval "Automatic Lane Change Customization Setting Available";
BA_ "SignalType" SG_ 1533 AutoLnChgCstAvlFlg7 "ENM";
BA_ "SignalLongName" SG_ 1533 AutoLnChgCstAvlFlg7 "Automatic Lane Change Customization Availability Flag 7";
BA_ "SignalType" SG_ 1533 AutoLnChgCstAvlFlg6 "ENM";
BA_ "SignalLongName" SG_ 1533 AutoLnChgCstAvlFlg6 "Automatic Lane Change Customization Availability Flag 6";
BA_ "SignalType" SG_ 1533 AutoLnChgCstAvlFlg5 "ENM";
BA_ "SignalLongName" SG_ 1533 AutoLnChgCstAvlFlg5 "Automatic Lane Change Customization Availability Flag 5";
BA_ "SignalType" SG_ 1533 AutoLnChgCstAvlFlg4 "ENM";
BA_ "SignalLongName" SG_ 1533 AutoLnChgCstAvlFlg4 "Automatic Lane Change Customization Availability Flag 4";
BA_ "SignalType" SG_ 1533 DCCnvStblznErrIndOn "ENM";
BA_ "SignalLongName" SG_ 1533 DCCnvStblznErrIndOn "DCDC Converter Stabilization Error Indication On";
BA_ "SignalType" SG_ 1533 CustmStbCtlRdctReqIndOn "ENM";
BA_ "SignalLongName" SG_ 1533 CustmStbCtlRdctReqIndOn "Custom Stability Control Reduction Request Indication On";
BA_ "SignalType" SG_ 1533 AxlLcksServIO "ENM";
BA_ "SignalLongName" SG_ 1533 AxlLcksServIO "Axle Locks Service Indication On";
BA_ "SignalType" SG_ 1533 AutoTrnspHdActvnCstSetAval "ENM";
BA_ "SignalLongName" SG_ 1533 AutoTrnspHdActvnCstSetAval "Automatic Transparent Hood Activation Customization Setting Available";
BA_ "SignalType" SG_ 1533 AutoTrnspHdActvnCstAvlFlg7 "ENM";
BA_ "SignalLongName" SG_ 1533 AutoTrnspHdActvnCstAvlFlg7 "Automatic Transparent Hood Activation Customization Availability Flag7";
BA_ "SignalType" SG_ 1533 AutoTrnspHdActvnCstAvlFlg6 "ENM";
BA_ "SignalLongName" SG_ 1533 AutoTrnspHdActvnCstAvlFlg6 "Automatic Transparent Hood Activation Customization Availability Flag6";
BA_ "SignalType" SG_ 1533 AutoTrnspHdActvnCstAvlFlg5 "ENM";
BA_ "SignalLongName" SG_ 1533 AutoTrnspHdActvnCstAvlFlg5 "Automatic Transparent Hood Activation Customization Availability Flag5";
BA_ "SignalType" SG_ 1533 AutoTrnspHdActvnCstAvlFlg4 "ENM";
BA_ "SignalLongName" SG_ 1533 AutoTrnspHdActvnCstAvlFlg4 "Automatic Transparent Hood Activation Customization Availability Flag4";
BA_ "SignalType" SG_ 1533 DM8Denied "ENM";
BA_ "SignalLongName" SG_ 1533 DM8Denied "Drive Mode 8 Denied";
BA_ "SignalType" SG_ 1533 DM7Denied "ENM";
BA_ "SignalLongName" SG_ 1533 DM7Denied "Drive Mode 7 Denied";
BA_ "SignalType" SG_ 1533 DM6Denied "ENM";
BA_ "SignalLongName" SG_ 1533 DM6Denied "Drive Mode 6 Denied";
BA_ "SignalType" SG_ 1533 DM5Denied "ENM";
BA_ "SignalLongName" SG_ 1533 DM5Denied "Drive Mode 5 Denied";
BA_ "SignalType" SG_ 1533 DM4Denied "ENM";
BA_ "SignalLongName" SG_ 1533 DM4Denied "Drive Mode 4 Denied";
BA_ "SignalType" SG_ 1533 DM3Denied "ENM";
BA_ "SignalLongName" SG_ 1533 DM3Denied "Drive Mode 3 Denied";
BA_ "SignalType" SG_ 1533 DM2Denied "ENM";
BA_ "SignalLongName" SG_ 1533 DM2Denied "Drive Mode 2 Denied";
BA_ "SignalType" SG_ 1533 DM1Denied "ENM";
BA_ "SignalLongName" SG_ 1533 DM1Denied "Drive Mode 1 Denied";
BA_ "SignalType" SG_ 1533 ElecShfPriTransCtlrMalfIndOn "ENM";
BA_ "SignalLongName" SG_ 1533 ElecShfPriTransCtlrMalfIndOn "Electronic Shift Primary Transmission Controller Malfunction Indication On";
BA_ "SignalType" SG_ 1533 ElecShfPriShfToDrvTryAgnIndOn "ENM";
BA_ "SignalLongName" SG_ 1533 ElecShfPriShfToDrvTryAgnIndOn "Electronic Shift Primary Shift To Drive Try Again Indication On";
BA_ "SignalType" SG_ 1533 ElecShfPriRdcSpdForReqdShfIndOn "ENM";
BA_ "SignalLongName" SG_ 1533 ElecShfPriRdcSpdForReqdShfIndOn "Electronic Shift Primary Reduce Speed For Requested Shift Indication On";
BA_ "SignalType" SG_ 1533 ElecShfLckdBcklPsngrStBltIndOn "ENM";
BA_ "SignalLongName" SG_ 1533 ElecShfLckdBcklPsngrStBltIndOn "Electronic Shift Locked Buckle Passenger Seatbelt Indication On";
BA_ "SignalType" SG_ 1533 ElecShfLckdBcklDrvrStBltIndOn "ENM";
BA_ "SignalLongName" SG_ 1533 ElecShfLckdBcklDrvrStBltIndOn "Electronic Shift Locked Buckle Driver Seatbelt Indication On";
BA_ "SignalType" SG_ 1533 DrSlctdSpdLmtrEnbld "ENM";
BA_ "SignalLongName" SG_ 1533 DrSlctdSpdLmtrEnbld "Driver Selected Speed Limiter Enabled";
BA_ "SignalType" SG_ 1533 DrSlctdSpdLmtrActv "ENM";
BA_ "SignalLongName" SG_ 1533 DrSlctdSpdLmtrActv "Driver Selected Speed Limiter Active";
BA_ "SignalType" SG_ 1533 ElecShftPrDrDoorStIndIO "ENM";
BA_ "SignalLongName" SG_ 1533 ElecShftPrDrDoorStIndIO "ETRS Driver Door State Indeterminate Indication On";
BA_ "SignalType" SG_ 1533 ElecShftPrAtPrkIO "ENM";
BA_ "SignalLongName" SG_ 1533 ElecShftPrAtPrkIO "Electronic Shift Primary Auto Park Indication On";
BA_ "SignalType" SG_ 1533 ElecShfUnlckdBrkToShfIndOn "ENM";
BA_ "SignalLongName" SG_ 1533 ElecShfUnlckdBrkToShfIndOn "Electronic Shift Unlocked Brake To Shift Indication On";
BA_ "SignalType" SG_ 1533 ElecShfPriTrnVehOffForPrkIndOn "ENM";
BA_ "SignalLongName" SG_ 1533 ElecShfPriTrnVehOffForPrkIndOn "Electronic Shift Primary Turn Vehicle Off For Park Indication On";
BA_ "SignalType" SG_ 1276 ElecShftPrTrnMlfIO "ENM";
BA_ "SignalLongName" SG_ 1276 ElecShftPrTrnMlfIO "Electronic Shift Primary Transmission Malfunction Indication On";
BA_ "SignalType" SG_ 1276 ElecShftPrRngInvRqIO "ENM";
BA_ "SignalLongName" SG_ 1276 ElecShftPrRngInvRqIO "Electronic Shift Primary Range Invalid Request Indication On";
BA_ "SignalType" SG_ 1276 ElecShftPrPrkInvRqIO "ENM";
BA_ "SignalLongName" SG_ 1276 ElecShftPrPrkInvRqIO "Electronic Shift Primary Park Invalid Request Indication On";
BA_ "SignalType" SG_ 1276 ElecShftPrLtdPrfMdIO "ENM";
BA_ "SignalLongName" SG_ 1276 ElecShftPrLtdPrfMdIO "Electronic Shift Primary Limited Performance Mode Indication On";
BA_ "SignalType" SG_ 1276 ElecShftPrHldShftLevEngRngIO "ENM";
BA_ "SignalLongName" SG_ 1276 ElecShftPrHldShftLevEngRngIO "Electronic Shift Primary Hold Shift Lever to Engage Range Indication On";
BA_ "SignalType" SG_ 1276 ElecShftPrDrPrkIntShftAtmpIO "ENM";
BA_ "SignalLongName" SG_ 1276 ElecShftPrDrPrkIntShftAtmpIO "Electronic Shift Primary Driver Park Interlock Shift Attempted Indication On";
BA_ "SignalType" SG_ 1276 ElecShftPrDrIntShftAtmpIO "ENM";
BA_ "SignalLongName" SG_ 1276 ElecShftPrDrIntShftAtmpIO "Electronic Shift Primary Driver Interlock Shift Attempted Indication On";
BA_ "SignalType" SG_ 1276 ElecShftPrDrExitIO "ENM";
BA_ "SignalLongName" SG_ 1276 ElecShftPrDrExitIO "Electronic Shift Primary Driver Exit Indication On";
BA_ "SignalType" SG_ 1276 FrwdCllsnSysRdIndOn "ENM";
BA_ "SignalLongName" SG_ 1276 FrwdCllsnSysRdIndOn "Forward Collision System Reduced Indication On";
BA_ "SignalType" SG_ 1276 FrwdCllsnSysOffIndOn "ENM";
BA_ "SignalLongName" SG_ 1276 FrwdCllsnSysOffIndOn "Forward Collision System Off Indication On";
BA_ "SignalType" SG_ 1276 FrwdCllsnAlrtOffIndOn "ENM";
BA_ "SignalLongName" SG_ 1276 FrwdCllsnAlrtOffIndOn "Forward Collision Alert Off Indication On";
BA_ "SignalType" SG_ 1276 FrtPedtrnBrkgWrnIndOn "ENM";
BA_ "SignalLongName" SG_ 1276 FrtPedtrnBrkgWrnIndOn "Front Pedestrian Braking Warning Indication On";
BA_ "SignalType" SG_ 1276 FrntAxlLckIO "ENM";
BA_ "SignalLongName" SG_ 1276 FrntAxlLckIO "Front Axle Lock Indication On";
BA_ "SignalType" SG_ 1276 FrFgLmpIO "ENM";
BA_ "SignalLongName" SG_ 1276 FrFgLmpIO "Front Fog Lamp Indication On";
BA_ "SignalType" SG_ 1276 EngNEmsnsRltMlfnAct "ENM";
BA_ "SignalLongName" SG_ 1276 EngNEmsnsRltMlfnAct "Engine Non Emissions Related Malfunction Active";
BA_ "SignalType" SG_ 1276 EngCstFlCtOffAct "ENM";
BA_ "SignalLongName" SG_ 1276 EngCstFlCtOffAct "Engine Coast Fuel Cut Off Active";
BA_ "SignalType" SG_ 1276 LnCntrArrwBlck4Act "ENM";
BA_ "SignalLongName" SG_ 1276 LnCntrArrwBlck4Act "Lane Centering Arrow Block 4 Active";
BA_ "SignalType" SG_ 1276 LnCntrArrwBlck3Act "ENM";
BA_ "SignalLongName" SG_ 1276 LnCntrArrwBlck3Act "Lane Centering Arrow Block 3 Active";
BA_ "SignalType" SG_ 1276 LnCntrArrwBlck2Act "ENM";
BA_ "SignalLongName" SG_ 1276 LnCntrArrwBlck2Act "Lane Centering Arrow Block 2 Active";
BA_ "SignalType" SG_ 1276 LnCntrArrwBlck1Act "ENM";
BA_ "SignalLongName" SG_ 1276 LnCntrArrwBlck1Act "Lane Centering Arrow Block 1 Active";
BA_ "SignalType" SG_ 1276 HzrdReqActv "ENM";
BA_ "SignalLongName" SG_ 1276 HzrdReqActv "Hazard Request Active";
BA_ "SignalType" SG_ 1276 GenFld "ENM";
BA_ "SignalLongName" SG_ 1276 GenFld "Generator Failed";
BA_ "SignalType" SG_ 1276 FrwdClsnSysIndOn "ENM";
BA_ "SignalLongName" SG_ 1276 FrwdClsnSysIndOn "Forward Collision System Indication On";
BA_ "SignalType" SG_ 1276 FrwdCllsnSysUnIndOn "ENM";
BA_ "SignalLongName" SG_ 1276 FrwdCllsnSysUnIndOn "Forward Collision System Unavailable Indication On";
BA_ "SignalType" SG_ 1276 LvlgSysEntEgrsMdCstAvlFlg3 "ENM";
BA_ "SignalLongName" SG_ 1276 LvlgSysEntEgrsMdCstAvlFlg3 "Leveling System Entry Egress Mode Customization Availability Flag 3";
BA_ "SignalType" SG_ 1276 LvlgSysEntEgrsMdCstAvlFlg2 "ENM";
BA_ "SignalLongName" SG_ 1276 LvlgSysEntEgrsMdCstAvlFlg2 "Leveling System Entry Egress Mode Customization Availability Flag 2";
BA_ "SignalType" SG_ 1276 LvlgSysEntEgrsMdCstAvlFlg1 "ENM";
BA_ "SignalLongName" SG_ 1276 LvlgSysEntEgrsMdCstAvlFlg1 "Leveling System Entry Egress Mode Customization Availability Flag 1";
BA_ "SignalType" SG_ 1276 LvlgSysAlgnMdCstAvlFlg7 "ENM";
BA_ "SignalLongName" SG_ 1276 LvlgSysAlgnMdCstAvlFlg7 "Leveling System Alignment Mode Customization Availability Flag 7";
BA_ "SignalType" SG_ 1276 LvlgSysAlgnMdCstAvlFlg6 "ENM";
BA_ "SignalLongName" SG_ 1276 LvlgSysAlgnMdCstAvlFlg6 "Leveling System Alignment Mode Customization Availability Flag 6";
BA_ "SignalType" SG_ 1276 LnKpAsstUnAvIndOn "ENM";
BA_ "SignalLongName" SG_ 1276 LnKpAsstUnAvIndOn "Lane Keep Assist Unavailable Indication On";
BA_ "SignalType" SG_ 1276 LnDprtrWrngUnAvIndOn "ENM";
BA_ "SignalLongName" SG_ 1276 LnDprtrWrngUnAvIndOn "Lane Departure Warning Unavailable Indication On";
BA_ "SignalType" SG_ 1276 LnCntrArrwBlck5Act "ENM";
BA_ "SignalLongName" SG_ 1276 LnCntrArrwBlck5Act "Lane Centering Arrow Block 5 Active";
BA_ "SignalType" SG_ 1276 LvlgSysServMdCstAvlFlg4 "ENM";
BA_ "SignalLongName" SG_ 1276 LvlgSysServMdCstAvlFlg4 "Leveling System Service Mode Customization Availability Flag 4";
BA_ "SignalType" SG_ 1276 LvlgSysServMdCstAvlFlg3 "ENM";
BA_ "SignalLongName" SG_ 1276 LvlgSysServMdCstAvlFlg3 "Leveling System Service Mode Customization Availability Flag 3";
BA_ "SignalType" SG_ 1276 LvlgSysServMdCstAvlFlg2 "ENM";
BA_ "SignalLongName" SG_ 1276 LvlgSysServMdCstAvlFlg2 "Leveling System Service Mode Customization Availability Flag 2";
BA_ "SignalType" SG_ 1276 LvlgSysServMdCstAvlFlg1 "ENM";
BA_ "SignalLongName" SG_ 1276 LvlgSysServMdCstAvlFlg1 "Leveling System Service Mode Customization Availability Flag 1";
BA_ "SignalType" SG_ 1276 LvlgSysEntEgrsMdCstAvlFlg7 "ENM";
BA_ "SignalLongName" SG_ 1276 LvlgSysEntEgrsMdCstAvlFlg7 "Leveling System Entry Egress Mode Customization Availability Flag 7";
BA_ "SignalType" SG_ 1276 LvlgSysEntEgrsMdCstAvlFlg6 "ENM";
BA_ "SignalLongName" SG_ 1276 LvlgSysEntEgrsMdCstAvlFlg6 "Leveling System Entry Egress Mode Customization Availability Flag 6";
BA_ "SignalType" SG_ 1276 LvlgSysEntEgrsMdCstAvlFlg5 "ENM";
BA_ "SignalLongName" SG_ 1276 LvlgSysEntEgrsMdCstAvlFlg5 "Leveling System Entry Egress Mode Customization Availability Flag 5";
BA_ "SignalType" SG_ 1276 LvlgSysEntEgrsMdCstAvlFlg4 "ENM";
BA_ "SignalLongName" SG_ 1276 LvlgSysEntEgrsMdCstAvlFlg4 "Leveling System Entry Egress Mode Customization Availability Flag 4";
BA_ "SignalType" SG_ 1276 PrkAsstActIndCmnd "ENM";
BA_ "SignalLongName" SG_ 1276 PrkAsstActIndCmnd "Park Assist Active Indication Command";
BA_ "SignalType" SG_ 1276 NoKeyDtdElecShfDndIndOn "ENM";
BA_ "SignalLongName" SG_ 1276 NoKeyDtdElecShfDndIndOn "No Key Detected Electronic Shift Denied Indication On";
BA_ "SignalType" SG_ 1276 MemStorTmdOutIndOn "ENM";
BA_ "SignalLongName" SG_ 1276 MemStorTmdOutIndOn "Memory Store Timed Out Indication On";
BA_ "SignalType" SG_ 1276 MemStorPrssSetFrstIndOn "ENM";
BA_ "SignalLongName" SG_ 1276 MemStorPrssSetFrstIndOn "Memory Store Press Set First Indication On";
BA_ "SignalType" SG_ 1276 MemSeeAutoRclSetsIndOn "ENM";
BA_ "SignalLongName" SG_ 1276 MemSeeAutoRclSetsIndOn "Memory See Auto Recall Settings Indication On";
BA_ "SignalType" SG_ 1276 LvlgSysServMdCstAvlFlg7 "ENM";
BA_ "SignalLongName" SG_ 1276 LvlgSysServMdCstAvlFlg7 "Leveling System Service Mode Customization Availability Flag 7";
BA_ "SignalType" SG_ 1276 LvlgSysServMdCstAvlFlg6 "ENM";
BA_ "SignalLongName" SG_ 1276 LvlgSysServMdCstAvlFlg6 "Leveling System Service Mode Customization Availability Flag 6";
BA_ "SignalType" SG_ 1276 LvlgSysServMdCstAvlFlg5 "ENM";
BA_ "SignalLongName" SG_ 1276 LvlgSysServMdCstAvlFlg5 "Leveling System Service Mode Customization Availability Flag 5";
BA_ "SignalType" SG_ 1276 SftTpFlrIO "ENM";
BA_ "SignalLongName" SG_ 1276 SftTpFlrIO "Soft Top Failure Indication On";
BA_ "SignalType" SG_ 1276 RrVirtBmpAutoBrkRelIndOn "ENM";
BA_ "SignalLongName" SG_ 1276 RrVirtBmpAutoBrkRelIndOn "Rear Virtual Bumper Autonomous Brake Release Indication On";
BA_ "SignalType" SG_ 1276 RrFgLmpIO "ENM";
BA_ "SignalLongName" SG_ 1276 RrFgLmpIO "Rear Fog Lamp Indication On";
BA_ "SignalType" SG_ 1276 RrAxlLckIO "ENM";
BA_ "SignalLongName" SG_ 1276 RrAxlLckIO "Rear Axle Lock Indication On";
BA_ "SignalType" SG_ 1276 RmtRflshDispActvnReq "ENM";
BA_ "SignalLongName" SG_ 1276 RmtRflshDispActvnReq "Remote Reflash Display Activation Request";
BA_ "SignalType" SG_ 1276 RmtRflshCmpgnAval "ENM";
BA_ "SignalLongName" SG_ 1276 RmtRflshCmpgnAval "Remote Reflash Campaign Available";
BA_ "SignalType" SG_ 1276 ROSP_FrtPsRestOcpFltIndAuth "ENM";
BA_ "SignalLongName" SG_ 1276 ROSP_FrtPsRestOcpFltIndAuth "Restraint Occupancy Status Protected : Front Passenger Restraint Occupancy Fault Indication Authenticated";
BA_ "SignalType" SG_ 1276 StNtLtchdIO "ENM";
BA_ "SignalLongName" SG_ 1276 StNtLtchdIO "Seat Not Latched Indication On";
BA_ "SignalType" SG_ 1276 SrvPedtrnProtSysIO "ENM";
BA_ "SignalLongName" SG_ 1276 SrvPedtrnProtSysIO "Service Pedestrian Protection System Indication On";
BA_ "SignalType" SG_ 1276 SrvFrwdCllsnSysIndOn "ENM";
BA_ "SignalLongName" SG_ 1276 SrvFrwdCllsnSysIndOn "Service Forward Collision System Indication On";
BA_ "SignalType" SG_ 1276 SrvDvrAsstSystVslMsgRqstOn "ENM";
BA_ "SignalLongName" SG_ 1276 SrvDvrAsstSystVslMsgRqstOn "Service Driver Assist System Visual Message Request On";
BA_ "SignalType" SG_ 1276 SftTpVltLwIO "ENM";
BA_ "SignalLongName" SG_ 1276 SftTpVltLwIO "Soft Top Voltage Low Indication On";
BA_ "SignalType" SG_ 1276 SftTpVehOvSpdIO "ENM";
BA_ "SignalLongName" SG_ 1276 SftTpVehOvSpdIO "Soft Top Vehicle Overspeed Indication On";
BA_ "SignalType" SG_ 1276 SftTpTmpLwIO "ENM";
BA_ "SignalLongName" SG_ 1276 SftTpTmpLwIO "Soft Top Temperature Low Indication On";
BA_ "SignalType" SG_ 1534 TrlrFgLtFld "ENM";
BA_ "SignalLongName" SG_ 1534 TrlrFgLtFld "Trailer Fog Light Failed";
BA_ "SignalType" SG_ 1534 TrlrDisconndIndOn "ENM";
BA_ "SignalLongName" SG_ 1534 TrlrDisconndIndOn "Trailer Disconnected Indication On";
BA_ "SignalType" SG_ 1534 TrlrBrkLtFld "ENM";
BA_ "SignalLongName" SG_ 1534 TrlrBrkLtFld "Trailer Brake Light Failed";
BA_ "SignalType" SG_ 1534 TrlLfTrInLtFld "ENM";
BA_ "SignalLongName" SG_ 1534 TrlLfTrInLtFld "Trailer Left Turn Indicator Light Failed";
BA_ "SignalType" SG_ 1534 TnDrvRIMOFFUnvIndOn "ENM";
BA_ "SignalLongName" SG_ 1534 TnDrvRIMOFFUnvIndOn "Teen Driver Rearward Impact Mitigation OFF Unavailable Indication On";
BA_ "SignalType" SG_ 1534 TnDrvGapAdjUnvIndOn "ENM";
BA_ "SignalLongName" SG_ 1534 TnDrvGapAdjUnvIndOn "Teen Driver Gap Adjust Unavailable Indication On";
BA_ "SignalType" SG_ 1534 TeenDrvrLnDprtrWrnOffUnvIndOn "ENM";
BA_ "SignalLongName" SG_ 1534 TeenDrvrLnDprtrWrnOffUnvIndOn "Teen Driver Lane Departure Warning Off Unavailable Indication On";
BA_ "SignalType" SG_ 1534 StlthModeActv "ENM";
BA_ "SignalLongName" SG_ 1534 StlthModeActv "Stealth Mode Active";
BA_ "SignalType" SG_ 1534 TrnsEmsRltMlfAtv "ENM";
BA_ "SignalLongName" SG_ 1534 TrnsEmsRltMlfAtv "Transmission Emissions Related Malfunction Active";
BA_ "SignalType" SG_ 1534 TrnLmpRrRtOtgIndOn "ENM";
BA_ "SignalLongName" SG_ 1534 TrnLmpRrRtOtgIndOn "Turn Lamp Rear Right Outage Indication On";
BA_ "SignalType" SG_ 1534 TrnLmpRrLtOtgIndOn "ENM";
BA_ "SignalLongName" SG_ 1534 TrnLmpRrLtOtgIndOn "Turn Lamp Rear Left Outage Indication On";
BA_ "SignalType" SG_ 1534 TrnLmpFrtRtOtgIndOn "ENM";
BA_ "SignalLongName" SG_ 1534 TrnLmpFrtRtOtgIndOn "Turn Lamp Front Right Outage Indication On";
BA_ "SignalType" SG_ 1534 TrnLmpFrtLtOtgIndOn "ENM";
BA_ "SignalLongName" SG_ 1534 TrnLmpFrtLtOtgIndOn "Turn Lamp Front Left Outage Indication On";
BA_ "SignalType" SG_ 1534 TrlrTlLtFld "ENM";
BA_ "SignalLongName" SG_ 1534 TrlrTlLtFld "Trailer Tail Light Failed";
BA_ "SignalType" SG_ 1534 TrlrRvrsLmpOtgIndOn "ENM";
BA_ "SignalLongName" SG_ 1534 TrlrRvrsLmpOtgIndOn "Trailer Reverse Lamp Outage Indication On";
BA_ "SignalType" SG_ 1534 TrlrRtTrInLtFld "ENM";
BA_ "SignalLongName" SG_ 1534 TrlrRtTrInLtFld "Trailer Right Turn Indicator Light Failed";
BA_ "SignalType" SG_ 1534 SnrfActlPstn "ENM";
BA_ "SignalLongName" SG_ 1534 SnrfActlPstn "Sunroof Actual Position";
BA_ "SignalType" SG_ 1534 TrnsThrmlMngmntSt "ENM";
BA_ "SignalLongName" SG_ 1534 TrnsThrmlMngmntSt "Transmission Thermal Management Status";
BA_ "SignalType" SG_ 1534 VltSwAtvIO "ENM";
BA_ "SignalLongName" SG_ 1534 VltSwAtvIO "Valet Switch Active Indication On";
BA_ "SignalType" SG_ 1534 UIDInStatusSD "ENM";
BA_ "SignalLongName" SG_ 1534 UIDInStatusSD "UID in Status";
BA_ "SignalType" SG_ 1534 TrnstStrgLogisticsMdActivation "ENM";
BA_ "SignalLongName" SG_ 1534 TrnstStrgLogisticsMdActivation "Transport/Storage Logistics Mode Activation";
BA_ "SignalType" SG_ 1534 TrnsOilChngIO "ENM";
BA_ "SignalLongName" SG_ 1534 TrnsOilChngIO "Transmission Oil Change Indication On";
BA_ "SignalType" SG_ 1534 TrnsNEmsRltMlfActv "ENM";
BA_ "SignalLongName" SG_ 1534 TrnsNEmsRltMlfActv "Transmission Non Emissions Related Malfunction Active";
BA_ "SignalType" SG_ 1534 ADASMsgDispLocNonActvInd "ENM";
BA_ "SignalLongName" SG_ 1534 ADASMsgDispLocNonActvInd "Advanced Driver Assist Systems Message Display Location Non Active Indication";
BA_ "SignalType" SG_ 1534 ADASMsgDispLocLtdPerfStatInd "ENM";
BA_ "SignalLongName" SG_ 1534 ADASMsgDispLocLtdPerfStatInd "Advanced Driver Assist Systems Message Display Location Limited Performance State Indication";
BA_ "SignalType" SG_ 1534 ArflBsdOnOccpRrPsCstCurrSetVal "ENM";
BA_ "SignalLongName" SG_ 1534 ArflBsdOnOccpRrPsCstCurrSetVal "Airflow Based On Occupancy Rear Passenger Customization Current Setting Value";
BA_ "SignalType" SG_ 1534 ArflBsdOnOccpFrtPsCstCurrSetVal "ENM";
BA_ "SignalLongName" SG_ 1534 ArflBsdOnOccpFrtPsCstCurrSetVal "Airflow Based On Occupancy Front Passenger Customization Current Setting Value";
BA_ "SignalType" SG_ 1534 ADASTrmLvlInd "ENM";
BA_ "SignalLongName" SG_ 1534 ADASTrmLvlInd "Advanced Driver Assist Systems Trim Level Indication";
BA_ "SignalType" SG_ 1534 LnCntrWrn2IndReq "ENM";
BA_ "SignalLongName" SG_ 1534 LnCntrWrn2IndReq "Lane Centering Warning 2 Indication Request";
BA_ "SignalLongName" SG_ 1824 TmSyncMsg "Time Sync Message";
BA_ "SignalLongName" SG_ 1824 WDP_WhlDistPerRevFrtAuth "Wheel Distance Protected : Wheel Distance Per Revolution Front Authenticated";
BA_ "SignalLongName" SG_ 1824 WDP_WhlDistPerRevRrAuth "Wheel Distance Protected : Wheel Distance Per Revolution Rear Authenticated";
BA_ "SignalType" SG_ 1824 SprTireSt "ENM";
BA_ "SignalLongName" SG_ 1824 SprTireSt "Spare Tire Status";
BA_ "SignalType" SG_ 1824 BrkFldLvlSt "ENM";
BA_ "SignalLongName" SG_ 1824 BrkFldLvlSt "Brake Fluid Level Status";
BA_ "SignalLongName" SG_ 1241 ACRfHiSdFldPrs "Air Conditioning Refrigerant High Side Fluid Pressure";
BA_ "SignalType" SG_ 1241 ACRfHiSdFldPrs_Inv "ENM";
BA_ "SignalLongName" SG_ 1241 ACRfHiSdFldPrs_Inv "Air Conditioning Refrigerant High Side Fluid Pressure Invalid";
BA_ "SignalLongName" SG_ 1241 ArbdEngTemp "Arbitrated Engine Temperature";
BA_ "SignalType" SG_ 1241 ArbdEngTemp_Inv "ENM";
BA_ "SignalLongName" SG_ 1241 ArbdEngTemp_Inv "Arbitrated Engine Temperature Invalid";
BA_ "SignalLongName" SG_ 1241 BarPrsAbs "Barometric Pressure Absolute";
BA_ "SignalType" SG_ 1241 BarPrsAbs_Inv "ENM";
BA_ "SignalLongName" SG_ 1241 BarPrsAbs_Inv "Barometric Pressure Absolute Invalid";
BA_ "SignalLongName" SG_ 1241 DslExhFldLvlPct "Diesel Exhaust Fluid Level Percent";
BA_ "SignalType" SG_ 1241 DslExhFldLvlPct_Inv "ENM";
BA_ "SignalLongName" SG_ 1241 DslExhFldLvlPct_Inv "Diesel Exhaust Fluid Level Percent Invalid";
BA_ "SignalLongName" SG_ 1241 ElecMtrARotrTemp "Propulsion System Motor A Rotor Temperature";
BA_ "SignalType" SG_ 1241 ElecMtrARotrTemp_Inv "ENM";
BA_ "SignalLongName" SG_ 1241 ElecMtrARotrTemp_Inv "Propulsion System Motor A Rotor Temperature Invalid";
BA_ "SignalLongName" SG_ 1241 ElecMtrASttrTemp "Propulsion System Motor A Stator Temperature";
BA_ "SignalType" SG_ 1241 ElecMtrASttrTemp_Inv "ENM";
BA_ "SignalLongName" SG_ 1241 ElecMtrASttrTemp_Inv "Propulsion System Motor A Stator Temperature Invalid";
BA_ "SignalLongName" SG_ 1241 HiVltgBatMaxTemp "High Voltage Battery Maximum Temperature";
BA_ "SignalType" SG_ 1241 HiVltgBatMaxTemp_Inv "ENM";
BA_ "SignalLongName" SG_ 1241 HiVltgBatMaxTemp_Inv "High Voltage Battery Maximum Temperature Invalid";
BA_ "SignalType" SG_ 1241 ABSPr "ENM";
BA_ "SignalLongName" SG_ 1241 ABSPr "Antilock Brake System Present";
BA_ "SignalLongName" SG_ 1825 HiVltgBatMinTemp "High Voltage Battery Minimum Temperature";
BA_ "SignalType" SG_ 1825 HiVltgBatMinTemp_Inv "ENM";
BA_ "SignalLongName" SG_ 1825 HiVltgBatMinTemp_Inv "High Voltage Battery Minimum Temperature Invalid";
BA_ "SignalLongName" SG_ 1825 TrnsOilTmp "Transmission Oil Temperature";
BA_ "SignalType" SG_ 1825 TrnsOilTmp_Inv "ENM";
BA_ "SignalLongName" SG_ 1825 TrnsOilTmp_Inv "Transmission Oil Temperature Invalid";
BA_ "SignalLongName" SG_ 1825 ACCmpNrmLdGrdAld "Air Conditioning Compressor Normalized Load Gradient Allowed";
BA_ "SignalLongName" SG_ 1825 EngCoolFanSpd "Engine Cooling Fan Speed";
BA_ "SignalLongName" SG_ 1825 HtrCoreInltClntTmpCalc "Heater Core Inlet Coolant Temperature Calculated";
BA_ "SignalLongName" SG_ 1825 PrplDispTotPwrLvlPct "Propulsion Display Total Power Level Percent";
BA_ "SignalLongName" SG_ 1825 TireTmpLF "Tire Temperature (LF)";
BA_ "SignalType" SG_ 1825 TireTmpLF_Inv "ENM";
BA_ "SignalLongName" SG_ 1825 TireTmpLF_Inv "Tire Temperature (LF) Invalid";
BA_ "SignalType" SG_ 1825 AdpLghtRspTypCstAvlFlg2 "ENM";
BA_ "SignalLongName" SG_ 1825 AdpLghtRspTypCstAvlFlg2 "Adaptive Lighting Response Type Customization Availability Flag2";
BA_ "SignalType" SG_ 1825 AdpLghtRspTypCstAvlFlg1 "ENM";
BA_ "SignalLongName" SG_ 1825 AdpLghtRspTypCstAvlFlg1 "Adaptive Lighting Response Type Customization Availability Flag1";
BA_ "SignalLongName" SG_ 1240 TireTmpLR "Tire Temperature (LR)";
BA_ "SignalType" SG_ 1240 TireTmpLR_Inv "ENM";
BA_ "SignalLongName" SG_ 1240 TireTmpLR_Inv "Tire Temperature (LR) Invalid";
BA_ "SignalLongName" SG_ 1240 TireTmpRF "Tire Temperature (RF)";
BA_ "SignalType" SG_ 1240 TireTmpRF_Inv "ENM";
BA_ "SignalLongName" SG_ 1240 TireTmpRF_Inv "Tire Temperature (RF) Invalid";
BA_ "SignalLongName" SG_ 1240 TireTmpRR "Tire Temperature (RR)";
BA_ "SignalType" SG_ 1240 TireTmpRR_Inv "ENM";
BA_ "SignalLongName" SG_ 1240 TireTmpRR_Inv "Tire Temperature (RR) Invalid";
BA_ "SignalType" SG_ 1240 FrtRdHgtGPSCstAvlbltyFlg7 "ENM";
BA_ "SignalLongName" SG_ 1240 FrtRdHgtGPSCstAvlbltyFlg7 "Front Ride Height GPS Customization Availability Flag 7";
BA_ "SignalType" SG_ 1240 FrtRdHgtGPSCstAvlbltyFlg6 "ENM";
BA_ "SignalLongName" SG_ 1240 FrtRdHgtGPSCstAvlbltyFlg6 "Front Ride Height GPS Customization Availability Flag 6";
BA_ "SignalType" SG_ 1240 FrtRdHgtGPSCstAvlbltyFlg5 "ENM";
BA_ "SignalLongName" SG_ 1240 FrtRdHgtGPSCstAvlbltyFlg5 "Front Ride Height GPS Customization Availability Flag 5";
BA_ "SignalType" SG_ 1240 FrtRdHgtGPSCstAvlbltyFlg4 "ENM";
BA_ "SignalLongName" SG_ 1240 FrtRdHgtGPSCstAvlbltyFlg4 "Front Ride Height GPS Customization Availability Flag 4";
BA_ "SignalType" SG_ 1240 FrtRdHgtGPSCstAvlbltyFlg3 "ENM";
BA_ "SignalLongName" SG_ 1240 FrtRdHgtGPSCstAvlbltyFlg3 "Front Ride Height GPS Customization Availability Flag 3";
BA_ "SignalType" SG_ 1240 FrtRdHgtGPSCstAvlbltyFlg2 "ENM";
BA_ "SignalLongName" SG_ 1240 FrtRdHgtGPSCstAvlbltyFlg2 "Front Ride Height GPS Customization Availability Flag 2";
BA_ "SignalType" SG_ 1240 FrtRdHgtGPSCstAvlbltyFlg1 "ENM";
BA_ "SignalLongName" SG_ 1240 FrtRdHgtGPSCstAvlbltyFlg1 "Front Ride Height GPS Customization Availability Flag 1";
BA_ "SignalType" SG_ 1240 AdpLghtRspTypCstAvlFlg3 "ENM";
BA_ "SignalLongName" SG_ 1240 AdpLghtRspTypCstAvlFlg3 "Adaptive Lighting Response Type Customization Availability Flag3";
BA_ "SignalType" SG_ 1240 LvlgSysAlgnMdCstAvlFlg1 "ENM";
BA_ "SignalLongName" SG_ 1240 LvlgSysAlgnMdCstAvlFlg1 "Leveling System Alignment Mode Customization Availability Flag 1";
BA_ "SignalType" SG_ 1240 LtRtHnTrCstAvlFlg7 "ENM";
BA_ "SignalLongName" SG_ 1240 LtRtHnTrCstAvlFlg7 "Left Right Hand Traffic Customization Availability Flag7";
BA_ "SignalType" SG_ 1240 LtRtHnTrCstAvlFlg6 "ENM";
BA_ "SignalLongName" SG_ 1240 LtRtHnTrCstAvlFlg6 "Left Right Hand Traffic Customization Availability Flag6";
BA_ "SignalType" SG_ 1240 LtRtHnTrCstAvlFlg5 "ENM";
BA_ "SignalLongName" SG_ 1240 LtRtHnTrCstAvlFlg5 "Left Right Hand Traffic Customization Availability Flag5";
BA_ "SignalType" SG_ 1240 LtRtHnTrCstAvlFlg4 "ENM";
BA_ "SignalLongName" SG_ 1240 LtRtHnTrCstAvlFlg4 "Left Right Hand Traffic Customization Availability Flag4";
BA_ "SignalType" SG_ 1240 LtRtHnTrCstAvlFlg3 "ENM";
BA_ "SignalLongName" SG_ 1240 LtRtHnTrCstAvlFlg3 "Left Right Hand Traffic Customization Availability Flag3";
BA_ "SignalType" SG_ 1240 LtRtHnTrCstAvlFlg2 "ENM";
BA_ "SignalLongName" SG_ 1240 LtRtHnTrCstAvlFlg2 "Left Right Hand Traffic Customization Availability Flag2";
BA_ "SignalType" SG_ 1240 LtRtHnTrCstAvlFlg1 "ENM";
BA_ "SignalLongName" SG_ 1240 LtRtHnTrCstAvlFlg1 "Left Right Hand Traffic Customization Availability Flag1";
BA_ "SignalType" SG_ 1240 PrkAsstONOFFCstAvlFlg3 "ENM";
BA_ "SignalLongName" SG_ 1240 PrkAsstONOFFCstAvlFlg3 "Park Assist On Off Customization Availability Flag 3";
BA_ "SignalType" SG_ 1240 PrkAsstONOFFCstAvlFlg2 "ENM";
BA_ "SignalLongName" SG_ 1240 PrkAsstONOFFCstAvlFlg2 "Park Assist On Off Customization Availability Flag2";
BA_ "SignalType" SG_ 1240 PrkAsstONOFFCstAvlFlg1 "ENM";
BA_ "SignalLongName" SG_ 1240 PrkAsstONOFFCstAvlFlg1 "Park Assist On Off Customization Availability Flag 1";
BA_ "SignalType" SG_ 1240 PTHiElecLdReqd "ENM";
BA_ "SignalLongName" SG_ 1240 PTHiElecLdReqd "Powertrain High Electrical Load Requested";
BA_ "SignalType" SG_ 1240 LvlgSysAlgnMdCstAvlFlg5 "ENM";
BA_ "SignalLongName" SG_ 1240 LvlgSysAlgnMdCstAvlFlg5 "Leveling System Alignment Mode Customization Availability Flag 5";
BA_ "SignalType" SG_ 1240 LvlgSysAlgnMdCstAvlFlg4 "ENM";
BA_ "SignalLongName" SG_ 1240 LvlgSysAlgnMdCstAvlFlg4 "Leveling System Alignment Mode Customization Availability Flag 4";
BA_ "SignalType" SG_ 1240 LvlgSysAlgnMdCstAvlFlg3 "ENM";
BA_ "SignalLongName" SG_ 1240 LvlgSysAlgnMdCstAvlFlg3 "Leveling System Alignment Mode Customization Availability Flag 3";
BA_ "SignalType" SG_ 1240 LvlgSysAlgnMdCstAvlFlg2 "ENM";
BA_ "SignalLongName" SG_ 1240 LvlgSysAlgnMdCstAvlFlg2 "Leveling System Alignment Mode Customization Availability Flag 2";
BA_ "SignalType" SG_ 1240 PrkAsstTrHtchPsntCstAvlFlg4 "ENM";
BA_ "SignalLongName" SG_ 1240 PrkAsstTrHtchPsntCstAvlFlg4 "Park Assist Trailer Hitch Present Customization Availability Flag 4";
BA_ "SignalType" SG_ 1240 PrkAsstTrHtchPsntCstAvlFlg3 "ENM";
BA_ "SignalLongName" SG_ 1240 PrkAsstTrHtchPsntCstAvlFlg3 "Park Assist Trailer Hitch Present Customization Availability Flag 3";
BA_ "SignalType" SG_ 1240 PrkAsstTrHtchPsntCstAvlFlg2 "ENM";
BA_ "SignalLongName" SG_ 1240 PrkAsstTrHtchPsntCstAvlFlg2 "Park Assist Trailer Hitch Present Customization Availability Flag 2";
BA_ "SignalType" SG_ 1240 PrkAsstTrHtchPsntCstAvlFlg1 "ENM";
BA_ "SignalLongName" SG_ 1240 PrkAsstTrHtchPsntCstAvlFlg1 "Park Assist Trailer Hitch Present Customization Availability Flag 1";
BA_ "SignalType" SG_ 1240 PrkAsstONOFFCstAvlFlg7 "ENM";
BA_ "SignalLongName" SG_ 1240 PrkAsstONOFFCstAvlFlg7 "Park Assist On Off Customization Availability Flag 7";
BA_ "SignalType" SG_ 1240 PrkAsstONOFFCstAvlFlg6 "ENM";
BA_ "SignalLongName" SG_ 1240 PrkAsstONOFFCstAvlFlg6 "Park Assist On Off Customization Availability Flag 6";
BA_ "SignalType" SG_ 1240 PrkAsstONOFFCstAvlFlg5 "ENM";
BA_ "SignalLongName" SG_ 1240 PrkAsstONOFFCstAvlFlg5 "Park Assist On Off Customization Availability Flag 5";
BA_ "SignalType" SG_ 1240 PrkAsstONOFFCstAvlFlg4 "ENM";
BA_ "SignalLongName" SG_ 1240 PrkAsstONOFFCstAvlFlg4 "Park Assist On Off Customization Availability Flag 4";
BA_ "SignalType" SG_ 1826 RnngBrdAutoDplyCstAvlFlg5 "ENM";
BA_ "SignalLongName" SG_ 1826 RnngBrdAutoDplyCstAvlFlg5 "Running Boards Automatic Deployment Customization Availability Flag 5";
BA_ "SignalType" SG_ 1826 RnngBrdAutoDplyCstAvlFlg4 "ENM";
BA_ "SignalLongName" SG_ 1826 RnngBrdAutoDplyCstAvlFlg4 "Running Boards Automatic Deployment Customization Availability Flag 4";
BA_ "SignalType" SG_ 1826 RnngBrdAutoDplyCstAvlFlg3 "ENM";
BA_ "SignalLongName" SG_ 1826 RnngBrdAutoDplyCstAvlFlg3 "Running Boards Automatic Deployment Customization Availability Flag 3";
BA_ "SignalType" SG_ 1826 RnngBrdAutoDplyCstAvlFlg2 "ENM";
BA_ "SignalLongName" SG_ 1826 RnngBrdAutoDplyCstAvlFlg2 "Running Boards Automatic Deployment Customization Availability Flag 2";
BA_ "SignalType" SG_ 1826 RnngBrdAutoDplyCstAvlFlg1 "ENM";
BA_ "SignalLongName" SG_ 1826 RnngBrdAutoDplyCstAvlFlg1 "Running Boards Automatic Deployment Customization Availability Flag 1";
BA_ "SignalType" SG_ 1826 PrkAsstTrHtchPsntCstAvlFlg7 "ENM";
BA_ "SignalLongName" SG_ 1826 PrkAsstTrHtchPsntCstAvlFlg7 "Park Assist Trailer Hitch Present Customization Availability Flag 7";
BA_ "SignalType" SG_ 1826 PrkAsstTrHtchPsntCstAvlFlg6 "ENM";
BA_ "SignalLongName" SG_ 1826 PrkAsstTrHtchPsntCstAvlFlg6 "Park Assist Trailer Hitch Present Customization Availability Flag 6";
BA_ "SignalType" SG_ 1826 PrkAsstTrHtchPsntCstAvlFlg5 "ENM";
BA_ "SignalLongName" SG_ 1826 PrkAsstTrHtchPsntCstAvlFlg5 "Park Assist Trailer Hitch Present Customization Availability Flag 5";
BA_ "SignalType" SG_ 1826 RnngBrdManDplyCstAvlFlg6 "ENM";
BA_ "SignalLongName" SG_ 1826 RnngBrdManDplyCstAvlFlg6 "Running Boards Manual Deployment Customization Availability Flag 6";
BA_ "SignalType" SG_ 1826 RnngBrdManDplyCstAvlFlg5 "ENM";
BA_ "SignalLongName" SG_ 1826 RnngBrdManDplyCstAvlFlg5 "Running Boards Manual Deployment Customization Availability Flag 5";
BA_ "SignalType" SG_ 1826 RnngBrdManDplyCstAvlFlg4 "ENM";
BA_ "SignalLongName" SG_ 1826 RnngBrdManDplyCstAvlFlg4 "Running Boards Manual Deployment Customization Availability Flag 4";
BA_ "SignalType" SG_ 1826 RnngBrdManDplyCstAvlFlg3 "ENM";
BA_ "SignalLongName" SG_ 1826 RnngBrdManDplyCstAvlFlg3 "Running Boards Manual Deployment Customization Availability Flag 3";
BA_ "SignalType" SG_ 1826 RnngBrdManDplyCstAvlFlg2 "ENM";
BA_ "SignalLongName" SG_ 1826 RnngBrdManDplyCstAvlFlg2 "Running Boards Manual Deployment Customization Availability Flag 2";
BA_ "SignalType" SG_ 1826 RnngBrdManDplyCstAvlFlg1 "ENM";
BA_ "SignalLongName" SG_ 1826 RnngBrdManDplyCstAvlFlg1 "Running Boards Manual Deployment Customization Availability Flag 1";
BA_ "SignalType" SG_ 1826 RnngBrdAutoDplyCstAvlFlg7 "ENM";
BA_ "SignalLongName" SG_ 1826 RnngBrdAutoDplyCstAvlFlg7 "Running Boards Automatic Deployment Customization Availability Flag 7";
BA_ "SignalType" SG_ 1826 RnngBrdAutoDplyCstAvlFlg6 "ENM";
BA_ "SignalLongName" SG_ 1826 RnngBrdAutoDplyCstAvlFlg6 "Running Boards Automatic Deployment Customization Availability Flag 6";
BA_ "SignalType" SG_ 1826 RrVwPrkAstSymCsAvlFlg7 "ENM";
BA_ "SignalLongName" SG_ 1826 RrVwPrkAstSymCsAvlFlg7 "Rear View Park Assist Symbol Customization Availability Flag 7";
BA_ "SignalType" SG_ 1826 RrVwPrkAstSymCsAvlFlg6 "ENM";
BA_ "SignalLongName" SG_ 1826 RrVwPrkAstSymCsAvlFlg6 "Rear View Park Assist Symbol Customization Availability Flag 6";
BA_ "SignalType" SG_ 1826 RrVwPrkAstSymCsAvlFlg5 "ENM";
BA_ "SignalLongName" SG_ 1826 RrVwPrkAstSymCsAvlFlg5 "Rear View Park Assist Symbol Customization Availability Flag 5";
BA_ "SignalType" SG_ 1826 RrVwPrkAstSymCsAvlFlg4 "ENM";
BA_ "SignalLongName" SG_ 1826 RrVwPrkAstSymCsAvlFlg4 "Rear View Park Assist Symbol Customization Availability Flag 4";
BA_ "SignalType" SG_ 1826 RrVwPrkAstSymCsAvlFlg3 "ENM";
BA_ "SignalLongName" SG_ 1826 RrVwPrkAstSymCsAvlFlg3 "Rear View Park Assist Symbol Customization Availability Flag 3";
BA_ "SignalType" SG_ 1826 RrVwPrkAstSymCsAvlFlg2 "ENM";
BA_ "SignalLongName" SG_ 1826 RrVwPrkAstSymCsAvlFlg2 "Rear View Park Assist Symbol Customization Availability Flag 2";
BA_ "SignalType" SG_ 1826 RrVwPrkAstSymCsAvlFlg1 "ENM";
BA_ "SignalLongName" SG_ 1826 RrVwPrkAstSymCsAvlFlg1 "Rear View Park Assist Symbol Customization Availability Flag 1";
BA_ "SignalType" SG_ 1826 RnngBrdManDplyCstAvlFlg7 "ENM";
BA_ "SignalLongName" SG_ 1826 RnngBrdManDplyCstAvlFlg7 "Running Boards Manual Deployment Customization Availability Flag 7";
BA_ "SignalType" SG_ 1826 StBltTghtngCstAvlFlg1 "ENM";
BA_ "SignalLongName" SG_ 1826 StBltTghtngCstAvlFlg1 "Seat Belt Tightening Customization Availability Flag 1";
BA_ "SignalType" SG_ 1826 SrrndVwLghtCsAvlFlg7 "ENM";
BA_ "SignalLongName" SG_ 1826 SrrndVwLghtCsAvlFlg7 "Surround View Lighting Customization Availability Flag 7";
BA_ "SignalType" SG_ 1826 SrrndVwLghtCsAvlFlg6 "ENM";
BA_ "SignalLongName" SG_ 1826 SrrndVwLghtCsAvlFlg6 "Surround View Lighting Customization Availability Flag 6";
BA_ "SignalType" SG_ 1826 SrrndVwLghtCsAvlFlg5 "ENM";
BA_ "SignalLongName" SG_ 1826 SrrndVwLghtCsAvlFlg5 "Surround View Lighting Customization Availability Flag 5";
BA_ "SignalType" SG_ 1826 SrrndVwLghtCsAvlFlg4 "ENM";
BA_ "SignalLongName" SG_ 1826 SrrndVwLghtCsAvlFlg4 "Surround View Lighting Customization Availability Flag 4";
BA_ "SignalType" SG_ 1826 SrrndVwLghtCsAvlFlg3 "ENM";
BA_ "SignalLongName" SG_ 1826 SrrndVwLghtCsAvlFlg3 "Surround View Lighting Customization Availability Flag 3";
BA_ "SignalType" SG_ 1826 SrrndVwLghtCsAvlFlg2 "ENM";
BA_ "SignalLongName" SG_ 1826 SrrndVwLghtCsAvlFlg2 "Surround View Lighting Customization Availability Flag 2";
BA_ "SignalType" SG_ 1826 SrrndVwLghtCsAvlFlg1 "ENM";
BA_ "SignalLongName" SG_ 1826 SrrndVwLghtCsAvlFlg1 "Surround View Lighting Customization Availability Flag 1";
BA_ "SignalType" SG_ 1826 TnDrvStBltShfIntlkCstAvlFlg2 "ENM";
BA_ "SignalLongName" SG_ 1826 TnDrvStBltShfIntlkCstAvlFlg2 "Teen Driver Seat Belt Shift Interlock Customization Availability Flag2";
BA_ "SignalType" SG_ 1826 TnDrvStBltShfIntlkCstAvlFlg1 "ENM";
BA_ "SignalLongName" SG_ 1826 TnDrvStBltShfIntlkCstAvlFlg1 "Teen Driver Seat Belt Shift Interlock Customization Availability Flag1";
BA_ "SignalType" SG_ 1826 StBltTghtngCstAvlFlg7 "ENM";
BA_ "SignalLongName" SG_ 1826 StBltTghtngCstAvlFlg7 "Seat Belt Tightening Customization Availability Flag 7";
BA_ "SignalType" SG_ 1826 StBltTghtngCstAvlFlg6 "ENM";
BA_ "SignalLongName" SG_ 1826 StBltTghtngCstAvlFlg6 "Seat Belt Tightening Customization Availability Flag 6";
BA_ "SignalType" SG_ 1826 StBltTghtngCstAvlFlg5 "ENM";
BA_ "SignalLongName" SG_ 1826 StBltTghtngCstAvlFlg5 "Seat Belt Tightening Customization Availability Flag 5";
BA_ "SignalType" SG_ 1826 StBltTghtngCstAvlFlg4 "ENM";
BA_ "SignalLongName" SG_ 1826 StBltTghtngCstAvlFlg4 "Seat Belt Tightening Customization Availability Flag 4";
BA_ "SignalType" SG_ 1826 StBltTghtngCstAvlFlg3 "ENM";
BA_ "SignalLongName" SG_ 1826 StBltTghtngCstAvlFlg3 "Seat Belt Tightening Customization Availability Flag 3";
BA_ "SignalType" SG_ 1826 StBltTghtngCstAvlFlg2 "ENM";
BA_ "SignalLongName" SG_ 1826 StBltTghtngCstAvlFlg2 "Seat Belt Tightening Customization Availability Flag 2";
BA_ "SignalType" SG_ 1826 TrlrMirVidEnblCstAvlFlg3 "ENM";
BA_ "SignalLongName" SG_ 1826 TrlrMirVidEnblCstAvlFlg3 "Trailering Mirror Video Enable Customization Availability Flag 3";
BA_ "SignalType" SG_ 1826 TrlrMirVidEnblCstAvlFlg2 "ENM";
BA_ "SignalLongName" SG_ 1826 TrlrMirVidEnblCstAvlFlg2 "Trailering Mirror Video Enable Customization Availability Flag 2";
BA_ "SignalType" SG_ 1826 TrlrMirVidEnblCstAvlFlg1 "ENM";
BA_ "SignalLongName" SG_ 1826 TrlrMirVidEnblCstAvlFlg1 "Trailering Mirror Video Enable Customization Availability Flag 1";
BA_ "SignalType" SG_ 1826 TnDrvStBltShfIntlkCstAvlFlg7 "ENM";
BA_ "SignalLongName" SG_ 1826 TnDrvStBltShfIntlkCstAvlFlg7 "Teen Driver Seat Belt Shift Interlock Customization Availability Flag7";
BA_ "SignalType" SG_ 1826 TnDrvStBltShfIntlkCstAvlFlg6 "ENM";
BA_ "SignalLongName" SG_ 1826 TnDrvStBltShfIntlkCstAvlFlg6 "Teen Driver Seat Belt Shift Interlock Customization Availability Flag6";
BA_ "SignalType" SG_ 1826 TnDrvStBltShfIntlkCstAvlFlg5 "ENM";
BA_ "SignalLongName" SG_ 1826 TnDrvStBltShfIntlkCstAvlFlg5 "Teen Driver Seat Belt Shift Interlock Customization Availability Flag5";
BA_ "SignalType" SG_ 1826 TnDrvStBltShfIntlkCstAvlFlg4 "ENM";
BA_ "SignalLongName" SG_ 1826 TnDrvStBltShfIntlkCstAvlFlg4 "Teen Driver Seat Belt Shift Interlock Customization Availability Flag4";
BA_ "SignalType" SG_ 1826 TnDrvStBltShfIntlkCstAvlFlg3 "ENM";
BA_ "SignalLongName" SG_ 1826 TnDrvStBltShfIntlkCstAvlFlg3 "Teen Driver Seat Belt Shift Interlock Customization Availability Flag3";
BA_ "SignalType" SG_ 1826 TrlrMirVidGdlnsCstAvlFlg4 "ENM";
BA_ "SignalLongName" SG_ 1826 TrlrMirVidGdlnsCstAvlFlg4 "Trailering Mirror Video Guidelines Customization Availability Flag 4";
BA_ "SignalType" SG_ 1826 TrlrMirVidGdlnsCstAvlFlg3 "ENM";
BA_ "SignalLongName" SG_ 1826 TrlrMirVidGdlnsCstAvlFlg3 "Trailering Mirror Video Guidelines Customization Availability Flag 3";
BA_ "SignalType" SG_ 1826 TrlrMirVidGdlnsCstAvlFlg2 "ENM";
BA_ "SignalLongName" SG_ 1826 TrlrMirVidGdlnsCstAvlFlg2 "Trailering Mirror Video Guidelines Customization Availability Flag 2";
BA_ "SignalType" SG_ 1826 TrlrMirVidGdlnsCstAvlFlg1 "ENM";
BA_ "SignalLongName" SG_ 1826 TrlrMirVidGdlnsCstAvlFlg1 "Trailering Mirror Video Guidelines Customization Availability Flag 1";
BA_ "SignalType" SG_ 1826 TrlrMirVidEnblCstAvlFlg7 "ENM";
BA_ "SignalLongName" SG_ 1826 TrlrMirVidEnblCstAvlFlg7 "Trailering Mirror Video Enable Customization Availability Flag 7";
BA_ "SignalType" SG_ 1826 TrlrMirVidEnblCstAvlFlg6 "ENM";
BA_ "SignalLongName" SG_ 1826 TrlrMirVidEnblCstAvlFlg6 "Trailering Mirror Video Enable Customization Availability Flag 6";
BA_ "SignalType" SG_ 1826 TrlrMirVidEnblCstAvlFlg5 "ENM";
BA_ "SignalLongName" SG_ 1826 TrlrMirVidEnblCstAvlFlg5 "Trailering Mirror Video Enable Customization Availability Flag 5";
BA_ "SignalType" SG_ 1826 TrlrMirVidEnblCstAvlFlg4 "ENM";
BA_ "SignalLongName" SG_ 1826 TrlrMirVidEnblCstAvlFlg4 "Trailering Mirror Video Enable Customization Availability Flag 4";
BA_ "SignalType" SG_ 1826 CrshEvntEnbld "ENM";
BA_ "SignalLongName" SG_ 1826 CrshEvntEnbld "Crash Event Enabled";
BA_ "SignalType" SG_ 1826 TmngBltChgIndOn "ENM";
BA_ "SignalLongName" SG_ 1826 TmngBltChgIndOn "Timing Belt Change Indication On";
BA_ "SignalType" SG_ 1826 TrnsOlTmpSnsPrs "ENM";
BA_ "SignalLongName" SG_ 1826 TrnsOlTmpSnsPrs "Transmission Oil Temperature Sensor Present";
BA_ "SignalType" SG_ 1826 TrlrMirVidGdlnsCstAvlFlg7 "ENM";
BA_ "SignalLongName" SG_ 1826 TrlrMirVidGdlnsCstAvlFlg7 "Trailering Mirror Video Guidelines Customization Availability Flag 7";
BA_ "SignalType" SG_ 1826 TrlrMirVidGdlnsCstAvlFlg6 "ENM";
BA_ "SignalLongName" SG_ 1826 TrlrMirVidGdlnsCstAvlFlg6 "Trailering Mirror Video Guidelines Customization Availability Flag 6";
BA_ "SignalType" SG_ 1826 TrlrMirVidGdlnsCstAvlFlg5 "ENM";
BA_ "SignalLongName" SG_ 1826 TrlrMirVidGdlnsCstAvlFlg5 "Trailering Mirror Video Guidelines Customization Availability Flag 5";
BA_ "SignalLongName" SG_ 1421 CSI_PV "Chime Status Information : Protection Value";
BA_ "SignalType" SG_ 1421 CSI_ChmPrdcrSOH "ENM";
BA_ "SignalLongName" SG_ 1421 CSI_ChmPrdcrSOH "Chime Status Information : Chime Producer State of Health";
BA_ "SignalLongName" SG_ 1421 CSI_ARC "Chime Status Information : Alive Rolling Count";
BA_ "SignalType" SG_ 1514 ClstrDspAnmReq "ENM";
BA_ "SignalLongName" SG_ 1514 ClstrDspAnmReq "Cluster Display Animation Request";
BA_ "SignalLongName" SG_ 1253 OATDispdVal "Outside Air Temperature Displayed Value";
BA_ "SignalType" SG_ 1253 OATDispdVal_DuD "ENM";
BA_ "SignalLongName" SG_ 1253 OATDispdVal_DuD "Outside Air Temperature Displayed Value Don't Use Data";
BA_ "SignalType" SG_ 1253 IPC_LCMDataMsgStat "ENM";
BA_ "SignalLongName" SG_ 1253 IPC_LCMDataMsgStat "IPC_LCMDataMessageStatus";
BA_ "SignalType" SG_ 1253 IPC_LCMFileTrans "ENM";
BA_ "SignalLongName" SG_ 1253 IPC_LCMFileTrans "IPC_LCMFileTransfer";
BA_ "SignalLongName" SG_ 935 InfoAuxBrightnessLvl "Infotainment Auxiliary Brightness Level";
BA_ "SignalLongName" SG_ 935 InfoBklghtBrightnessLvl "Infotainment Backlight Brightness Level";
BA_ "SignalLongName" SG_ 935 InfoDispBrightnessLvl "Infotainment Display Brightness Level";
BA_ "SignalType" SG_ 1422 HVACICRTLR_LtLvlActv "ENM";
BA_ "SignalLongName" SG_ 1422 HVACICRTLR_LtLvlActv "HVAC Infotainment Controls Request Temperature Level Rear : Left Level Active";
BA_ "SignalLongName" SG_ 1422 HVACICRTLR_LtLvl "HVAC Infotainment Controls Request Temperature Level Rear : Left Level";
BA_ "SignalType" SG_ 1422 HVACICRTLR_RtLvlActv "ENM";
BA_ "SignalLongName" SG_ 1422 HVACICRTLR_RtLvlActv "HVAC Infotainment Controls Request Temperature Level Rear : Right Level Active";
BA_ "SignalLongName" SG_ 1422 HVACICRTLR_RtLvl "HVAC Infotainment Controls Request Temperature Level Rear : Right Level";
BA_ "SignalLongName" SG_ 1422 ChmPrdcrStat "Chime Producer Status";
BA_ "SignalType" SG_ 1422 HVACICRADSR_LtSet "ENM";
BA_ "SignalLongName" SG_ 1422 HVACICRADSR_LtSet "HVAC Infotainment Controls Request Air Distribution Setting Rear : Left Setting";
BA_ "SignalLongName" SG_ 1422 HVACICRTLCR_RtLvlChg "HVAC Infotainment Controls Request Temperature Level Change Rear : Right Level Change";
BA_ "SignalLongName" SG_ 1422 HVACICRTLCR_LtLvlChg "HVAC Infotainment Controls Request Temperature Level Change Rear : Left Level Change";
BA_ "SignalType" SG_ 1422 HVACICRADSR_RtSet "ENM";
BA_ "SignalLongName" SG_ 1422 HVACICRADSR_RtSet "HVAC Infotainment Controls Request Air Distribution Setting Rear : Right Setting";
BA_ "SignalLongName" SG_ 1422 HVACICRBLR_Lvl "HVAC Infotainment Controls Request Blower Level Rear : Level";
BA_ "SignalLongName" SG_ 1422 HVACInfoCtlReqBlwLvlChgRr "HVAC Infotainment Controls Request Blower Level Change Rear";
BA_ "SignalType" SG_ 1422 HVACInfoCtlReqRrDfgSet "ENM";
BA_ "SignalLongName" SG_ 1422 HVACInfoCtlReqRrDfgSet "HVAC Infotainment Controls Request Rear Defog Setting";
BA_ "SignalType" SG_ 1422 HVACInfoCtlReqSyncSet "ENM";
BA_ "SignalLongName" SG_ 1422 HVACInfoCtlReqSyncSet "HVAC Infotainment Controls Request Sync Setting";
BA_ "SignalType" SG_ 1422 HVACICRBLR_LvlActv "ENM";
BA_ "SignalLongName" SG_ 1422 HVACICRBLR_LvlActv "HVAC Infotainment Controls Request Blower Level Rear : Level Active";
BA_ "SignalType" SG_ 1422 HVACInfoCtlReqRrPwrSetChg "ENM";
BA_ "SignalLongName" SG_ 1422 HVACInfoCtlReqRrPwrSetChg "HVAC Infotainment Controls Request Rear Power Setting Change";
BA_ "SignalType" SG_ 1422 HVACInfoCtlReqRrLckSetChg "ENM";
BA_ "SignalLongName" SG_ 1422 HVACInfoCtlReqRrLckSetChg "HVAC Infotainment Controls Request Rear Lock Setting Change";
BA_ "SignalType" SG_ 1422 HVACInfoCtlReqRrDfgSetChg "ENM";
BA_ "SignalLongName" SG_ 1422 HVACInfoCtlReqRrDfgSetChg "HVAC Infotainment Controls Request Rear Defog Setting Change";
BA_ "SignalType" SG_ 1422 HVACInfoCtlReqRrAutoSetChg "ENM";
BA_ "SignalLongName" SG_ 1422 HVACInfoCtlReqRrAutoSetChg "HVAC Infotainment Controls Request Rear Auto Setting Change";
BA_ "SignalType" SG_ 1422 HVACInfoCtlReqBlwSpdRdct "ENM";
BA_ "SignalLongName" SG_ 1422 HVACInfoCtlReqBlwSpdRdct "HVAC Infotainment Controls Request Blower Speed Reduction";
BA_ "SignalType" SG_ 1422 HVACICRADSCR_RtChgNext "ENM";
BA_ "SignalLongName" SG_ 1422 HVACICRADSCR_RtChgNext "HVAC Infotainment Controls Request Air Distribution Setting Change Rear : Right Change Next";
BA_ "SignalType" SG_ 1422 HVACICRADSCR_LtChgNext "ENM";
BA_ "SignalLongName" SG_ 1422 HVACICRADSCR_LtChgNext "HVAC Infotainment Controls Request Air Distribution Setting Change Rear : Left Change Next";
BA_ "SignalLongName" SG_ 1423 VirtKeyPinToStrtCustEntdPINDgt1 "Virtual Key Pin To Start Customer Entered PIN : Virtual Key Pin To Start Customer Entered PIN Digit 1";
BA_ "SignalType" SG_ 1423 VirtKeyPinToStrtFobNDtd "ENM";
BA_ "SignalLongName" SG_ 1423 VirtKeyPinToStrtFobNDtd "Virtual Key Pin To Start Fob Not Detected";
BA_ "SignalType" SG_ 1423 ChrgCommCtlrCommEnblSts "ENM";
BA_ "SignalLongName" SG_ 1423 ChrgCommCtlrCommEnblSts "Charging Communication Controller Communication Enable Status";
BA_ "SignalType" SG_ 1423 HVACInfoCtlReqSyncRrSetChg "ENM";
BA_ "SignalLongName" SG_ 1423 HVACInfoCtlReqSyncRrSetChg "HVAC Infotainment Controls Request Sync Rear Setting Change";
BA_ "SignalType" SG_ 1423 HVACInfoCtlReqSyncAllSetChg "ENM";
BA_ "SignalLongName" SG_ 1423 HVACInfoCtlReqSyncAllSetChg "HVAC Infotainment Controls Request Sync All Setting Change";
BA_ "SignalLongName" SG_ 1423 VirtKeyPinToStrtCustEntdPINDgt3 "Virtual Key Pin To Start Customer Entered PIN : Virtual Key Pin To Start Customer Entered PIN Digit 3";
BA_ "SignalLongName" SG_ 1423 VirtKeyPinToStrtCustEntdPINDgt2 "Virtual Key Pin To Start Customer Entered PIN : Virtual Key Pin To Start Customer Entered PIN Digit 2";
BA_ "SignalLongName" SG_ 1423 VirtKeyPinToStrtCustEntdPINDgt5 "Virtual Key Pin To Start Customer Entered PIN : Virtual Key Pin To Start Customer Entered PIN Digit 5";
BA_ "SignalLongName" SG_ 1423 VirtKeyPinToStrtCustEntdPINDgt4 "Virtual Key Pin To Start Customer Entered PIN : Virtual Key Pin To Start Customer Entered PIN Digit 4";
BA_ "SignalLongName" SG_ 1423 VirtKeyPinToStrtCustEntdPINDgt6 "Virtual Key Pin To Start Customer Entered PIN : Virtual Key Pin To Start Customer Entered PIN Digit 6";
VAL_ 1485 FourWhlDrvWrnIndReq 0 "No Action" 1 "No Indication" 2 "For 4WD Low Shift Transmission To Neutral" 3 "To Exit 4WD Low Shift Transmission to Neutral" 4 "For 4WD Low Reduce Speed" 5 "To Exit 4WD Low Reduce Speed" 6 "Reminder Vehicle Still In 4WD Low" 7 "4WD Shift in Progress" 8 "4WD Shift Not Allowed Engine Warming Up" 9 "4WD Shift Not Allowed Mismatched Tire" 10 "4WD Shift Not Allowed In Park" 11 "Apply Brake For 4WD Shift" 12 "No 4WD Shifts Allowed" 13 "Reduce Speed For 4WD Shift" 14 "Turn off Engine for 4WD Shift" 15 "For 4WD Shift Transmission Neutral" ;
VAL_ 1485 PAVisObjIndStatReq 0 "No Action" 1 "Driver Tube Front" 2 "Driver Tube Rear" 3 "Full Active" ;
VAL_ 1485 SAP_SecAxl4WDAWDEstTrqAuth_Inv 0 "FALSE" 1 "TRUE" ;
VAL_ 1485 EDADS_CrntFwdMsdGr 0 "None" 1 "First Gear" 2 "Second Gear" 3 "Third Gear" 4 "Fourth Gear" 5 "Fifth Gear" 6 "Sixth Gear" 7 "Seventh Gear" 8 "Eighth Gear" 9 "Ninth Gear" 10 "Tenth Gear" 11 "Unused" 12 "Unused" 13 "Unused" 14 "Unused" 15 "Unused" ;
VAL_ 1485 EDADS_ShftIndSt 0 "Shift Down" 1 "Shift Up" 2 "No Shift" ;
VAL_ 1485 EDADS_RcmndtFwdGr 0 "None" 1 "First Gear" 2 "Second Gear" 3 "Third Gear" 4 "Fourth Gear" 5 "Fifth Gear" 6 "Sixth Gear" 7 "Seventh Gear" 8 "Eighth Gear" 9 "Ninth Gear" 10 "Tenth Gear" 11 "Unused" 12 "Unused" 13 "Unused" 14 "Unused" 15 "Unused" ;
VAL_ 1485 EDADS_EcoDrvShftIO 0 "FALSE" 1 "TRUE" ;
VAL_ 1485 PAIM_SnsrDstbdIndOn 0 "FALSE" 1 "TRUE" ;
VAL_ 1485 PAIM_SnsrClnIndOn 0 "FALSE" 1 "TRUE" ;
VAL_ 1485 PAIM_SnsrBlckdIndOn 0 "FALSE" 1 "TRUE" ;
VAL_ 1485 PAIM_RrOffIndOn 0 "FALSE" 1 "TRUE" ;
VAL_ 1485 PAIM_OffIndOn 0 "FALSE" 1 "TRUE" ;
VAL_ 1485 PAIM_FrtOffIndOn 0 "FALSE" 1 "TRUE" ;
VAL_ 1485 PAIM_FaildIndOn 0 "FALSE" 1 "TRUE" ;
VAL_ 1485 PAIM_DsbldIndOn 0 "FALSE" 1 "TRUE" ;
VAL_ 1485 PAIM_TeenDrvrPAOffUnvIndOn 0 "FALSE" 1 "TRUE" ;
VAL_ 1486 VwgVwprtReq 0 "Unknown" 1 "Front Perspective" 2 "Front Junction" 3 "Front Overhead" 4 "Side Forward" 5 "Rear Perspective" 6 "Rear Junction" 7 "Rear Overhead" 8 "Side Rearward" 9 "Bowl" 10 "Zoomed Bowl" 11 "Japan" 12 "Rear Hitch" 13 "Bed Hitch" 14 "Trailer Aux1" 15 "Trailer Towing Mirror" 16 "L R Trailer Towing Mirror" 17 "Trailer Aux1 Combined" 18 "Trailer Aux2" 19 "Invisible Trailer" 20 "Cargo Bed" 21 "Curb Overhead" 22 "Curb" 23 "No Request" 24 "Transparent Hood" ;
VAL_ 1486 SAP_SecAxlOpMdAuth 0 "2WD High" 1 "4WD High Rigid Coupling" 2 "4WD Low Rigid Coupling" 3 "AWD Active Single Clutch" 4 "4WD High Active Clutch" 5 "4WD Low Active Clutch" 6 "AWD Active Twin Clutch" 7 "2WD Low" 8 "Unknown" 9 "Neutral" ;
VAL_ 1486 SAP_SecAxlOpMdAuth_Inv 0 "FALSE" 1 "TRUE" ;
VAL_ 1486 EnrgMgtLdShdRq 0 "No Load Shedding" 1 "Load Shed Level 1" 2 "Load Shed Level 2" 3 "Load Shed Level 3" 4 "Load Shed Level 4" ;
VAL_ 1486 VwgVwprtSts 0 "Unknown" 1 "Front Perspective" 2 "Front Junction" 3 "Front Overhead" 4 "Side Forward" 5 "Rear Perspective" 6 "Rear Junction" 7 "Rear Overhead" 8 "Side Rearward" 9 "Bowl" 10 "Zoomed Bowl" 11 "Japan" 12 "Rear Hitch" 13 "Bed Hitch" 14 "Trailer Aux1" 15 "Trailer Towing Mirror" 16 "L R Trailer Towing Mirror" 17 "Trailer Aux1 Combined" 18 "Trailer Aux2" 19 "Invisible Trailer" 20 "Cargo Bed" 21 "Curb Overhead" 22 "Curb" 23 "No Request" 24 "Transparent Hood" ;
VAL_ 1486 MemCmd 0 "No Operation Required" 1 "Store Mem 1 (Button Mem 1)" 2 "Store Mem 2(Button Mem 2)" 3 "Store Mem 3 (Button Mem 3)" 4 "Store Mem EXIT (Button Mem Exit)" 5 "Recall Mem 1 (Button Mem 1)" 6 "Recall Mem 2 (Button Mem 2)" 7 "Recall Mem 3 (Button Mem 3)" 8 "Recall Mem EXIT (Button Mem Exit)" 9 "Stop All Movement" 10 "RESERVED_10" 11 "RESERVED_11" 12 "RESERVED_12" 13 "RESERVED_13" 14 "RESERVED_14" 15 "RESERVED_15" ;
VAL_ 1486 FrntPsStbltRmIndReq 0 "OFF" 1 "ON" 2 "0.5_Hz" 3 "1_Hz" 4 "2_Hz" 5 "4_Hz" 6 "RESERVED_1" 7 "RESERVED_2" ;
VAL_ 1486 TireLFLoTracIndOn 0 "FALSE" 1 "TRUE" ;
VAL_ 1486 MemIdfrIgnOnIndReq 0 "No Action" 1 "Driver 1" 2 "Driver 2" 3 "Driver 3" 4 "Driver 4" 5 "Driver 5" 6 "Driver 6" 7 "Driver 7" 8 "Driver 8" ;
VAL_ 1486 AutMemRclCstCurSetVal 0 "SETTING_UNKNOWN" 1 "OFF" 2 "ON" 3 "AUTO_MEMORY_RECALL" 4 "EASY_EXIT" 5 "AUTO_MEMORY_AND EASY_EXIT_RECALLS" 6 "RESERVED_7" ;
VAL_ 1486 AdpLghtRspTypCstCurSetVal 0 "SETTING_UNKNOWN" 1 "OFF" 2 "CORNER_AND_CURVE_LIGHTING" 3 "INTELLIGENT_LIGHT_DISTRIBUTION" 4 "INTELLIGENT_LIGHT_DISTRIBUTION_GPS_ASSISTANCE" 5 "RESERVED_5" 6 "RESERVED_6" 7 "RESERVED_7" ;
VAL_ 1486 TireRRLoTracIndOn 0 "FALSE" 1 "TRUE" ;
VAL_ 1486 TireRFLoTracIndOn 0 "FALSE" 1 "TRUE" ;
VAL_ 1486 TireLRLoTracIndOn 0 "FALSE" 1 "TRUE" ;
VAL_ 1486 AutMemRclCstStAvl 0 "FALSE" 1 "TRUE" ;
VAL_ 1486 CTDStat 0 "OFF" 1 "ARMED" 2 "DISARMED" 3 "ALARM ACTIVE" 4 "ARMING DELAY" 5 "POST ALARM DELAY" ;
VAL_ 1486 BrkSysHillStrtAsstStat 0 "Inactive" 1 "Brake Pressure Hold" 2 "Normal Pressure Decay" 3 "Drive-off Pressure Decay" 4 "Reserved_4" 5 "Reserved_5" 6 "Reserved_6" 7 "Reserved_7" ;
VAL_ 1487 CnvtblTpWndMtnReq 0 "NO_ACTION" 1 "OPEN" 2 "CLOSE" 3 "COMFORT_OPEN" 4 "COMFORT_CLOSE" ;
VAL_ 1487 CnvtBkWndPstnSts 0 "Denormalized" 1 "Fully Closed" 2 "Less Than Position A" 3 "Position A" 4 "Greater Than A but less than Position C" 5 "Position C" 6 "Greater than Position C but less than Fully open" 7 "Fully Open" ;
VAL_ 1487 CTGI2P_CnvtTopStsAuth 0 "Indeterminate" 1 "Fully Closed" 2 "Fully Open" 3 "Closing" 4 "Opening" 5 "Halted" ;
VAL_ 1487 FrntPsStBltRmOccStat_Inv 0 "FALSE" 1 "TRUE" ;
VAL_ 1487 EsyExtCstCurSetVal 0 "SETTING_UNKNOWN" 1 "OFF" 2 "ON" 3 "RESERVED_3" 4 "RESERVED_4" 5 "RESERVED_5" 6 "RESERVED_6" 7 "RESERVED_7" ;
VAL_ 1487 CrgBedVwAutoLgtCstCurrSetVal 0 "Setting_Unknown" 1 "Off" 2 "On" 3 "Reserved_3" 4 "Reserved_4" 5 "Reserved_5" 6 "Reserved_6" 7 "Reserved_7" ;
VAL_ 1487 FrwdVhImAlrtIndRqst 0 "OFF" 1 "ON" 2 "0.5_Hz" 3 "1_Hz" 4 "2_Hz" 5 "4_Hz" 6 "RESERVED_1" 7 "RESERVED_2" ;
VAL_ 1487 FrtRdHgtGPSCstCurrSetVal 0 "SETTING_UNKNOWN" 1 "OFF" 2 "ON" 3 "RESERVED_3" 4 "RESERVED_4" 5 "RESERVED_5" 6 "RESERVED_6" 7 "RESERVED_7" ;
VAL_ 1487 FrntPsStBltRmOccStat 0 "UNKNOWN" 1 "EMPTY" 2 "OCCUPIED" ;
VAL_ 1487 HybStatElecVehModeOvrrd 0 "Undetermined" 1 "No Override" 2 "Too Cold" 3 "Battery Low" 4 "Speed too High" 5 "Generic Override" 6 "Grade too High" 7 "Accelerator Pedal Threshold Exceeded" ;
VAL_ 1487 HSP_DrvAlrtTypCstCurrSetValAuth 0 "SETTING_UNKNOWN" 1 "CHIME" 2 "SEAT" ;
VAL_ 1487 GoNotfrCstCrStVal 0 "SETTING_UNKNOWN" 1 "OFF" 2 "ON" 3 "RESERVED_3" 4 "RESERVED_4" 5 "RESERVED_5" 6 "RESERVED_6" 7 "RESERVED_7" ;
VAL_ 1487 LtRtHnTrCstCurSetVal 0 "SETTING_UNKNOWN" 1 "LEFT_HAND_DRIVE" 2 "RIGHT_HAND_DRIVE" 3 "AUTOMATIC_WITH_GPS" 4 "RESERVED_4" 5 "RESERVED_5" 6 "RESERVED_6" 7 "RESERVED_7" ;
VAL_ 1487 LnDtWrnCntrlFtrSt 0 "OFF" 1 "STANDBY" 2 "READY TO ASSIST" 3 "FAILED" 4 "ALERT AND CONTROL" ;
VAL_ 1487 JckKnfDtnCstCurrSetVal 0 "Setting_Unknown" 1 "Off" 2 "On" 3 "Reserved_3" 4 "Reserved_4" 5 "Reserved_5" 6 "Reserved_6" 7 "Reserved_7" ;
VAL_ 1487 LvlgSysEntEgrsMdCstCurrSetVal 0 "SETTING_UNKNOWN" 1 "OFF" 2 "ON" 3 "RESERVED_3" 4 "RESERVED_4" 5 "RESERVED_5" 6 "RESERVED_6" 7 "RESERVED_7" ;
VAL_ 1487 LvlgSysAlgnMdCstCurrSetVal 0 "SETTING_UNKNOWN" 1 "OFF" 2 "ON" 3 "RESERVED_3" 4 "RESERVED_4" 5 "RESERVED_5" 6 "RESERVED_6" 7 "RESERVED_7" ;
VAL_ 1487 PrkAsstONOFFCstCrStVal 0 "SETTING_UNKNOWN" 1 "OFF" 2 "ALERT" 3 "ALERT_BRAKE" 4 "RESERVED_4" 5 "RESERVED_5" 6 "RESERVED_6" 7 "RESERVED_7" ;
VAL_ 1487 NghtVsnSysStat 0 "UNKNOWN" 1 "INITIALIZING" 2 "INACTIVE" 3 "ACTIVE" 4 "NEEDS SERVICE" 5 "NOT DARK" 6 "TEMPORARILY UNAVAILABLE" 7 "NEEDS HEADLIGHTS" ;
VAL_ 1487 LvlgSysServMdCstCurrSetVal 0 "SETTING_UNKNOWN" 1 "OFF" 2 "ON" 3 "RESERVED_3" 4 "RESERVED_4" 5 "RESERVED_5" 6 "RESERVED_6" 7 "RESERVED_7" ;
VAL_ 1487 AutoHldEnbld 0 "FALSE" 1 "TRUE" ;
VAL_ 1487 PrkAsstTrHtchPsntCstCrStVal 0 "SETTING_UNKNOWN" 1 "OFF_NOT_ATTACHED" 2 "ON_ATTACHED" 3 "RESERVED_3" 4 "RESERVED_4" 5 "RESERVED_5" 6 "RESERVED_6" 7 "RESERVED_7" ;
VAL_ 1487 PrkAsstStat 0 "OFF" 1 "STANDBY" 2 "DISABLED" 3 "FAILED" 4 "FRONT_REAR_ACTIVE" 5 "REAR_ACTIVE" 6 "FRONT_ACTIVE" 7 "UNKNOWN" ;
VAL_ 1488 PrsnlMdStrCstmCurSetVal 0 "SETTING_UNKNOWN" 1 "PERSONAL_MODE_1" 2 "PERSONAL_MODE_2" 3 "PERSONAL_MODE_3" 4 "PERSONAL_MODE_4" 5 "PERSONAL_MODE_5" 6 "PERSONAL_MODE_6" 7 "PERSONAL_MODE_7" ;
VAL_ 1488 PrsnlMdSpnCstmCurSetVal 0 "SETTING_UNKNOWN" 1 "PERSONAL_MODE_1" 2 "PERSONAL_MODE_2" 3 "PERSONAL_MODE_3" 4 "PERSONAL_MODE_4" 5 "PERSONAL_MODE_5" 6 "PERSONAL_MODE_6" 7 "PERSONAL_MODE_7" ;
VAL_ 1488 PrsnlMdSndCstmCurSetVal 0 "SETTING_UNKNOWN" 1 "PERSONAL_MODE_1" 2 "PERSONAL_MODE_2" 3 "PERSONAL_MODE_3" 4 "PERSONAL_MODE_4" 5 "PERSONAL_MODE_5" 6 "PERSONAL_MODE_6" 7 "PERSONAL_MODE_7" ;
VAL_ 1488 RideHghtSeltn3Name 0 "No Action" 1 "Auto" 2 "Raised 2" 3 "Raised" 4 "Normal" 5 "Entry/Exit" 6 "Cargo/Trailer" 7 "Lowered" ;
VAL_ 1488 RideHghtSeltn2Name 0 "No Action" 1 "Auto" 2 "Raised 2" 3 "Raised" 4 "Normal" 5 "Entry/Exit" 6 "Cargo/Trailer" 7 "Lowered" ;
VAL_ 1488 RideHghtSeltn1Name 0 "No Action" 1 "Auto" 2 "Raised 2" 3 "Raised" 4 "Normal" 5 "Entry/Exit" 6 "Cargo/Trailer" 7 "Lowered" ;
VAL_ 1488 RideHghtSeltn5Name 0 "No Action" 1 "Auto" 2 "Raised 2" 3 "Raised" 4 "Normal" 5 "Entry/Exit" 6 "Cargo/Trailer" 7 "Lowered" ;
VAL_ 1488 RideHghtSeltn4Name 0 "No Action" 1 "Auto" 2 "Raised 2" 3 "Raised" 4 "Normal" 5 "Entry/Exit" 6 "Cargo/Trailer" 7 "Lowered" ;
VAL_ 1488 RideHghtSeltn8Name 0 "No Action" 1 "Auto" 2 "Raised 2" 3 "Raised" 4 "Normal" 5 "Entry/Exit" 6 "Cargo/Trailer" 7 "Lowered" ;
VAL_ 1488 RideHghtSeltn7Name 0 "No Action" 1 "Auto" 2 "Raised 2" 3 "Raised" 4 "Normal" 5 "Entry/Exit" 6 "Cargo/Trailer" 7 "Lowered" ;
VAL_ 1488 RideHghtSeltn6Name 0 "No Action" 1 "Auto" 2 "Raised 2" 3 "Raised" 4 "Normal" 5 "Entry/Exit" 6 "Cargo/Trailer" 7 "Lowered" ;
VAL_ 1488 RrVwPrkAstSymCsCrStVal 0 "SETTING_UNKNOWN" 1 "OFF" 2 "ON" 3 "RESERVED_3" 4 "RESERVED_4" 5 "RESERVED_5" 6 "RESERVED_6" 7 "RESERVED_7" ;
VAL_ 1488 RnngBrdManDplyCstCurrSetVal 0 "Setting_Unknown" 1 "Off" 2 "Extend to Door" 3 "Extend to Bed" 4 "Reserved_4" 5 "Reserved_5" 6 "Reserved_6" 7 "Reserved_7" ;
VAL_ 1488 RnngBrdAutoDplyCstCurrSetVal 0 "Setting_Unknown" 1 "Off" 2 "Door" 3 "Door_Park" 4 "Reserved_5" 5 "Reserved_6" 6 "Reserved_7" ;
VAL_ 1488 StBltShfIntlkCstCurrSetVal 0 "SETTING_UNKNOWN" 1 "OFF" 2 "ON" 3 "RESERVED_3" 4 "RESERVED_4" 5 "RESERVED_5" 6 "RESERVED_6" 7 "RESERVED_7" ;
VAL_ 1488 SrrndVwLghtCsCrStVal 0 "SETTING_UNKNOWN" 1 "OFF" 2 "ON" 3 "RESERVED_3" 4 "RESERVED_4" 5 "RESERVED_5" 6 "RESERVED_6" 7 "RESERVED_7" ;
VAL_ 1488 TrlrMirVidGdlnsCstCurrSetVal 0 "Setting_Unknown" 1 "Off" 2 "On" 3 "Reserved_3" 4 "Reserved_4" 5 "Reserved_5" 6 "Reserved_6" 7 "Reserved_7" ;
VAL_ 1488 TnDrvStBltShfIntlkCstCurrSetVal 0 "SETTING_UNKNOWN" 1 "OFF" 2 "ON" 3 "RESERVED_3" 4 "RESERVED_4" 5 "RESERVED_5" 6 "RESERVED_6" 7 "RESERVED_7" ;
VAL_ 1488 StBltTghtngCstCrStVal 0 "SETTING_UNKNOWN" 1 "OFF" 2 "ON" 3 "RESERVED_3" 4 "RESERVED_4" 5 "RESERVED_5" 6 "RESERVED_6" 7 "RESERVED_7" ;
VAL_ 1488 BrkLtsAtv 0 "FALSE" 1 "TRUE" ;
VAL_ 1488 APAExtPrkSftBtnRqst 0 "HIDDEN" 1 "DISABLED" 2 "ENABLED" 3 "HIGHLIGHTED" ;
VAL_ 1488 APACrssFrntInSftBtnRqst 0 "HIDDEN" 1 "DISABLED" 2 "ENABLED" 3 "HIGHLIGHTED" ;
VAL_ 1488 APACrssBckInSftBtnRqst 0 "HIDDEN" 1 "DISABLED" 2 "ENABLED" 3 "HIGHLIGHTED" ;
VAL_ 1489 APASrchSftBtnRqst 0 "HIDDEN" 1 "DISABLED" 2 "ENABLED" 3 "HIGHLIGHTED" ;
VAL_ 1489 APARghtSftBtnRqst 0 "HIDDEN" 1 "DISABLED" 2 "ENABLED" 3 "HIGHLIGHTED" ;
VAL_ 1489 APAPrllPrkSftBtnRqst 0 "HIDDEN" 1 "DISABLED" 2 "ENABLED" 3 "HIGHLIGHTED" ;
VAL_ 1489 APALftSftBtnRqst 0 "HIDDEN" 1 "DISABLED" 2 "ENABLED" 3 "HIGHLIGHTED" ;
VAL_ 1489 EngCmptAjr 0 "FALSE" 1 "TRUE" ;
VAL_ 1489 EngCmptAjr_Inv 0 "FALSE" 1 "TRUE" ;
VAL_ 1489 ElvtdIdlCstCrStVal 0 "No Action" 1 "Off" 2 "On" ;
VAL_ 1489 DrvDrAjrStat 0 "FALSE" 1 "TRUE" ;
VAL_ 1489 DrvDrAjrStat_Inv 0 "FALSE" 1 "TRUE" ;
VAL_ 1489 CoDrvDrAjrStat 0 "FALSE" 1 "TRUE" ;
VAL_ 1489 CoDrvDrAjrStat_Inv 0 "FALSE" 1 "TRUE" ;
VAL_ 1489 LftglsAjrStat 0 "FALSE" 1 "TRUE" ;
VAL_ 1489 LftglsAjrStat_Inv 0 "FALSE" 1 "TRUE" ;
VAL_ 1489 LRDrAjrStat 0 "FALSE" 1 "TRUE" ;
VAL_ 1489 LRDrAjrStat_Inv 0 "FALSE" 1 "TRUE" ;
VAL_ 1489 InvsblTrlrOprtlSts 0 "Available" 1 "Degraded" 2 "Unavailable" 3 "Unknown" ;
VAL_ 1489 HSP_HptcStOprtlStsAuth 0 "Normal Operation" 1 "Unknown" 2 "Failed" ;
VAL_ 1489 SAP_SecAxl4WDAWDStatAuth 0 "Normal" 1 "Temporary_Limited" 2 "Temporary_Inhibit" 3 "Permanently_Failed" ;
VAL_ 1489 RRDrAjrStat 0 "FALSE" 1 "TRUE" ;
VAL_ 1489 RRDrAjrStat_Inv 0 "FALSE" 1 "TRUE" ;
VAL_ 1489 LogisticModeStatus 0 "Off" 1 "Plant" 2 "Transport Mode" 3 "Storage Mode" ;
VAL_ 1489 LnCntrEsclnSts 0 "None" 1 "Driver Not Looking to Roadway" 2 "Limited Condition" 3 "System Faulted" ;
VAL_ 1489 CIBAutoBrkReqActv 0 "FALSE" 1 "TRUE" ;
VAL_ 1489 CIBAutoBrkRelIndOn 0 "FALSE" 1 "TRUE" ;
VAL_ 1489 APAVMR_SloDnIndOn 0 "FALSE" 1 "TRUE" ;
VAL_ 1489 APAVMR_NAvalIndOn 0 "FALSE" 1 "TRUE" ;
VAL_ 1489 TrnSwAct 0 "NO_ACTIVATION" 1 "LEFT" 2 "RIGHT" ;
VAL_ 1489 TrlrTirePresProfXferSts 0 "Not Active" 1 "Completed" 2 "In Progress" 3 "Failed" ;
VAL_ 1489 CkSoftTpIO 0 "FALSE" 1 "TRUE" ;
VAL_ 1489 CkRrPrkLmpIndOn 0 "FALSE" 1 "TRUE" ;
VAL_ 1489 CkLoBmsIndOn 0 "FALSE" 1 "TRUE" ;
VAL_ 1489 CkFrtPrkLmpsIndOn 0 "FALSE" 1 "TRUE" ;
VAL_ 1489 CkFgLmpsIndOn 0 "FALSE" 1 "TRUE" ;
VAL_ 1489 CkDyTmRnngLmpsIndOn 0 "FALSE" 1 "TRUE" ;
VAL_ 1489 CkCrnrLmpsIndOn 0 "FALSE" 1 "TRUE" ;
VAL_ 1489 CkBrkLmpsIndOn 0 "FALSE" 1 "TRUE" ;
VAL_ 1489 DrMtzdStBltUnIndOn 0 "FALSE" 1 "TRUE" ;
VAL_ 1489 DrMtzdStBltFldIndOn 0 "FALSE" 1 "TRUE" ;
VAL_ 1489 DispSmrtTowVidOn 0 "FALSE" 1 "TRUE" ;
VAL_ 1489 Deg360VidFtrPrsnt 0 "FALSE" 1 "TRUE" ;
VAL_ 1489 DRLAct 0 "FALSE" 1 "TRUE" ;
VAL_ 1489 CrgBedVwAutoLgtCstSetAval 0 "FALSE" 1 "TRUE" ;
VAL_ 1489 CnvtblTopTneuAjrStat 0 "FALSE" 1 "TRUE" ;
VAL_ 1489 ClsTrnkLidIO 0 "FALSE" 1 "TRUE" ;
VAL_ 1489 FrntPsStbltRmIndOn 0 "FALSE" 1 "TRUE" ;
VAL_ 1489 FrntPsMtzdStBltUnIndOn 0 "FALSE" 1 "TRUE" ;
VAL_ 1489 FrntPsMtzdStBltFldIndOn 0 "FALSE" 1 "TRUE" ;
VAL_ 1489 EsyExtCstStAvl 0 "FALSE" 1 "TRUE" ;
VAL_ 1489 ESCLTrntheStrWheelWhlStrtgIO 0 "FALSE" 1 "TRUE" ;
VAL_ 1489 DsplyTrgVdOn 0 "FALSE" 1 "TRUE" ;
VAL_ 1489 DspFrnt360CmrON 0 "FALSE" 1 "TRUE" ;
VAL_ 1489 DrvStBltRmIndOn 0 "FALSE" 1 "TRUE" ;
VAL_ 1490 JckKnfDtnCstSetAval 0 "FALSE" 1 "TRUE" ;
VAL_ 1490 HiBmOtgIndOn 0 "FALSE" 1 "TRUE" ;
VAL_ 1490 HSP_HptcStPrsntAuth 0 "FALSE" 1 "TRUE" ;
VAL_ 1490 GrdBrkgAct 0 "FALSE" 1 "TRUE" ;
VAL_ 1490 GoNotfrCstStAvl 0 "FALSE" 1 "TRUE" ;
VAL_ 1490 FrwdVhHdwyAlrtIndOn 0 "FALSE" 1 "TRUE" ;
VAL_ 1490 FrtStrgeCmptAjr 0 "FALSE" 1 "TRUE" ;
VAL_ 1490 FrtRdHgtGPSCstSetAval 0 "FALSE" 1 "TRUE" ;
VAL_ 1490 LvlgSysEntEgrsMdCstSetAval 0 "FALSE" 1 "TRUE" ;
VAL_ 1490 LvlgSysAlgnMdCstSetSelable 0 "FALSE" 1 "TRUE" ;
VAL_ 1490 LvlgSysAlgnMdCstSetAval 0 "FALSE" 1 "TRUE" ;
VAL_ 1490 LtRtHnTrCstStAvl 0 "FALSE" 1 "TRUE" ;
VAL_ 1490 LnCntrMisuseCond 0 "FALSE" 1 "TRUE" ;
VAL_ 1490 LnCntrDrvAwrIndOn 0 "FALSE" 1 "TRUE" ;
VAL_ 1490 LicLpOtIO 0 "FALSE" 1 "TRUE" ;
VAL_ 1490 LSCMBAutoBrkRlsIndOn 0 "FALSE" 1 "TRUE" ;
VAL_ 1490 PrkAsstTrHtchPsntCstStAvl 0 "FALSE" 1 "TRUE" ;
VAL_ 1490 PrkAsstONOFFCstStAvl 0 "FALSE" 1 "TRUE" ;
VAL_ 1490 PedtrnProtSysDpl 0 "FALSE" 1 "TRUE" ;
VAL_ 1490 NoSDCrdPrIndOn 0 "FALSE" 1 "TRUE" ;
VAL_ 1490 MovblTpServRqrdIO 0 "FALSE" 1 "TRUE" ;
VAL_ 1490 MovblTpNormzRqrdIO 0 "FALSE" 1 "TRUE" ;
VAL_ 1490 LvlgSysServMdCstSetSelable 0 "FALSE" 1 "TRUE" ;
VAL_ 1490 LvlgSysServMdCstSetAval 0 "FALSE" 1 "TRUE" ;
VAL_ 1490 RnngBrdAutoDplyCstSetAval 0 "FALSE" 1 "TRUE" ;
VAL_ 1490 RegVltgCtlEngyRcvryActv 0 "FALSE" 1 "TRUE" ;
VAL_ 1490 RearPsStbltVisIndMd 0 "FALSE" 1 "TRUE" ;
VAL_ 1490 RIMUnIndOn 0 "FALSE" 1 "TRUE" ;
VAL_ 1490 RIMONIndOn 0 "FALSE" 1 "TRUE" ;
VAL_ 1490 RIMOFFIndOn 0 "FALSE" 1 "TRUE" ;
VAL_ 1490 PrsnlMdStrCstmSetAv 0 "FALSE" 1 "TRUE" ;
VAL_ 1490 PrkBrkSwAtv 0 "FALSE" 1 "TRUE" ;
VAL_ 1490 RvLpOtIO 0 "FALSE" 1 "TRUE" ;
VAL_ 1490 RstrntDplyIndOn 0 "FALSE" 1 "TRUE" ;
VAL_ 1490 RrVwPrkAstSymCsStAvl 0 "FALSE" 1 "TRUE" ;
VAL_ 1490 RrFgLpOtIO 0 "FALSE" 1 "TRUE" ;
VAL_ 1490 RrAxlTmpInhIO 0 "FALSE" 1 "TRUE" ;
VAL_ 1490 RrAxlMlfIO 0 "FALSE" 1 "TRUE" ;
VAL_ 1490 RnngBrdManDplyCstSetSelbl 0 "FALSE" 1 "TRUE" ;
VAL_ 1490 RnngBrdManDplyCstSetAval 0 "FALSE" 1 "TRUE" ;
VAL_ 1490 SftTpMchnOvhtIO 0 "FALSE" 1 "TRUE" ;
VAL_ 1490 SftTpLtcIO 0 "FALSE" 1 "TRUE" ;
VAL_ 1490 ServPedtrnFrndlyAlrtIndOn 0 "FALSE" 1 "TRUE" ;
VAL_ 1490 SerRideSysIO 0 "FALSE" 1 "TRUE" ;
VAL_ 1490 SDCrdFllIndOn 0 "FALSE" 1 "TRUE" ;
VAL_ 1490 SDCrdErrIndOn 0 "FALSE" 1 "TRUE" ;
VAL_ 1490 TrlrMirVidEnblCstSetAval 0 "FALSE" 1 "TRUE" ;
VAL_ 1490 TrlrBrkDtd 0 "FALSE" 1 "TRUE" ;
VAL_ 1490 TrgrdVidRcrdrFtrPrsnt 0 "FALSE" 1 "TRUE" ;
VAL_ 1490 TnDrvStBltShfIntlkCstSetAval 0 "FALSE" 1 "TRUE" ;
VAL_ 1490 TargaTopAjrStat 0 "FALSE" 1 "TRUE" ;
VAL_ 1490 StBltTghtngCstStAv 0 "FALSE" 1 "TRUE" ;
VAL_ 1490 StBltShfIntlkCstSetAval 0 "FALSE" 1 "TRUE" ;
VAL_ 1490 SrrndVwLghtCsStAvl 0 "FALSE" 1 "TRUE" ;
VAL_ 1490 FrtStrgeCmptAjr_Inv 0 "FALSE" 1 "TRUE" ;
VAL_ 1490 WprFrActFltdStat 0 "FALSE" 1 "TRUE" ;
VAL_ 1490 TrnSigSwRtActv 0 "FALSE" 1 "TRUE" ;
VAL_ 1490 TrnSigSwLtActv 0 "FALSE" 1 "TRUE" ;
VAL_ 1490 TrlrMirVidGdlnsCstSetAval 0 "FALSE" 1 "TRUE" ;
VAL_ 1526 TireLocatnWarnEn 0 "FALSE" 1 "TRUE" ;
VAL_ 1526 TirePrsLF_Inv 0 "FALSE" 1 "TRUE" ;
VAL_ 1526 TirePrsLR_Inv 0 "FALSE" 1 "TRUE" ;
VAL_ 1526 TirePrsRF_Inv 0 "FALSE" 1 "TRUE" ;
VAL_ 1526 TirePrsStatLF 0 "Unknown" 1 "Nominal" 2 "Low - Service Now" 3 "Low" 4 "Low - Extended Mobility" 5 "High" ;
VAL_ 1526 TirePrsRR_Inv 0 "FALSE" 1 "TRUE" ;
VAL_ 1526 TirePrsStatRF 0 "Unknown" 1 "Nominal" 2 "Low - Service Now" 3 "Low" 4 "Low - Extended Mobility" 5 "High" ;
VAL_ 1526 TirePrsStatLR_Inv 0 "FALSE" 1 "TRUE" ;
VAL_ 1526 TirePrsStatLR 0 "Unknown" 1 "Nominal" 2 "Low - Service Now" 3 "Low" 4 "Low - Extended Mobility" 5 "High" ;
VAL_ 1526 TirePrsStatLF_Inv 0 "FALSE" 1 "TRUE" ;
VAL_ 1526 TirePrsStatRR_Inv 0 "FALSE" 1 "TRUE" ;
VAL_ 1526 TirePrsStatRR 0 "Unknown" 1 "Nominal" 2 "Low - Service Now" 3 "Low" 4 "Low - Extended Mobility" 5 "High" ;
VAL_ 1526 TirePrsStatRF_Inv 0 "FALSE" 1 "TRUE" ;
VAL_ 1526 ACCDsngIndOn 0 "FALSE" 1 "TRUE" ;
VAL_ 1527 TCTPIR_DrvrNtfn 0 "No Action" 1 "No Indication" 2 "Warm" 3 "Increase Speed or Apply Brake" 4 "Ready for Drive Away" 5 "Please Wait" 6 "Apply and Hold Brake" 7 "Cool Down" 8 "Creep Disabled" ;
VAL_ 1527 FPARS_Lt 0 "OFF" 1 "FAILED" 2 "BLOCKED" 3 "ATTACHED_OBJECT" 4 "NO_OBJECT" 5 "ZONE_1" 6 "ZONE_2" 7 "ZONE_3" 8 "ZONE_4" 9 "ZONE_5" 10 "ZONE_6" 11 "OFF_NO_FAULT" 12 "RESERVED_1" 13 "RESERVED_2" 14 "RESERVED_3" ;
VAL_ 1527 FPARS_Rt 0 "OFF" 1 "FAILED" 2 "BLOCKED" 3 "ATTACHED_OBJECT" 4 "NO_OBJECT" 5 "ZONE_1" 6 "ZONE_2" 7 "ZONE_3" 8 "ZONE_4" 9 "ZONE_5" 10 "ZONE_6" 11 "OFF_NO_FAULT" 12 "RESERVED_1" 13 "RESERVED_2" 14 "RESERVED_3" ;
VAL_ 1527 FPARS_LtCntr 0 "OFF" 1 "FAILED" 2 "BLOCKED" 3 "ATTACHED_OBJECT" 4 "NO_OBJECT" 5 "ZONE_1" 6 "ZONE_2" 7 "ZONE_3" 8 "ZONE_4" 9 "ZONE_5" 10 "ZONE_6" 11 "OFF_NO_FAULT" 12 "RESERVED_1" 13 "RESERVED_2" 14 "RESERVED_3" ;
VAL_ 1527 FPARS_RtCntr 0 "OFF" 1 "FAILED" 2 "BLOCKED" 3 "ATTACHED_OBJECT" 4 "NO_OBJECT" 5 "ZONE_1" 6 "ZONE_2" 7 "ZONE_3" 8 "ZONE_4" 9 "ZONE_5" 10 "ZONE_6" 11 "OFF_NO_FAULT" 12 "RESERVED_1" 13 "RESERVED_2" 14 "RESERVED_3" ;
VAL_ 1527 RdHgtWrn2IndReq 0 "No Indication" 1 "Auto Lowering" 2 "Suspension Low-Wait" 3 "Suspension Low-Caution" 4 "Suspension High" 5 "Safety Lowered" 6 "Raised 2 Inhibit 4WD" 7 "Raised 2 Inhibit Speed" 8 "Raised Inhibit Speed" 9 "Cargo Inhibit Speed" 10 "Entry Exit Pending Speed" 11 "Raised 2 Inhibit Crawl" 12 "Object Detected" 13 "SuspensionOverloaded" 14 "Lowered Inhibit DMC" 15 "Raised 2 Speed Limit Enabled" ;
VAL_ 1527 ACCHdwySttngIndOn 0 "FALSE" 1 "TRUE" ;
VAL_ 1528 EVMESS_StrtPhs 0 "No Indication" 1 "Complete" 2 "Phase 1" 3 "Phase 2" 4 "Phase 3" 5 "Skip Phase 2" ;
VAL_ 1528 EngIntAirTmp_Inv 0 "FALSE" 1 "TRUE" ;
VAL_ 1529 FrwdHdwyVisIndCtl 0 "FCA" 1 "ACC" 2 "None" ;
VAL_ 1529 FCA_ACCGapSetIndOn 0 "FALSE" 1 "TRUE" ;
VAL_ 1529 FCAACCGapSeltn 0 "Far" 1 "Medium" 2 "Near" 3 "Off" 4 "Unknown" ;
VAL_ 1529 ACCTrlrGapSetIndOn 0 "FALSE" 1 "TRUE" ;
VAL_ 1529 LnCntrCnvMsgIndRqst 0 "No Indication" 1 "Behind Slow Vehicle" 2 "Being Passed on Left" 3 "Being Passed on Right" 4 "Tailgater Detected" 5 "Left Blind Spot Occupied" 6 "Right Blind Spot Occupied" 7 "Heavy Traffic" 8 "Merging Vehicle" 9 "Slow Moving Traffic in Left Lane" 10 "Slow Moving Traffic Ahead" 11 "Slow Moving Traffic in Right Lane" 12 "Major Road Interchange Ahead" 13 "Road Exit Detected Ahead" 14 "Exit Only Lane Ahead" 15 "Lane Ending Ahead" 16 "Road Detour Detected" 17 "Take Time to Look at Road" 18 "Show Fuel Level" 19 "Show Fuel Range Normal" 20 "Show Fuel Range Low" 21 "Take Steering Active With Muting" ;
VAL_ 1529 FllwgTmDsplyMd 0 "NO DISPLAY" 1 "DEFAULT" 2 "NORMAL" 3 "LESS THAN MINIMUM" 4 "GREATER THAN MAXIMUM" ;
VAL_ 1529 VCTLS_UsrCtlAllwd 0 "Allowed" 1 "Not Allowed" ;
VAL_ 1529 VCTLS_CurrSeltnVal 0 "Unknown" 1 "On" 2 "Left" 3 "Right" 4 "Off" ;
VAL_ 1529 VCTLS_CtlAval 0 "Not Available" 1 "Available" ;
VAL_ 1530 AirbgStsIndReq 0 "OFF" 1 "ON" 2 "0.5_Hz" 3 "1_Hz" 4 "2_Hz" 5 "4_Hz" 6 "RESERVED_1" 7 "RESERVED_2" ;
VAL_ 1530 AdpAndCnvntlCruzCtlIndReq 0 "No Action" 1 "Cruise Control and Adaptive Cruise Control Telltale Off" 2 "Cruise Control Unavailable Telltale On" 3 "Cruise Control White Telltale On" 4 "Cruise Control Green Telltale On" 5 "Cruise Control Blue Telltale On" 6 "Adaptive Cruise Control Unavailable Telltale On" 7 "Adaptive Cruise Control White Telltale On" 8 "Adaptive Cruise Control Green Telltale On" 9 "Adaptive Cruise Control Blue Telltale On" ;
VAL_ 1530 DrvStBltRmIndReq 0 "OFF" 1 "ON" 2 "0.5_Hz" 3 "1_Hz" 4 "2_Hz" 5 "4_Hz" 6 "RESERVED_1" 7 "RESERVED_2" ;
VAL_ 1530 BSSIP_BrkAsstBrkBstStsAuth 0 "No Boost" 1 "Normal Boost" 2 "Boost with Warning" 3 "Shut Down Boost" 4 "No Boost EPB Assist" 5 "Hydraulic Leak Detection" 6 "Half System Boost" 7 "Diagnostic Mode" 8 "Brake Fade 1" 9 "Brake Fade 2" ;
VAL_ 1530 SGI2P_AirSpnsnRdHghtActlStsAuth 0 "Faulted" 1 "Entry/Exit" 2 "Lowered 3" 3 "Lowered 2" 4 "Lowered 1" 5 "Showroom" 6 "Normal" 7 "Raised 1" 8 "Raised 2" 9 "Raised 3" 10 "Cargo" 11 "Trailer Low" 12 "Trailer High" 13 "Car Show" ;
VAL_ 1530 RdHgtStatIndReq 0 "Nominal Trim" 1 "Raised 2" 2 "Raised 1" 3 "Lowered 1" 4 "Lowered 2" 5 "Cargo/Trailer" 6 "Entry/Exit" 7 "Alignment Mode" 8 "Service Mode" 9 "Entry/Exit Pending" 10 "Safety Lowered" 11 "Car Show" 12 "Trailer Low" 13 "Trailer High" ;
VAL_ 1530 AutoLnChgCstCurrSetVal 0 "Setting Unkown" 1 "Off" 2 "On" 3 "LCOD" 4 "LCOD and ALC" ;
VAL_ 1530 ArtcldRnngBrdSt 0 "No Action" 1 "Resume Normal Operation" 2 "Running Boards Deployed" 3 "Running Boards Stowed" 4 "Running Boards Cargo Access" 5 "Running Boards Inhibited" 6 "Running Boards Could Not Extend" ;
VAL_ 1530 LAOA_LatAsstOffOptAval 0 "FALSE" 1 "TRUE" ;
VAL_ 1530 LAOA_LatAsstLKAOptAval 0 "FALSE" 1 "TRUE" ;
VAL_ 1530 LAOA_LatAsstLDWOptAval 0 "FALSE" 1 "TRUE" ;
VAL_ 1530 LAOA_LatAsstHoLFOptAval 0 "FALSE" 1 "TRUE" ;
VAL_ 1530 AxlLckUnavailIndReq 0 "No Action" 1 "Rear Axle Not Locked" 2 "Not in 4WD Low" 3 "Speed Too High" 4 "Not During Hill Decent" 5 "Generic Unavailable" 6 "Not in Terrain" 7 "Not in Terrain or Offroad" ;
VAL_ 1530 AutoTrnspHdActvnCstCurrSetVal 0 "Setting Unknown" 1 "Active" 2 "Inactive" ;
VAL_ 1530 DslExhFldDiagWrnIdRq 0 "No Indication" 1 "Warning Level 1" 2 "Warning Level 2" 3 "Warning Level 3" 4 "Warning Level 4" 5 "Warning Level 5" 6 "Warning Level 6" 7 "Warning Level 7" ;
VAL_ 1530 DrvrSeltdSpdLmtrIndReq 0 "No Action" 1 "Driver Selected Speed Limiter Telltale Off" 2 "Driver Selected Speed Limiter Unavailable Telltale On" 3 "Driver Selected Speed Limiter White Telltale On" 4 "Driver Selected Speed Limiter Green Telltale On" ;
VAL_ 1530 BSSIP_LnchCtlModeStsAuth 0 "Disable" 1 "General" 2 "General Custom" 3 "High Traction" 4 "High Traction Custom" 5 "Line Lock" 6 "Line Lock Press Brake" 7 "Line Lock Release Brake" ;
VAL_ 1530 FPLTLI_AuxPrkLmpLtCmd 0 "No Action" 1 "Off" 2 "On" 3 "Ramp On" 4 "Ramp Off" ;
VAL_ 1530 FCAGpSet 0 "FAR" 1 "MEDIUM" 2 "NEAR" 3 "OFF" 4 "UNKNOWN" 5 "FAULTED" ;
VAL_ 1530 FPLTLI_PrkLmpLtCmd 0 "No Action" 1 "Off" 2 "On" 3 "Ramp On" 4 "Ramp Off" ;
VAL_ 1530 FPLTLI_AuxPrkLmpRtCmd 0 "No Action" 1 "Off" 2 "On" 3 "Ramp On" 4 "Ramp Off" ;
VAL_ 1531 LtAstStsIndRq 0 "No Indication" 1 "Off" 2 "LDW" 3 "LKA" 4 "HoLF" ;
VAL_ 1531 HybStatShtlModeOvrrd 0 "Undetermined" 1 "No Override" 2 "Too Cold" 3 "Battery Low" 4 "Speed too High" 5 "Generic Override" 6 "Grade too High" 7 "Accelerator Pedal Threshold Exceeded" ;
VAL_ 1531 FPLTLI_PrkLmpRtCmd 0 "No Action" 1 "Off" 2 "On" 3 "Ramp On" 4 "Ramp Off" ;
VAL_ 1531 MemStorCmpltdIndReq 0 "No Indication" 1 "Memory Button 1" 2 "Memory Button 2" 3 "Memory Button 3" 4 "Memory Button Exit" ;
VAL_ 1531 MemRclHldUntilCmpltIndReq 0 "No Indication" 1 "Memory Button 1" 2 "Memory Button 2" 3 "Memory Button 3" 4 "Memory Button Exit" ;
VAL_ 1531 MemRclCmpltIndReq 0 "No Indication" 1 "Memory Button 1" 2 "Memory Button 2" 3 "Memory Button 3" 4 "Memory Button Exit" ;
VAL_ 1531 NtVsnVidCntrstSts 0 "No Action" 1 "Min" 2 "Default-2" 3 "Default-1" 4 "Default" 5 "Default+1" 6 "Default+2" 7 "Max" ;
VAL_ 1531 NtVsnVidBrghtnsSts 0 "No Action" 1 "Min" 2 "Default-2" 3 "Default-1" 4 "Default" 5 "Default+1" 6 "Default+2" 7 "Max" ;
VAL_ 1531 RdHgtAtLocIndReq 0 "No Indication" 1 "Stored" 2 "Cleared" 3 "All Cleared" 4 "Not Saved" 5 "Unknown" ;
VAL_ 1531 RdHgtActvnIndReq 0 "No Indication" 1 "Raising" 2 "Lowering" 3 "Location Raising" 4 "Location Lowering" 5 "Raising Without Remember" ;
VAL_ 1531 PARgn 0 "Europe" 1 "North America" ;
VAL_ 1531 SecAxlTransStatAchvd_Inv 0 "FALSE" 1 "TRUE" ;
VAL_ 1531 RdHgtWrn1IndReq 0 "No indication" 1 "Front Lift Inhibited" 2 "Leveling Inhibited" 3 "Front Lift Unavailable" 4 "Leveling Unavailable" 5 "Front Lift Faulted" 6 "Leveling Faulted" ;
VAL_ 1531 RdHgtMvmtIndReq 0 "No Movement" 1 "Raising to 2" 2 "Raising" 3 "Lowering" 4 "Cargo Loading" ;
VAL_ 1531 TrnsSftMdSt 0 "No Override Mode" 1 "Performance Mode" 2 "Lift-Foot Cornering Mode" 3 "Automatic Grade Braking Mode" ;
VAL_ 1531 TrlrMirVidEnblCstCurrSetVal 0 "Setting_Unknown" 1 "Off" 2 "On" 3 "Reserved_3" 4 "Reserved_4" 5 "Reserved_5" 6 "Reserved_6" 7 "Reserved_7" ;
VAL_ 1531 SecAxlTransStatAchvd 0 "Unknown" 1 "Neutral" 2 "Mode 1" ;
VAL_ 1531 WndPstnStsLR 0 "Denormalized" 1 "Fully Closed" 2 "Less Than Position A" 3 "Position A" 4 "Greater Than A but less than Position C" 5 "Position C" 6 "Greater than Position C but less than Fully open" 7 "Fully Open" ;
VAL_ 1531 WndPstnStsLF 0 "Denormalized" 1 "Fully Closed" 2 "Less Than Position A" 3 "Position A" 4 "Greater Than A but less than Position C" 5 "Position C" 6 "Greater than Position C but less than Fully open" 7 "Fully Open" ;
VAL_ 1531 VhSpdCntlSystmTyp 0 "No Vehicle Speed Control" 1 "Conventional Cruise Control" 2 "Adaptive Cruise Control" ;
VAL_ 1531 ACCRtSpdAdVsIndOn 0 "FALSE" 1 "TRUE" ;
VAL_ 1531 WndPstnStsRR 0 "Denormalized" 1 "Fully Closed" 2 "Less Than Position A" 3 "Position A" 4 "Greater Than A but less than Position C" 5 "Position C" 6 "Greater than Position C but less than Fully open" 7 "Fully Open" ;
VAL_ 1531 WndPstnStsRF 0 "Denormalized" 1 "Fully Closed" 2 "Less Than Position A" 3 "Position A" 4 "Greater Than A but less than Position C" 5 "Position C" 6 "Greater than Position C but less than Fully open" 7 "Fully Open" ;
VAL_ 1532 WthrSnwModeDrvlineVisDispVal 0 "Setting_Unknown" 1 "Custom_Mode_1" 2 "Custom_Mode_2" 3 "Custom_Mode_3" 4 "Custom_Mode_4" 5 "Custom_Mode_5" 6 "Custom_Mode_6" 7 "Custom_Mode_7" ;
VAL_ 1532 WthrSnwModeBrkPedVisDispVal 0 "Setting_Unknown" 1 "Custom_Mode_1" 2 "Custom_Mode_2" 3 "Custom_Mode_3" 4 "Custom_Mode_4" 5 "Custom_Mode_5" 6 "Custom_Mode_6" 7 "Custom_Mode_7" ;
VAL_ 1532 WthrSnwModeActvAeroVisDispVal 0 "Setting_Unknown" 1 "Custom_Mode_1" 2 "Custom_Mode_2" 3 "Custom_Mode_3" 4 "Custom_Mode_4" 5 "Custom_Mode_5" 6 "Custom_Mode_6" 7 "Custom_Mode_7" ;
VAL_ 1532 WthrSnwModeRideHghtVisDispVal 0 "Setting_Unknown" 1 "Custom_Mode_1" 2 "Custom_Mode_2" 3 "Custom_Mode_3" 4 "Custom_Mode_4" 5 "Custom_Mode_5" 6 "Custom_Mode_6" 7 "Custom_Mode_7" ;
VAL_ 1532 WthrSnwModePwrtrnVisDispVal 0 "Setting_Unknown" 1 "Custom_Mode_1" 2 "Custom_Mode_2" 3 "Custom_Mode_3" 4 "Custom_Mode_4" 5 "Custom_Mode_5" 6 "Custom_Mode_6" 7 "Custom_Mode_7" ;
VAL_ 1532 WthrSnwModeESCVisDispVal 0 "Setting_Unknown" 1 "Custom_Mode_1" 2 "Custom_Mode_2" 3 "Custom_Mode_3" 4 "Custom_Mode_4" 5 "Custom_Mode_5" 6 "Custom_Mode_6" 7 "Custom_Mode_7" ;
VAL_ 1532 WthrSnwModeSpnsnVisDispVal 0 "Setting_Unknown" 1 "Custom_Mode_1" 2 "Custom_Mode_2" 3 "Custom_Mode_3" 4 "Custom_Mode_4" 5 "Custom_Mode_5" 6 "Custom_Mode_6" 7 "Custom_Mode_7" ;
VAL_ 1532 WthrSnwModeSndVisDispVal 0 "Setting_Unknown" 1 "Custom_Mode_1" 2 "Custom_Mode_2" 3 "Custom_Mode_3" 4 "Custom_Mode_4" 5 "Custom_Mode_5" 6 "Custom_Mode_6" 7 "Custom_Mode_7" ;
VAL_ 1532 CmdSndRwCtStbtVisInd 0 "No Indication" 1 "Unbuckled Indication" 2 "Buckled Indication" 3 "Unbuckled Flashing Indication" ;
VAL_ 1532 CltTpTrvAchv 0 "FALSE" 1 "TRUE" ;
VAL_ 1532 CltTpTrvAchv_Inv 0 "FALSE" 1 "TRUE" ;
VAL_ 1532 AdvdFrtLgtSysIndReq 0 "NO INDICATION" 1 "FAILURE INDICATION" 2 "TOURIST MODE SETTING CHANGED" 3 "TOURIST MODE REMINDER" ;
VAL_ 1532 ACCHdwySttng 0 "FAR" 1 "MEDIUM" 2 "NEAR" ;
VAL_ 1532 CmdThrdRwLtStbtVisInd 0 "No Indication" 1 "Unbuckled Indication" 2 "Buckled Indication" 3 "Unbuckled Flashing Indication" ;
VAL_ 1532 CmdThrdRwCtStbtVisInd 0 "No Indication" 1 "Unbuckled Indication" 2 "Buckled Indication" 3 "Unbuckled Flashing Indication" ;
VAL_ 1532 CmdSndRwRtStbtVisInd 0 "No Indication" 1 "Unbuckled Indication" 2 "Buckled Indication" 3 "Unbuckled Flashing Indication" ;
VAL_ 1532 CmdSndRwLtStbtVisInd 0 "No Indication" 1 "Unbuckled Indication" 2 "Buckled Indication" 3 "Unbuckled Flashing Indication" ;
VAL_ 1532 ElecShftrLckdHldBrkToOvrrdIndOn 0 "FALSE" 1 "TRUE" ;
VAL_ 1532 CmdThrdRwRtStbtVisInd 0 "No Indication" 1 "Unbuckled Indication" 2 "Buckled Indication" 3 "Unbuckled Flashing Indication" ;
VAL_ 1532 ElecAxlUnvIndReq 0 "No Indication" 1 "Limited" 2 "Faulted" ;
VAL_ 1532 ElecAxlBstGageIndReq 0 "Normal" 1 "Temporarily Unavailable" 2 "Unavailable" ;
VAL_ 1532 DslEmnsOBDMrkt 0 "North America" 1 "LD Europe" 2 "HD Europe" ;
VAL_ 1532 LnCntrSpchPrmtReq 0 "No Prompt" 1 "Take Steering" 2 "Take Vehicle Control" ;
VAL_ 1532 GlrFrHiBmSts 0 "OFF" 1 "AHBA" 2 "GFHB" ;
VAL_ 1532 EngCmptHotWrnIndReq 0 "Off" 1 "Service" 2 "Hot Idle" 3 "Hot" ;
VAL_ 1532 ElecShftPrTwoGrsSelIndRq 0 "OFF" 1 "PARK" 2 "NEUTRAL" 3 "DRIVE" ;
VAL_ 1533 ROSP_FrntPsRestOcpStatAuth 0 "Unknown" 1 "Empty" 2 "Empty or Occupied_Non-Adult" 3 "Occupied_Adult" ;
VAL_ 1533 PdWrnIndRqst 0 "OFF" 1 "PEDESTRIAN ADVISORY" 2 "PEDESTRIAN ALERT" 3 "RESERVED" ;
VAL_ 1533 PPVehRadioMutReq 0 "Unknown" 1 "Mute Requested" 2 "Mute Not Requested" ;
VAL_ 1533 NtVsnFncSts 0 "Normal" 1 "Limited" 2 "Unavailable" 3 "Invalid" ;
VAL_ 1533 ACCSysSlctdMdDspIndOn 0 "FALSE" 1 "TRUE" ;
VAL_ 1533 ACCShftToPrkBfrExIndOn 0 "FALSE" 1 "TRUE" ;
VAL_ 1533 WhlSlpSt 0 "No Slip Detected" 1 "Negative Slip Detected" 2 "Positive Slip Detected" 3 "Slip Detection Fault" ;
VAL_ 1533 VehMassEstSts 0 "Undetermined" 1 "Degraded" 2 "Normal" ;
VAL_ 1533 TrlrArtclnAngCalSts 0 "Unknown" 1 "Available" 2 "Degraded" 3 "Unavailable" ;
VAL_ 1533 AutoLnChgCstAvlFlg3 0 "FALSE" 1 "TRUE" ;
VAL_ 1533 AutoLnChgCstAvlFlg2 0 "FALSE" 1 "TRUE" ;
VAL_ 1533 AutoLnChgCstAvlFlg1 0 "FALSE" 1 "TRUE" ;
VAL_ 1533 AutoBmSlctAllwd 0 "FALSE" 1 "TRUE" ;
VAL_ 1533 AirCndOffIO 0 "FALSE" 1 "TRUE" ;
VAL_ 1533 AdptCrsCntrlEngd 0 "FALSE" 1 "TRUE" ;
VAL_ 1533 ACCompCmnd 0 "Off" 1 "On" ;
VAL_ 1533 ACCTmpUnvIndOn 0 "FALSE" 1 "TRUE" ;
VAL_ 1533 AutoTrnspHdActvnCstAvlFlg3 0 "FALSE" 1 "TRUE" ;
VAL_ 1533 AutoTrnspHdActvnCstAvlFlg2 0 "FALSE" 1 "TRUE" ;
VAL_ 1533 AutoTrnspHdActvnCstAvlFlg1 0 "FALSE" 1 "TRUE" ;
VAL_ 1533 AutoLnChgCstSetAval 0 "FALSE" 1 "TRUE" ;
VAL_ 1533 AutoLnChgCstAvlFlg7 0 "FALSE" 1 "TRUE" ;
VAL_ 1533 AutoLnChgCstAvlFlg6 0 "FALSE" 1 "TRUE" ;
VAL_ 1533 AutoLnChgCstAvlFlg5 0 "FALSE" 1 "TRUE" ;
VAL_ 1533 AutoLnChgCstAvlFlg4 0 "FALSE" 1 "TRUE" ;
VAL_ 1533 DCCnvStblznErrIndOn 0 "FALSE" 1 "TRUE" ;
VAL_ 1533 CustmStbCtlRdctReqIndOn 0 "FALSE" 1 "TRUE" ;
VAL_ 1533 AxlLcksServIO 0 "FALSE" 1 "TRUE" ;
VAL_ 1533 AutoTrnspHdActvnCstSetAval 0 "FALSE" 1 "TRUE" ;
VAL_ 1533 AutoTrnspHdActvnCstAvlFlg7 0 "FALSE" 1 "TRUE" ;
VAL_ 1533 AutoTrnspHdActvnCstAvlFlg6 0 "FALSE" 1 "TRUE" ;
VAL_ 1533 AutoTrnspHdActvnCstAvlFlg5 0 "FALSE" 1 "TRUE" ;
VAL_ 1533 AutoTrnspHdActvnCstAvlFlg4 0 "FALSE" 1 "TRUE" ;
VAL_ 1533 DM8Denied 0 "FALSE" 1 "TRUE" ;
VAL_ 1533 DM7Denied 0 "FALSE" 1 "TRUE" ;
VAL_ 1533 DM6Denied 0 "FALSE" 1 "TRUE" ;
VAL_ 1533 DM5Denied 0 "FALSE" 1 "TRUE" ;
VAL_ 1533 DM4Denied 0 "FALSE" 1 "TRUE" ;
VAL_ 1533 DM3Denied 0 "FALSE" 1 "TRUE" ;
VAL_ 1533 DM2Denied 0 "FALSE" 1 "TRUE" ;
VAL_ 1533 DM1Denied 0 "FALSE" 1 "TRUE" ;
VAL_ 1533 ElecShfPriTransCtlrMalfIndOn 0 "FALSE" 1 "TRUE" ;
VAL_ 1533 ElecShfPriShfToDrvTryAgnIndOn 0 "FALSE" 1 "TRUE" ;
VAL_ 1533 ElecShfPriRdcSpdForReqdShfIndOn 0 "FALSE" 1 "TRUE" ;
VAL_ 1533 ElecShfLckdBcklPsngrStBltIndOn 0 "FALSE" 1 "TRUE" ;
VAL_ 1533 ElecShfLckdBcklDrvrStBltIndOn 0 "FALSE" 1 "TRUE" ;
VAL_ 1533 DrSlctdSpdLmtrEnbld 0 "FALSE" 1 "TRUE" ;
VAL_ 1533 DrSlctdSpdLmtrActv 0 "FALSE" 1 "TRUE" ;
VAL_ 1533 ElecShftPrDrDoorStIndIO 0 "FALSE" 1 "TRUE" ;
VAL_ 1533 ElecShftPrAtPrkIO 0 "FALSE" 1 "TRUE" ;
VAL_ 1533 ElecShfUnlckdBrkToShfIndOn 0 "FALSE" 1 "TRUE" ;
VAL_ 1533 ElecShfPriTrnVehOffForPrkIndOn 0 "FALSE" 1 "TRUE" ;
VAL_ 1276 ElecShftPrTrnMlfIO 0 "FALSE" 1 "TRUE" ;
VAL_ 1276 ElecShftPrRngInvRqIO 0 "FALSE" 1 "TRUE" ;
VAL_ 1276 ElecShftPrPrkInvRqIO 0 "FALSE" 1 "TRUE" ;
VAL_ 1276 ElecShftPrLtdPrfMdIO 0 "FALSE" 1 "TRUE" ;
VAL_ 1276 ElecShftPrHldShftLevEngRngIO 0 "FALSE" 1 "TRUE" ;
VAL_ 1276 ElecShftPrDrPrkIntShftAtmpIO 0 "FALSE" 1 "TRUE" ;
VAL_ 1276 ElecShftPrDrIntShftAtmpIO 0 "FALSE" 1 "TRUE" ;
VAL_ 1276 ElecShftPrDrExitIO 0 "FALSE" 1 "TRUE" ;
VAL_ 1276 FrwdCllsnSysRdIndOn 0 "FALSE" 1 "TRUE" ;
VAL_ 1276 FrwdCllsnSysOffIndOn 0 "FALSE" 1 "TRUE" ;
VAL_ 1276 FrwdCllsnAlrtOffIndOn 0 "FALSE" 1 "TRUE" ;
VAL_ 1276 FrtPedtrnBrkgWrnIndOn 0 "FALSE" 1 "TRUE" ;
VAL_ 1276 FrntAxlLckIO 0 "FALSE" 1 "TRUE" ;
VAL_ 1276 FrFgLmpIO 0 "FALSE" 1 "TRUE" ;
VAL_ 1276 EngNEmsnsRltMlfnAct 0 "FALSE" 1 "TRUE" ;
VAL_ 1276 EngCstFlCtOffAct 0 "FALSE" 1 "TRUE" ;
VAL_ 1276 LnCntrArrwBlck4Act 0 "FALSE" 1 "TRUE" ;
VAL_ 1276 LnCntrArrwBlck3Act 0 "FALSE" 1 "TRUE" ;
VAL_ 1276 LnCntrArrwBlck2Act 0 "FALSE" 1 "TRUE" ;
VAL_ 1276 LnCntrArrwBlck1Act 0 "FALSE" 1 "TRUE" ;
VAL_ 1276 HzrdReqActv 0 "FALSE" 1 "TRUE" ;
VAL_ 1276 GenFld 0 "FALSE" 1 "TRUE" ;
VAL_ 1276 FrwdClsnSysIndOn 0 "FALSE" 1 "TRUE" ;
VAL_ 1276 FrwdCllsnSysUnIndOn 0 "FALSE" 1 "TRUE" ;
VAL_ 1276 LvlgSysEntEgrsMdCstAvlFlg3 0 "FALSE" 1 "TRUE" ;
VAL_ 1276 LvlgSysEntEgrsMdCstAvlFlg2 0 "FALSE" 1 "TRUE" ;
VAL_ 1276 LvlgSysEntEgrsMdCstAvlFlg1 0 "FALSE" 1 "TRUE" ;
VAL_ 1276 LvlgSysAlgnMdCstAvlFlg7 0 "FALSE" 1 "TRUE" ;
VAL_ 1276 LvlgSysAlgnMdCstAvlFlg6 0 "FALSE" 1 "TRUE" ;
VAL_ 1276 LnKpAsstUnAvIndOn 0 "FALSE" 1 "TRUE" ;
VAL_ 1276 LnDprtrWrngUnAvIndOn 0 "FALSE" 1 "TRUE" ;
VAL_ 1276 LnCntrArrwBlck5Act 0 "FALSE" 1 "TRUE" ;
VAL_ 1276 LvlgSysServMdCstAvlFlg4 0 "FALSE" 1 "TRUE" ;
VAL_ 1276 LvlgSysServMdCstAvlFlg3 0 "FALSE" 1 "TRUE" ;
VAL_ 1276 LvlgSysServMdCstAvlFlg2 0 "FALSE" 1 "TRUE" ;
VAL_ 1276 LvlgSysServMdCstAvlFlg1 0 "FALSE" 1 "TRUE" ;
VAL_ 1276 LvlgSysEntEgrsMdCstAvlFlg7 0 "FALSE" 1 "TRUE" ;
VAL_ 1276 LvlgSysEntEgrsMdCstAvlFlg6 0 "FALSE" 1 "TRUE" ;
VAL_ 1276 LvlgSysEntEgrsMdCstAvlFlg5 0 "FALSE" 1 "TRUE" ;
VAL_ 1276 LvlgSysEntEgrsMdCstAvlFlg4 0 "FALSE" 1 "TRUE" ;
VAL_ 1276 PrkAsstActIndCmnd 0 "FALSE" 1 "TRUE" ;
VAL_ 1276 NoKeyDtdElecShfDndIndOn 0 "FALSE" 1 "TRUE" ;
VAL_ 1276 MemStorTmdOutIndOn 0 "FALSE" 1 "TRUE" ;
VAL_ 1276 MemStorPrssSetFrstIndOn 0 "FALSE" 1 "TRUE" ;
VAL_ 1276 MemSeeAutoRclSetsIndOn 0 "FALSE" 1 "TRUE" ;
VAL_ 1276 LvlgSysServMdCstAvlFlg7 0 "FALSE" 1 "TRUE" ;
VAL_ 1276 LvlgSysServMdCstAvlFlg6 0 "FALSE" 1 "TRUE" ;
VAL_ 1276 LvlgSysServMdCstAvlFlg5 0 "FALSE" 1 "TRUE" ;
VAL_ 1276 SftTpFlrIO 0 "FALSE" 1 "TRUE" ;
VAL_ 1276 RrVirtBmpAutoBrkRelIndOn 0 "FALSE" 1 "TRUE" ;
VAL_ 1276 RrFgLmpIO 0 "FALSE" 1 "TRUE" ;
VAL_ 1276 RrAxlLckIO 0 "FALSE" 1 "TRUE" ;
VAL_ 1276 RmtRflshDispActvnReq 0 "FALSE" 1 "TRUE" ;
VAL_ 1276 RmtRflshCmpgnAval 0 "FALSE" 1 "TRUE" ;
VAL_ 1276 ROSP_FrtPsRestOcpFltIndAuth 0 "FALSE" 1 "TRUE" ;
VAL_ 1276 StNtLtchdIO 0 "FALSE" 1 "TRUE" ;
VAL_ 1276 SrvPedtrnProtSysIO 0 "FALSE" 1 "TRUE" ;
VAL_ 1276 SrvFrwdCllsnSysIndOn 0 "FALSE" 1 "TRUE" ;
VAL_ 1276 SrvDvrAsstSystVslMsgRqstOn 0 "FALSE" 1 "TRUE" ;
VAL_ 1276 SftTpVltLwIO 0 "FALSE" 1 "TRUE" ;
VAL_ 1276 SftTpVehOvSpdIO 0 "FALSE" 1 "TRUE" ;
VAL_ 1276 SftTpTmpLwIO 0 "FALSE" 1 "TRUE" ;
VAL_ 1534 TrlrFgLtFld 0 "FALSE" 1 "TRUE" ;
VAL_ 1534 TrlrDisconndIndOn 0 "FALSE" 1 "TRUE" ;
VAL_ 1534 TrlrBrkLtFld 0 "FALSE" 1 "TRUE" ;
VAL_ 1534 TrlLfTrInLtFld 0 "FALSE" 1 "TRUE" ;
VAL_ 1534 TnDrvRIMOFFUnvIndOn 0 "FALSE" 1 "TRUE" ;
VAL_ 1534 TnDrvGapAdjUnvIndOn 0 "FALSE" 1 "TRUE" ;
VAL_ 1534 TeenDrvrLnDprtrWrnOffUnvIndOn 0 "FALSE" 1 "TRUE" ;
VAL_ 1534 StlthModeActv 0 "FALSE" 1 "TRUE" ;
VAL_ 1534 TrnsEmsRltMlfAtv 0 "FALSE" 1 "TRUE" ;
VAL_ 1534 TrnLmpRrRtOtgIndOn 0 "FALSE" 1 "TRUE" ;
VAL_ 1534 TrnLmpRrLtOtgIndOn 0 "FALSE" 1 "TRUE" ;
VAL_ 1534 TrnLmpFrtRtOtgIndOn 0 "FALSE" 1 "TRUE" ;
VAL_ 1534 TrnLmpFrtLtOtgIndOn 0 "FALSE" 1 "TRUE" ;
VAL_ 1534 TrlrTlLtFld 0 "FALSE" 1 "TRUE" ;
VAL_ 1534 TrlrRvrsLmpOtgIndOn 0 "FALSE" 1 "TRUE" ;
VAL_ 1534 TrlrRtTrInLtFld 0 "FALSE" 1 "TRUE" ;
VAL_ 1534 SnrfActlPstn 0 "0%" 1 "10%" 2 "20%" 3 "30%" 4 "40%" 5 "50%" 6 "60%" 7 "70%" 8 "80%" 9 "90%" 10 "100%" 11 "Between Positions" 12 "Vent" 13 "Comfort Open" ;
VAL_ 1534 TrnsThrmlMngmntSt 0 "Normal" 1 "Countermeasures Active" 2 "Driver Intervention Requested" ;
VAL_ 1534 VltSwAtvIO 0 "FALSE" 1 "TRUE" ;
VAL_ 1534 UIDInStatusSD 0 "Not Present" 1 "Present" ;
VAL_ 1534 TrnstStrgLogisticsMdActivation 0 "FALSE" 1 "TRUE" ;
VAL_ 1534 TrnsOilChngIO 0 "FALSE" 1 "TRUE" ;
VAL_ 1534 TrnsNEmsRltMlfActv 0 "FALSE" 1 "TRUE" ;
VAL_ 1534 ADASMsgDispLocNonActvInd 0 "None" 1 "Cluster Display" 2 "Center Stack Display" 3 "Both" ;
VAL_ 1534 ADASMsgDispLocLtdPerfStatInd 0 "None" 1 "Cluster Display" 2 "Center Stack Display" 3 "Both" ;
VAL_ 1534 ArflBsdOnOccpRrPsCstCurrSetVal 0 "Setting Unknown" 1 "Off" 2 "On" ;
VAL_ 1534 ArflBsdOnOccpFrtPsCstCurrSetVal 0 "Setting Unknown" 1 "Off" 2 "On" ;
VAL_ 1534 ADASTrmLvlInd 0 "None" 1 "Super" 2 "Ultra" ;
VAL_ 1534 LnCntrWrn2IndReq 0 "No Indication" 1 "Hill Descent Control Active" 2 "Power Take Off Active" 3 "Road Users Too Close" 4 "Unknown Object Too Close" 5 "Turn Signal is On" 6 "Excessive Acceleration" 7 "Door is Open" 8 "Traction Control Event" 9 "Traction Control Off" 10 "VSC Event" 11 "VSC Off" 12 "Release Parking Brake" 13 "Transfer Case Setting" 14 "Battery Low" 15 "Speed Limiter Active or Being Activated" 16 "Steep Road" 17 "Switch Gear to Drive" 18 "Regen Active" 19 "Brakes Overheated" 20 "No Route Information" 21 "Ultra Cruise Accelerator Pressed" 22 "Approaching Emergency Vehicle" 23 "Construction Zone Approaching" 24 "Railroad Approaching" 25 "Weather" ;
VAL_ 1824 SprTireSt 0 "Undetermined" 1 "No Spare Detected" 2 "Spare Detected" ;
VAL_ 1824 BrkFldLvlSt 0 "Normal" 1 "Low" 2 "Unknown" ;
VAL_ 1241 ACRfHiSdFldPrs_Inv 0 "FALSE" 1 "TRUE" ;
VAL_ 1241 ArbdEngTemp_Inv 0 "FALSE" 1 "TRUE" ;
VAL_ 1241 BarPrsAbs_Inv 0 "FALSE" 1 "TRUE" ;
VAL_ 1241 DslExhFldLvlPct_Inv 0 "FALSE" 1 "TRUE" ;
VAL_ 1241 ElecMtrARotrTemp_Inv 0 "FALSE" 1 "TRUE" ;
VAL_ 1241 ElecMtrASttrTemp_Inv 0 "FALSE" 1 "TRUE" ;
VAL_ 1241 HiVltgBatMaxTemp_Inv 0 "FALSE" 1 "TRUE" ;
VAL_ 1241 ABSPr 0 "FALSE" 1 "TRUE" ;
VAL_ 1825 HiVltgBatMinTemp_Inv 0 "FALSE" 1 "TRUE" ;
VAL_ 1825 TrnsOilTmp_Inv 0 "FALSE" 1 "TRUE" ;
VAL_ 1825 TireTmpLF_Inv 0 "FALSE" 1 "TRUE" ;
VAL_ 1825 AdpLghtRspTypCstAvlFlg2 0 "FALSE" 1 "TRUE" ;
VAL_ 1825 AdpLghtRspTypCstAvlFlg1 0 "FALSE" 1 "TRUE" ;
VAL_ 1240 TireTmpLR_Inv 0 "FALSE" 1 "TRUE" ;
VAL_ 1240 TireTmpRF_Inv 0 "FALSE" 1 "TRUE" ;
VAL_ 1240 TireTmpRR_Inv 0 "FALSE" 1 "TRUE" ;
VAL_ 1240 FrtRdHgtGPSCstAvlbltyFlg7 0 "FALSE" 1 "TRUE" ;
VAL_ 1240 FrtRdHgtGPSCstAvlbltyFlg6 0 "FALSE" 1 "TRUE" ;
VAL_ 1240 FrtRdHgtGPSCstAvlbltyFlg5 0 "FALSE" 1 "TRUE" ;
VAL_ 1240 FrtRdHgtGPSCstAvlbltyFlg4 0 "FALSE" 1 "TRUE" ;
VAL_ 1240 FrtRdHgtGPSCstAvlbltyFlg3 0 "FALSE" 1 "TRUE" ;
VAL_ 1240 FrtRdHgtGPSCstAvlbltyFlg2 0 "FALSE" 1 "TRUE" ;
VAL_ 1240 FrtRdHgtGPSCstAvlbltyFlg1 0 "FALSE" 1 "TRUE" ;
VAL_ 1240 AdpLghtRspTypCstAvlFlg3 0 "FALSE" 1 "TRUE" ;
VAL_ 1240 LvlgSysAlgnMdCstAvlFlg1 0 "FALSE" 1 "TRUE" ;
VAL_ 1240 LtRtHnTrCstAvlFlg7 0 "FALSE" 1 "TRUE" ;
VAL_ 1240 LtRtHnTrCstAvlFlg6 0 "FALSE" 1 "TRUE" ;
VAL_ 1240 LtRtHnTrCstAvlFlg5 0 "FALSE" 1 "TRUE" ;
VAL_ 1240 LtRtHnTrCstAvlFlg4 0 "FALSE" 1 "TRUE" ;
VAL_ 1240 LtRtHnTrCstAvlFlg3 0 "FALSE" 1 "TRUE" ;
VAL_ 1240 LtRtHnTrCstAvlFlg2 0 "FALSE" 1 "TRUE" ;
VAL_ 1240 LtRtHnTrCstAvlFlg1 0 "FALSE" 1 "TRUE" ;
VAL_ 1240 PrkAsstONOFFCstAvlFlg3 0 "FALSE" 1 "TRUE" ;
VAL_ 1240 PrkAsstONOFFCstAvlFlg2 0 "FALSE" 1 "TRUE" ;
VAL_ 1240 PrkAsstONOFFCstAvlFlg1 0 "FALSE" 1 "TRUE" ;
VAL_ 1240 PTHiElecLdReqd 0 "FALSE" 1 "TRUE" ;
VAL_ 1240 LvlgSysAlgnMdCstAvlFlg5 0 "FALSE" 1 "TRUE" ;
VAL_ 1240 LvlgSysAlgnMdCstAvlFlg4 0 "FALSE" 1 "TRUE" ;
VAL_ 1240 LvlgSysAlgnMdCstAvlFlg3 0 "FALSE" 1 "TRUE" ;
VAL_ 1240 LvlgSysAlgnMdCstAvlFlg2 0 "FALSE" 1 "TRUE" ;
VAL_ 1240 PrkAsstTrHtchPsntCstAvlFlg4 0 "FALSE" 1 "TRUE" ;
VAL_ 1240 PrkAsstTrHtchPsntCstAvlFlg3 0 "FALSE" 1 "TRUE" ;
VAL_ 1240 PrkAsstTrHtchPsntCstAvlFlg2 0 "FALSE" 1 "TRUE" ;
VAL_ 1240 PrkAsstTrHtchPsntCstAvlFlg1 0 "FALSE" 1 "TRUE" ;
VAL_ 1240 PrkAsstONOFFCstAvlFlg7 0 "FALSE" 1 "TRUE" ;
VAL_ 1240 PrkAsstONOFFCstAvlFlg6 0 "FALSE" 1 "TRUE" ;
VAL_ 1240 PrkAsstONOFFCstAvlFlg5 0 "FALSE" 1 "TRUE" ;
VAL_ 1240 PrkAsstONOFFCstAvlFlg4 0 "FALSE" 1 "TRUE" ;
VAL_ 1826 RnngBrdAutoDplyCstAvlFlg5 0 "FALSE" 1 "TRUE" ;
VAL_ 1826 RnngBrdAutoDplyCstAvlFlg4 0 "FALSE" 1 "TRUE" ;
VAL_ 1826 RnngBrdAutoDplyCstAvlFlg3 0 "FALSE" 1 "TRUE" ;
VAL_ 1826 RnngBrdAutoDplyCstAvlFlg2 0 "FALSE" 1 "TRUE" ;
VAL_ 1826 RnngBrdAutoDplyCstAvlFlg1 0 "FALSE" 1 "TRUE" ;
VAL_ 1826 PrkAsstTrHtchPsntCstAvlFlg7 0 "FALSE" 1 "TRUE" ;
VAL_ 1826 PrkAsstTrHtchPsntCstAvlFlg6 0 "FALSE" 1 "TRUE" ;
VAL_ 1826 PrkAsstTrHtchPsntCstAvlFlg5 0 "FALSE" 1 "TRUE" ;
VAL_ 1826 RnngBrdManDplyCstAvlFlg6 0 "FALSE" 1 "TRUE" ;
VAL_ 1826 RnngBrdManDplyCstAvlFlg5 0 "FALSE" 1 "TRUE" ;
VAL_ 1826 RnngBrdManDplyCstAvlFlg4 0 "FALSE" 1 "TRUE" ;
VAL_ 1826 RnngBrdManDplyCstAvlFlg3 0 "FALSE" 1 "TRUE" ;
VAL_ 1826 RnngBrdManDplyCstAvlFlg2 0 "FALSE" 1 "TRUE" ;
VAL_ 1826 RnngBrdManDplyCstAvlFlg1 0 "FALSE" 1 "TRUE" ;
VAL_ 1826 RnngBrdAutoDplyCstAvlFlg7 0 "FALSE" 1 "TRUE" ;
VAL_ 1826 RnngBrdAutoDplyCstAvlFlg6 0 "FALSE" 1 "TRUE" ;
VAL_ 1826 RrVwPrkAstSymCsAvlFlg7 0 "FALSE" 1 "TRUE" ;
VAL_ 1826 RrVwPrkAstSymCsAvlFlg6 0 "FALSE" 1 "TRUE" ;
VAL_ 1826 RrVwPrkAstSymCsAvlFlg5 0 "FALSE" 1 "TRUE" ;
VAL_ 1826 RrVwPrkAstSymCsAvlFlg4 0 "FALSE" 1 "TRUE" ;
VAL_ 1826 RrVwPrkAstSymCsAvlFlg3 0 "FALSE" 1 "TRUE" ;
VAL_ 1826 RrVwPrkAstSymCsAvlFlg2 0 "FALSE" 1 "TRUE" ;
VAL_ 1826 RrVwPrkAstSymCsAvlFlg1 0 "FALSE" 1 "TRUE" ;
VAL_ 1826 RnngBrdManDplyCstAvlFlg7 0 "FALSE" 1 "TRUE" ;
VAL_ 1826 StBltTghtngCstAvlFlg1 0 "FALSE" 1 "TRUE" ;
VAL_ 1826 SrrndVwLghtCsAvlFlg7 0 "FALSE" 1 "TRUE" ;
VAL_ 1826 SrrndVwLghtCsAvlFlg6 0 "FALSE" 1 "TRUE" ;
VAL_ 1826 SrrndVwLghtCsAvlFlg5 0 "FALSE" 1 "TRUE" ;
VAL_ 1826 SrrndVwLghtCsAvlFlg4 0 "FALSE" 1 "TRUE" ;
VAL_ 1826 SrrndVwLghtCsAvlFlg3 0 "FALSE" 1 "TRUE" ;
VAL_ 1826 SrrndVwLghtCsAvlFlg2 0 "FALSE" 1 "TRUE" ;
VAL_ 1826 SrrndVwLghtCsAvlFlg1 0 "FALSE" 1 "TRUE" ;
VAL_ 1826 TnDrvStBltShfIntlkCstAvlFlg2 0 "FALSE" 1 "TRUE" ;
VAL_ 1826 TnDrvStBltShfIntlkCstAvlFlg1 0 "FALSE" 1 "TRUE" ;
VAL_ 1826 StBltTghtngCstAvlFlg7 0 "FALSE" 1 "TRUE" ;
VAL_ 1826 StBltTghtngCstAvlFlg6 0 "FALSE" 1 "TRUE" ;
VAL_ 1826 StBltTghtngCstAvlFlg5 0 "FALSE" 1 "TRUE" ;
VAL_ 1826 StBltTghtngCstAvlFlg4 0 "FALSE" 1 "TRUE" ;
VAL_ 1826 StBltTghtngCstAvlFlg3 0 "FALSE" 1 "TRUE" ;
VAL_ 1826 StBltTghtngCstAvlFlg2 0 "FALSE" 1 "TRUE" ;
VAL_ 1826 TrlrMirVidEnblCstAvlFlg3 0 "FALSE" 1 "TRUE" ;
VAL_ 1826 TrlrMirVidEnblCstAvlFlg2 0 "FALSE" 1 "TRUE" ;
VAL_ 1826 TrlrMirVidEnblCstAvlFlg1 0 "FALSE" 1 "TRUE" ;
VAL_ 1826 TnDrvStBltShfIntlkCstAvlFlg7 0 "FALSE" 1 "TRUE" ;
VAL_ 1826 TnDrvStBltShfIntlkCstAvlFlg6 0 "FALSE" 1 "TRUE" ;
VAL_ 1826 TnDrvStBltShfIntlkCstAvlFlg5 0 "FALSE" 1 "TRUE" ;
VAL_ 1826 TnDrvStBltShfIntlkCstAvlFlg4 0 "FALSE" 1 "TRUE" ;
VAL_ 1826 TnDrvStBltShfIntlkCstAvlFlg3 0 "FALSE" 1 "TRUE" ;
VAL_ 1826 TrlrMirVidGdlnsCstAvlFlg4 0 "FALSE" 1 "TRUE" ;
VAL_ 1826 TrlrMirVidGdlnsCstAvlFlg3 0 "FALSE" 1 "TRUE" ;
VAL_ 1826 TrlrMirVidGdlnsCstAvlFlg2 0 "FALSE" 1 "TRUE" ;
VAL_ 1826 TrlrMirVidGdlnsCstAvlFlg1 0 "FALSE" 1 "TRUE" ;
VAL_ 1826 TrlrMirVidEnblCstAvlFlg7 0 "FALSE" 1 "TRUE" ;
VAL_ 1826 TrlrMirVidEnblCstAvlFlg6 0 "FALSE" 1 "TRUE" ;
VAL_ 1826 TrlrMirVidEnblCstAvlFlg5 0 "FALSE" 1 "TRUE" ;
VAL_ 1826 TrlrMirVidEnblCstAvlFlg4 0 "FALSE" 1 "TRUE" ;
VAL_ 1826 CrshEvntEnbld 0 "FALSE" 1 "TRUE" ;
VAL_ 1826 TmngBltChgIndOn 0 "FALSE" 1 "TRUE" ;
VAL_ 1826 TrnsOlTmpSnsPrs 0 "FALSE" 1 "TRUE" ;
VAL_ 1826 TrlrMirVidGdlnsCstAvlFlg7 0 "FALSE" 1 "TRUE" ;
VAL_ 1826 TrlrMirVidGdlnsCstAvlFlg6 0 "FALSE" 1 "TRUE" ;
VAL_ 1826 TrlrMirVidGdlnsCstAvlFlg5 0 "FALSE" 1 "TRUE" ;
VAL_ 1421 CSI_ChmPrdcrSOH 0 "Unknown" 1 "Healthy" 2 "Faulted" ;
VAL_ 1514 ClstrDspAnmReq 0 "NoAction" 1 "Ready" 2 "WelcomePlay" 3 "StartPlay" 4 "ShutdownPlay" ;
VAL_ 1253 OATDispdVal_DuD 0 "FALSE" 1 "TRUE" ;
VAL_ 1253 IPC_LCMDataMsgStat 0 "No Action" 1 "Acknowledge" ;
VAL_ 1253 IPC_LCMFileTrans 0 "No Action" 1 "Begin Transfer" 2 "Successful Block Transfer" 3 "Cancel Transfer" 4 "Retry Last Block" ;
VAL_ 1422 HVACICRTLR_LtLvlActv 0 "FALSE" 1 "TRUE" ;
VAL_ 1422 HVACICRTLR_RtLvlActv 0 "FALSE" 1 "TRUE" ;
VAL_ 1422 HVACICRADSR_LtSet 0 "NoAction" 1 "Auto" 2 "Floor" 3 "FloorAndVent" 4 "Vent" 5 "VentAndRoof" 6 "Roof" 7 "RoofAndFloor" 8 "FloorAndVentAndRoof" ;
VAL_ 1422 HVACICRADSR_RtSet 0 "NoAction" 1 "Auto" 2 "Floor" 3 "FloorAndVent" 4 "Vent" 5 "VentAndRoof" 6 "Roof" 7 "RoofAndFloor" 8 "FloorAndVentAndRoof" ;
VAL_ 1422 HVACInfoCtlReqRrDfgSet 0 "NoAction" 1 "RearDefogOFF" 2 "RearDefogON" ;
VAL_ 1422 HVACInfoCtlReqSyncSet 0 "NoAction" 1 "SYNC_all" 2 "UnSYNC_all" 3 "SYNC_Rear_to_Driver" 4 "UnSYNC_Rear_to_Driver" 5 "SYNC_3rd_Row_to_Driver" 6 "UnSYNC_3rd_Row_to_Driver" ;
VAL_ 1422 HVACICRBLR_LvlActv 0 "FALSE" 1 "TRUE" ;
VAL_ 1422 HVACInfoCtlReqRrPwrSetChg 0 "FALSE" 1 "TRUE" ;
VAL_ 1422 HVACInfoCtlReqRrLckSetChg 0 "FALSE" 1 "TRUE" ;
VAL_ 1422 HVACInfoCtlReqRrDfgSetChg 0 "FALSE" 1 "TRUE" ;
VAL_ 1422 HVACInfoCtlReqRrAutoSetChg 0 "FALSE" 1 "TRUE" ;
VAL_ 1422 HVACInfoCtlReqBlwSpdRdct 0 "FALSE" 1 "TRUE" ;
VAL_ 1422 HVACICRADSCR_RtChgNext 0 "FALSE" 1 "TRUE" ;
VAL_ 1422 HVACICRADSCR_LtChgNext 0 "FALSE" 1 "TRUE" ;
VAL_ 1423 VirtKeyPinToStrtFobNDtd 0 "FALSE" 1 "TRUE" ;
VAL_ 1423 ChrgCommCtlrCommEnblSts 0 "No Action" 1 "Initiate Communication" 2 "Disable Communication" 3 "Restart Communication" 4 "HLC Communication" 5 "Failed" ;
VAL_ 1423 HVACInfoCtlReqSyncRrSetChg 0 "FALSE" 1 "TRUE" ;
VAL_ 1423 HVACInfoCtlReqSyncAllSetChg 0 "FALSE" 1 "TRUE" ;
